VERSION ""

NS_ :

BS_:

BU_: EHVC VESS SBWS EGP OBC LDC MCU BMS VCU CGW ECALL HVAC ACU SKM EBU TESTER BCM
VAL_TABLE_ VCU_Shift_CTRL_STS_WRN_MSG 6 "Check Gear shift control system" 5 "Charging Door open" 4 "Unplug vehicle to start" 3 "Park Malfunction" 2 "Neutral engaged" 1 "Park engaged" 0 "Off" ;
VAL_TABLE_ VCU_Shift_COND_Unmatch_WRN_MSG 4 "Press brake pedal with P release switch" 3 "Shift to P after stopping" 2 "Press brake Pedal to change gear" 1 "Shifting Condition not met(Speed/RPM)" 0 "Off" ;
VAL_TABLE_ VCU_Charging_Sts_WRN_MSG 4 "Charging System Fault" 3 "Charging Cable Inlet Fault" 2 "DC Charging System Fault" 1 "AC Charging System Fault" 0 "Off" ;
VAL_TABLE_ VCU_LV_SYS_WRN_MSG 2 "Check the LV System" 1 "Aux. Battery Saver Activated" 0 "Off" ;
VAL_TABLE_ VCU_HV_PWR_LMT_WRN_MSG 3 "Power Limited" 2 "Charge Immediately" 1 "Traction Battery Low" 0 "Off" ;
VAL_TABLE_ Med_Min_Max 2 "Maximum" 1 "Minimum" 0 "Medium" ;
VAL_TABLE_ VCU_CMD_AC_CHARG_ST_REQ 2 "HaltCharging" 1 "StartCharging" 0 "StopCharging" ;
VAL_TABLE_ VessSoundSetSts 3 "Invalid" 2 "Sound2" 1 "Sound1" 0 "NotUsed" ;
VAL_TABLE_ VessSoundSetCmd 2 "Sound2" 1 "Sound1" 0 "NoActivation" ;
VAL_TABLE_ STPMStartCmd 145 "EngineStopCmd" 95 "EngineStartCmd" 0 "NoActivation" ;
VAL_TABLE_ STPMHvacCmd 3 "Full_Aircon" 2 "Full_Heater" 1 "Off" 0 "NoActivation" ;
VAL_TABLE_ SeatBeltSts_RR 2 "Unfasten, SBR on" 3 "Invalid" 1 "Fasten, SBR off" 0 "Unfasten, SBR off" ;
VAL_TABLE_ Error_Level_0_5_EGP 15 "Invalid" 5 "Lv5" 4 "Lv4" 3 "Lv3" 2 "Lv2" 1 "Lv1" 0 "Lv0" ;
VAL_TABLE_ HVAC_Max_Sts 3 "Invalid" 2 "Other_Mode" 1 "Full_Aircon_Mode" 0 "Full_Heater_Mode" ;
VAL_TABLE_ HP_Req 3 "None Heatpump" 1 "Heatpump On" 0 "Heatpump Off" ;
VAL_TABLE_ NotOK_OK 1 "OK" 0 "NotOK" ;
VAL_TABLE_ HvacDisplayMode 15 "Invalid" 13 "Auto Def" 12 "Auto Fdef" 11 "Auto Foot" 10 "Auto Bi" 9 "Auto Vent" 8 "Auto Off" 5 "Def" 4 "Fdef" 3 "Foot" 2 "Bi" 1 "Vent" 0 "Off" ;
VAL_TABLE_ HvacDisplayRecSts 3 "Invalid" 1 "Rec" 0 "Fresh" ;
VAL_TABLE_ HvacDisplayOffSts 3 "Invalid" 2 "All Display Off" 1 "Indicator On" 0 "Indicator Off" ;
VAL_TABLE_ Shifting_In_Progress 1 "Shifting" 0 "Not Shifting" ;
VAL_TABLE_ EGP_OperationMode 4 "Error" 3 "Ready" 1 "Standby" 0 "Sleep" ;
VAL_TABLE_ LDC_Out_Mode 2 "CP" 1 "CC" 0 "CV" ;
VAL_TABLE_ HVAC_MODE_DEF_STS 3 "Def Button" 2 "ADS" 1 "Start" 0 "Off" ;
VAL_TABLE_ Off_On_Invalid 3 "Invalid" 1 "On" 0 "Off" ;
VAL_TABLE_ EHVC_OP_Mode 15 "Mode15" 14 "Mode14" 13 "Mode13" 12 "Mode12" 11 "Mode11" 10 "Mode10" 9 "Mode9" 8 "Mode8" 7 "Mode7" 6 "Mode6" 5 "Mode5" 4 "Mode4" 3 "Mode3" 2 "Mode2" 1 "Mode1" 0 "NoActivation" ;
VAL_TABLE_ DrivingPosition 7 "Invalid" 4 "L" 3 "D" 2 "N" 1 "R" 0 "P" ;
VAL_TABLE_ ECO_Guide 31 "Invalid" 16 "Power Level 10" 15 "Power Level 9" 14 "Power Level 8" 13 "Power Level 7" 12 "Power Level 6" 11 "Power Level 5" 10 "Power Level 4" 9 "Power Level 3" 7 "Power Level 2" 6 "Power Level 1" 5 "Charging Level 5" 4 "Charging Level 4" 3 "Charging Level 3" 2 "Charging Level 2" 1 "Charging Level 1" 0 "0 Level" ;
VAL_TABLE_ REGEN_EXIT 5 "RBC Fail" 4 "ABS/ESC Act" 3 "quick turn" 2 "high decel or quick brake" 1 "wheel slip" 0 "No_Activation" ;
VAL_TABLE_ HVAC_Blower_STS 15 "Invalid" 8 "8Step(Max)" 7 "7Step" 6 "6Step" 5 "5Step" 4 "4Step" 3 "3Step" 2 "2Step" 1 "1Step(Low)" 0 "Off" ;
VAL_TABLE_ HVAC_Rec_STS 2 "Partial" 15 "Invalid" 1 "Rec" 0 "Fresh" ;
VAL_TABLE_ HVAC_Mode_STS 15 "Invalid" 5 "Def" 4 "FDef" 3 "Foot" 2 "Bi" 1 "Vent" 0 "Off" ;
VAL_TABLE_ DrivingModeE100_VCU 7 "Invalid" 3 "Eco+" 2 "Sports" 1 "Normal" 0 "Eco" ;
VAL_TABLE_ SBW_STS 1 "Service_Limphome" 0 "Normal" ;
VAL_TABLE_ REQ_COAST_REGEN_EXIT 1 "ExitCoastRegen1_Ramp1_ReturnLev1" 0 "NoActivation" ;
VAL_TABLE_ VCU_STS_Paddle_LV 15 "Invalid" 3 "3 Level" 2 "2 Level" 1 "1 Level" 0 "O Level" ;
VAL_TABLE_ SBW_WRN_MSG 15 "Invalid" 8 "ShiftLockSwitchCheck" 7 "ParkingReleaseSwitchCheck" 6 "ParingSwitchCheck" 5 "WhenNotUsingShiftLockSW" 4 "WhenNotUsingTheBrake" 3 "WhenConditionIsNotP" 2 "CanNotChangeGear" 1 "Service" 0 "Off" ;
VAL_TABLE_ PW_Virtual_Flag 3 "Invalid" 2 "Virtual" 1 "Actual" 0 "NoPedal" ;
VAL_TABLE_ AC_Charging_Ready 2 "Charging Finish" 1 "Ready" 0 "NotReady" ;
VAL_TABLE_ Pmotor_Position_Status 3 "Invalid" 2 "In Between" 1 "N" 0 "P" ;
VAL_TABLE_ TCU_transPmotorparkReq 3 "Invalid" 2 "Park Request" 1 "Unpark Request" 0 "NoRequest" ;
VAL_TABLE_ SBWS_Lever 15 "Invalid" 4 "L/M" 3 "D" 2 "N" 1 "R" 0 "P" ;
VAL_TABLE_ SBWS_SW 3 "Invalid" 2 "Stuck" 1 "On" 0 "Off" ;
VAL_TABLE_ LDC_STS_MODE 3 "Derating" 2 "Failure" 1 "Fault" 0 "Normal" ;
VAL_TABLE_ LDC_STS_Ready 2 "invalid" 1 "ready" 0 "not ready" ;
VAL_TABLE_ RBC_DEF 1 "Defective" 0 "Normal" ;
VAL_TABLE_ BBC_DEF 2 "Defective" 1 "Degraded" 0 "Normal" ;
VAL_TABLE_ REGEN_ENABLE_STS 1 "Enable" 0 "Inhitition" ;
VAL_TABLE_ BMS_CoolingPumpFeedbackStatus 7 "Normal working" 6 "RPM Mismatch" 5 "Over current" 4 "Over temp" 3 "STALL" 2 "Dry run signal" 1 "PWM Wire open" 0 "Not working" ;
VAL_TABLE_ BMS_BHC_STS_OW_TS 1 "abnormality" 0 "Normal state" ;
VAL_TABLE_ BMS_BHC_STS_ERR 2 "Heater Internal Error" 1 "HV Heater Relay Coil Error" 0 "no_error" ;
VAL_TABLE_ OBC_STS_CHECK_GROUP 8 "Temporary Stop Group" 7 "System Variable Group #2" 6 "System Variable Group #1" 5 "Warnnig Group #4" 4 "Warnnig Group #3" 3 "Warnnig Group #2" 2 "Warnnig Group #1" 1 "Fault Group" 0 "Default" ;
VAL_TABLE_ OBC_STS_PC_State 5 "CV Mode" 4 "CC(In) Mode" 3 "CC(Out) Mode" 2 "CP Mode" 1 "Hot Standby Mode" 0 "Idle Mode" ;
VAL_TABLE_ OBC_STS_SC_State 6 "Charge Finish Mode" 5 "Fault Mode" 4 "Charge Mode" 3 "Precharge Mode" 2 "Handshake Mode" 1 "Init Check Mode" 0 "Main Power Off Mode" ;
VAL_TABLE_ OBC_STS_Precharge_Step 5 "Precharging done(Init Done)" 4 "PFC stage enable step(Hot Stb)" 3 "Main Relay On step" 2 "Internal link check Step" 1 "HV Check Step" 0 "Idle Step" ;
VAL_TABLE_ VCU_STS_VEH_Mode 7 "Invalid" 4 "12V Battery Auto Charging Mode" 3 "Quick(DC) Charging Mode" 2 "Scheduled Charging Mode" 1 "Normal(AC) Charging Mode" 0 "Standby" ;
VAL_TABLE_ VCU_CMD_AC_CP 6 "Stage F(-12V)" 5 "Stage E(0V)" 4 "Stage D(3V)" 3 "Stage C(6V)" 2 "Stage B2(9V)" 1 "Stage B1(9V)" 0 "Stage A(0V)" ;
VAL_TABLE_ VCU_CMD_AC_PD 2 "Open (Switch Pushed)" 1 "Detected" 0 "Not Detected" ;
VAL_TABLE_ VCU_Ready 2 "Emergency(Blinking)" 1 "Ready" 0 "Not Ready" ;
VAL_TABLE_ ECO_Energy_Flow_IND 2 "Regenerative Braking" 1 "Motoring" 0 "Stop" ;
VAL_TABLE_ Charging_Sts_IND 7 "Invalid" 5 "ChargingFailure(RedFlash)" 4 "ChargingComplete(Green)" 2 "Connection_NoCharging_ScheduledChargSet(Blue)" 1 "Connection_NoCharging(Yellow)" 0 "NoConnection_NoCharging(Off)" 3 "DuringCharging(GreenFlash)" ;
VAL_TABLE_ Charging_Plug_STS 15 "Invalid" 2 "DC Plug Connected" 1 "AC Plug Connected" 0 "Disconnected" ;
VAL_TABLE_ Inhitition_Enable 1 "Enable" 0 "Inhitition" ;
VAL_TABLE_ RemoteStartSts 3 "Invalid" 1 "RemoteRunningSts" 0 "NormalState" ;
VAL_TABLE_ NICC_SystemSts 3 "Failure" 2 "Active" 1 "Ready" 0 "Off" ;
VAL_TABLE_ NICC_Opt 3 "Invalid" 2 "On" 1 "Off" 0 "NoOption" ;
VAL_TABLE_ noDetect_Detect 3 "Invalid" 1 "Detected" 0 "No" ;
VAL_TABLE_ VoiceHvacBlowerSetCmd 15 "NoAct_Invalid" 8 "8Step(Max)" 7 "7Step" 6 "6Step" 5 "5Step" 4 "4Step" 3 "3Step" 2 "2Step" 1 "1Step(Low)" 0 "Off" ;
VAL_TABLE_ VoiceHvacUpDnCmd 2 "DnStep" 1 "UpStep" 0 "NoActivation" ;
VAL_TABLE_ VoiceHvacAirCmd 2 "RecircleAir" 1 "FreshAir" 0 "NoActivation" ;
VAL_TABLE_ VoiceHvacCmd 6 "Defrost_On" 5 "Defrost_Off" 4 "HVAC_On_with_AC_ON" 3 "HVAC_On_with_AC_OFF" 2 "HVAC_On_with_AUTO" 1 "HVAC_OFF" 0 "NoActivation" ;
VAL_TABLE_ RemoteHvacCntrlFailReason 15 "NoFail" 14 "OtherReason" 3 "EngineStop" 2 "NormalRunningState" 1 "HvacAlreadyOff" 0 "HvacAlreayOn" ;
VAL_TABLE_ RemoteHvacCmd 2 "HvacOff" 1 "HvacOn" 0 "NoActivation" ;
VAL_TABLE_ RemoteHvacResp 3 "HVAC_OFF_Fail" 2 "HVAC_OFF_Success" 1 "HVAC_ON_Fail" 0 "HVAN_ON_Success" ;
VAL_TABLE_ NotUsed_Off_On 3 "Invalid" 2 "On" 1 "Off" 0 "NotUsed" ;
VAL_TABLE_ NoDisplayDisplay 1 "Display" 0 "NoDisplay" ;
VAL_TABLE_ LKASSetCmd 2 "LKAS(RKA)" 1 "LDWS" 0 "Default" ;
VAL_TABLE_ SetCmd 3 "Invalid" 2 "On" 1 "Off" 0 "Default" ;
VAL_TABLE_ ACC_Sw 3 "Invalid" 2 "Init" 1 "Pressed" 0 "NotPressed" ;
VAL_TABLE_ CF_Yrs_Type 1 "Yaw, Lateral, Longitudinal" 0 "Yaw, Lateral" ;
VAL_TABLE_ YRS_Temp_Stat 1 "Out -40 to 85" 0 "In -40 to 85" ;
VAL_TABLE_ CF_ISC_ResetStat 1 "ISC_ResetMode" 0 "NormalMode" ;
VAL_TABLE_ NoYes 1 "Yes" 0 "No" ;
VAL_TABLE_ VariantCode 3 "Default" 2 "Yes" 0 "No" ;
VAL_TABLE_ Rheo_Stat 0 "NoActivation" ;
VAL_TABLE_ ACC_Engine_Torque_Request 1 "Enable SCC torque request" 0 "No request" ;
VAL_TABLE_ ACC_DriveMode 3 "Dynamic" 2 "Normal" 1 "Comfort" 0 "Default" ;
VAL_TABLE_ ACC_Target_Validity 1 "Valid target vehicle" 0 "No target vehicle" ;
VAL_TABLE_ ACC_Disp_Information 7 "Display 'Takeover Request'" 6 "Display 'Disable to engage ACC'" 5 "Display 'ACC disengaged'" 4 "Display 'Available to resume acceleration control'" 3 "Display 'Object disappeared'" 2 "Reserved" 1 "Display 'ACC Mode'" 0 "Default" ;
VAL_TABLE_ ACC_StopReq 1 "Stop request" 0 "No request" ;
VAL_TABLE_ ACC_DrvSel_Distance 5 "Level#5" 4 "Level#4" 3 "Level#3" 2 "Level#2" 1 "Level#1" 0 "No time gap set" ;
VAL_TABLE_ ACC_WarningLamp 3 "ACC Service Required" 2 "System temporairy unavailable" 1 "Performance degredation" 0 "Normal state" ;
VAL_TABLE_ ACC_Mode 3 "Shutoff" 2 "Override" 1 "Engaged" 0 "Off" ;
VAL_TABLE_ ESCSetCmd 5 "Sand mode (reserved)" 4 "Mud mode (reserved)" 3 "Snow mode (reserved)" 2 "Off-road mode" 1 "Normal mode" 0 "Default" ;
VAL_TABLE_ FVSASetCmd 3 "Invalid" 2 "On" 1 "Off" 0 "Default" ;
VAL_TABLE_ ESC_Mode 5 "Sand mode (reserved)" 4 "Mud mode (reserved)" 3 "Snow mode (reserved)" 2 "Off-road mode" 1 "Normal mode" 0 "Default" ;
VAL_TABLE_ Default_8bit 255 "DefaultValue" ;
VAL_TABLE_ NoAct_Off_10s_20s_30s 4 "30sec" 3 "20sec" 2 "10sec" 1 "Off" 0 "NoActivation" ;
VAL_TABLE_ NoAct_Disable_Enable 2 "Enable" 1 "Disable" 0 "NoActivation" ;
VAL_TABLE_ PTGMode 3 "Invalid" 2 "ManualMode" 1 "PowerMode" 0 "Default" ;
VAL_TABLE_ DoorLockSpeedSetCmd 5 "50kph" 4 "40kph" 3 "30kph" 2 "20kph" 1 "10kph" 0 "NoActivation" ;
VAL_TABLE_ DoorUnlockSetCmd 3 "Parking" 2 "KeyOff" 1 "Off" 0 "NoActivation" ;
VAL_TABLE_ DoorLockSetCmd 3 "ExceptParking" 2 "Driving" 1 "Off" 0 "NoActivation" ;
VAL_TABLE_ NoAct_Off_On 2 "On" 1 "Off" 0 "NoActivation" ;
VAL_TABLE_ EPB_Fail_Info 5 "EPB Permanently Not Available" 4 "EPB Temporarily Not Available" 3 "EPB Diagnostic" 2 "EPB Initialization State" 1 "EPB No failure" ;
VAL_TABLE_ EPB_Status 7 "Applying in progress by switch" 6 "Releasing in progress by switch" 5 "Dynamic braking via EPB" 4 "Releasing in progress without switch" 3 "Applying in progress without switch" 2 "Applied" 1 "Released" 0 "Unknown" ;
VAL_TABLE_ EPB_Switch 3 "Failure" 2 "Release" 1 "Apply" 0 "Neutral" ;
VAL_TABLE_ EPB_Display 5 "Push_brake_pedal_to_release_EPB" 4 "Apply_brake_immediately" 3 "EPB applies by ESC request" 2 "Driver tries to DAR but safety condition is not satisfied" 1 "EPB is in maintenance mode" 0 "Off" ;
VAL_TABLE_ EPB_Alarm 2 "Uncomfortable tone" 1 "Comfortable tone (Sound once)" 0 "Off" ;
VAL_TABLE_ AVH_DIRVER_WARNING 3 "AVH cannot be activated. Close Door, Seatbelt, Hood, Trunk" 2 "Press Brake Pedal to Release AVH" 1 "AVH to be deactivated Press Brake Pedal" 0 "No_Warning" ;
VAL_TABLE_ AVH_LAMP_INFO 3 "AVH Ready (lamp is on as white)" 2 "AVH Active (lamp is on as green)" 1 "AVH Failure (lamp is on as yellow)" 0 "AVH Off" ;
VAL_TABLE_ AVH_CTL_STATUS 2 "AVH_being_released" 1 "AVH_Active" 0 "No_Apply" ;
VAL_TABLE_ Off_On_Flashing 2 "Flashing" 1 "On" 0 "Off" ;
VAL_TABLE_ KPH_MPH 1 "MPH" 0 "KPH" ;
VAL_TABLE_ Invalid_4bit 15 "Invalid" ;
VAL_TABLE_ Invalid_11bit 2047 "Invalid value" ;
VAL_TABLE_ NoError_Error 1 "Error" 0 "NoError" ;
VAL_TABLE_ NoAct_Act 1 "Activation" 0 "No_Activation" ;
VAL_TABLE_ Init_Invalid_8bit 255 "Invalid" 254 "Init" ;
VAL_TABLE_ Off_Low_High_Invalid 3 "Invalid" 2 "High" 1 "Low" 0 "Off" ;
VAL_TABLE_ Off_On_Init_Invalid 3 "Invalid" 2 "Init" 1 "On" 0 "Off" ;
VAL_TABLE_ I_range 2 "LIN_range_3" 1 "LIN_range_2" 0 "LIN_range_1" 3 "Invalid" ;
VAL_TABLE_ NoError_Error_Init_Invalid 3 "Invalid" 2 "Init" 1 "Error" 0 "NoError" ;
VAL_TABLE_ Invalid_14bit 16383 "Invalid" ;
VAL_TABLE_ Invalid_9bit 511 "Invalid" ;
VAL_TABLE_ Invalid_16bit 65535 "Invalid" ;
VAL_TABLE_ Disable_Enable 1 "enable" 0 "disable" ;
VAL_TABLE_ FCW_SwSet 4 "Early" 7 "Invalid" 3 "Normal" 2 "Late" 1 "Disable" 0 "Default" ;
VAL_TABLE_ Defaul_Off_On_Invalid 3 "Invalid" 2 "On" 1 "Off" 0 "Default" ;
VAL_TABLE_ NoFault_Fault 1 "Fault" 0 "NoFault" ;
VAL_TABLE_ Brake_Variant 5 "ESP+EPB+AEB+ACC" 4 "ESP+EPB+AEB" 3 "ESP+AEB" 2 "ESP+EPB" 1 "ESP" 0 "ABS" ;
VAL_TABLE_ Frt_Seat_Belt_Warning 2 "SBR_Activation" 1 "SBW_Activation" 0 "NoActivation" ;
VAL_TABLE_ ESP_CtrMode 3 "Particular_Mode" 2 "Output_Torque_Overlay_Mode" 1 "Sensor_Value_Overlay_Mode" 0 "Reserve" ;
VAL_TABLE_ Close_Open_B 3 "Invalid" 2 "Init" 1 "Open" 0 "Close" ;
VAL_TABLE_ Airbag_WL_Fb 7 "Lamp circuitry failure" 3 "ACU_msg_error" 2 "Flashing" 1 "ON" 0 "OFF" ;
VAL_TABLE_ Airbag_WL 3 "Invalid" 2 "Flashing" 1 "ON" 0 "OFF" ;
VAL_TABLE_ HVAC_Option 2 "DATC" 1 "MTC" ;
VAL_TABLE_ HVAC_Mode_Status 2 "DEF" 1 "MAX" 0 "otherwise" ;
VAL_TABLE_ HVAC_Temp_Status 2 "Hi_Temp" 1 "Lo_Temp" 0 "Otherwise" ;
VAL_TABLE_ NoDef_Def 1 "Defective" 0 "Not_Defective" ;
VAL_TABLE_ NoReqeust_Request 1 "Request" 0 "NoRequest" ;
VAL_TABLE_ Invalid_10bit 1023 "Invalid value" ;
VAL_TABLE_ NotReady_Ready 1 "ready" 0 "not_ready" ;
VAL_TABLE_ TMPI_S 11 "TPM_Warning_Flash" 10 "TPM_Warning_In_Learn_Mode" 9 "Normal_Operation_OFF" ;
VAL_TABLE_ TAS 2 "Tire_Pressure_Imbalanced" 1 "Tire_Pressure_Balanced" 0 "Unknown" ;
VAL_TABLE_ TPS 7 "Invalid" 5 "High_Pressure" 4 "Puncture" 3 "Low_Warning" 2 "Low_Service_Now(Alarm)" 1 "Nominal" 0 "Unknown" ;
VAL_TABLE_ Invalid_12bit 4095 "Invalid value" ;
VAL_TABLE_ Invalid_13bit 8191 "Invalid value" ;
VAL_TABLE_ Invalid_8bit 255 "Invalid value" ;
VAL_TABLE_ Lock_Unlock_Sts 1 "Unlock" 0 "Lock" ;
VAL_TABLE_ NM_Request_Function 1 "Request" 0 "Release" ;
VAL_TABLE_ ST_REQ 3 "ST_REQ2" 1 "ST_REQ1" 0 "No_activation" ;
VAL_TABLE_ DTCInfo 3 "Invalid_Value" 2 "DTCRecordingUnitDefect" 1 "DTC_Available" 0 "No_DTC_recorded" ;
VAL_TABLE_ NM_CommandCode 4 "Limphome" 2 "Ring" 1 "Alive" ;
VAL_TABLE_ NM_FormerState 5 "LocalMode10min" 4 "LocalMode1min" 3 "LocalMode10sec" 2 "LocalModeAfterNetwork" 1 "PowerSavingMode" 0 "NoInformation" ;
VAL_TABLE_ NM_WakeupReason 3 "BatteryAttachment" 2 "LocalWakeup" 1 "RemoteWakeup" 0 "UnknownReason" ;
VAL_TABLE_ NM_SleepFlag 3 "SleepACK" 1 "NwRelease" 0 "NwRequest" ;
VAL_TABLE_ Off_On 1 "ON" 0 "OFF" ;
VAL_TABLE_ SAS_CAL 1 "Calibrated" 0 "Not Calibrated" ;
VAL_TABLE_ SAS_OK 1 "OK" 0 "Not OK" ;
VAL_TABLE_ ESP_KL 3 "ESP Warning Lamp Flashing_Active" 1 "ESP Warning Lamp On_System fault" 0 "ESP Lamp off" ;
VAL_TABLE_ VC_DriverHandle 3 "Default(Virgin)" 1 "Right Hand Drive" 0 "Left Hand Drive" ;
VAL_TABLE_ CPL_TQ_LIMIT 64255 "64255Nm" 0 "0" ;
VAL_TABLE_ RQ_Clutch_OP 3 "error" 2 "torque limit " 1 "clutch off" 0 "passive " ;
VAL_TABLE_ EBS_STATUS 3 "TCSactiveflag(TCScontrol=active)" 2 "ESPactiveflag(ESPcontro=active)" 1 "ABSactiveflag(ABScontrol=active)" 0 "normal mode" ;
VAL_TABLE_ Eng_Lamp_status 1 "symbol fault" 0 "symbol not fault" ;
VAL_TABLE_ Immofault 2 "Flashing" 1 "On" 0 "Off" ;
VAL_TABLE_ NoFail_Fail 1 "fail" 0 "no fail" ;
VAL_TABLE_ SeatBeltSts_FRT 3 "Invalid" 1 "Fasten" 0 "Unfasten" ;
VAL_TABLE_ NoAct_Act_Invalid 3 "Invalid" 1 "Activation" 0 "No_Activation" ;
VAL_TABLE_ VCU_STS_CHARG_PLG_AT_Lock_SW 3 "Invalid" 2 "Init" 1 "Lock" 0 "Auto" ;
VAL_TABLE_ IG_S 1 "ignition on" 0 "ignition off" ;
VAL_TABLE_ DOM_EXP 2 "EU export vehicle" 1 "general export vehicle" 0 "domestic vehicle" ;
VAL_TABLE_ VC_PF 22 "E100" ;
VAL_TABLE_ SMC_E_S 7 "signal not valid" 3 "charging" 2 "running" 1 "soft start" 0 "stopped" ;
VAL_TABLE_ BRAKE_ON 3 "signal not valid" 2 "not defined" 1 "brake operated" 0 "brake not operated" ;
VAL_TABLE_ TMPIR 3 "Alert_Level_3" 0 "No_Indication" ;
VAL_TABLE_ Valid_Invalid 1 "Invalid" 0 "Valid" ;
VAL_TABLE_ HDC_FL_WL 3 "not defined" 2 "blinking" 1 "turn on" 0 "turn off" ;
VAL_TABLE_ SFB 3 "signal not available" 2 "not defined_03" 1 "not defined_02" 0 "not defined_01" ;
VAL_TABLE_ DRTGHL 3 "DHL signal = invalid" 2 "not defined_02" 1 "not defined_01" 0 "DHL signal = valid" ;
VAL_TABLE_ DRTGHR 3 "DHR signal = invalid" 2 "not defined_02" 1 "not defined_01" 0 "DHR signal = valid" ;
VAL_TABLE_ ANFN 3 "not defined_03" 2 "no request" 1 "not defined_02" 0 "not defined_01" ;
VAL_TABLE_ SZS 3 "emission test mode" 2 "not defined" 1 "normal operation" 0 "disable ESP function or diag. mode" ;
VAL_TABLE_ TM_AUS 1 "auto cruise off rerquest" 0 "normal" ;
VAL_TABLE_ DRTGTM 3 "TM_DL signal = invalid" 2 "not defined_02" 1 "not defined_01" 0 "TM_DL signal = valid" ;
VAL_TABLE_ DRTGVR 3 "DVR signal = invalid" 2 "not defined_02" 1 "not defined_01" 0 "DVR signal = valid" ;
VAL_TABLE_ DRTGVL 3 "DVL signal = invalid" 2 "not defined_02" 1 "not defined_01" 0 "DVL signal = valid" ;
VAL_TABLE_ EBD_KL 1 "EBD W/L ON" 0 "EBD W/L OFF" ;
VAL_TABLE_ ABS_KL 1 "ABS W/L ON" 0 "ABS W/L OFF" ;

BO_ 3221225472 VECTOR__INDEPENDENT_SIG_MSG: 0 Vector__XXX
 SG_ IgnitionSts : 0|2@0+ (1,0) [0|3] "" Vector__XXX
 SG_ SafetyUnlockSetSts : 0|1@0+ (1,0) [0|1] "" Vector__XXX
 SG_ ACC_RequiredAccel : 0|11@0+ (0.01,-10.23) [-10.23|10.24] "m/s^2" Vector__XXX
 SG_ ESCSetCmd : 0|3@0+ (1,0) [0|7] "" Vector__XXX
 SG_ TCU_ISGStat_allow_PA : 0|1@0+ (1,0) [0|1] "" Vector__XXX
 SG_ ACC_StopReq : 0|1@0+ (1,0) [0|1] "" Vector__XXX
 SG_ DGN_REQ_SAS : 0|64@0+ (1,0) [0|0] "" Vector__XXX
 SG_ ALT_FB : 0|8@0+ (0.4,0) [0|100] "%" Vector__XXX
 SG_ TCU_ISGStat_ready : 0|1@0+ (1,0) [0|1] "" Vector__XXX
 SG_ TCU_Cal_1 : 0|64@0+ (1,0) [0|0] "" Vector__XXX
 SG_ NTURBINE : 0|16@0+ (1,0) [0|65535] "1/min" Vector__XXX
 SG_ MABS_SW_ANFB : 0|16@0+ (1,0) [0|65535] "1nm" Vector__XXX
 SG_ VB : 0|16@0+ (0.1,0) [0|6553.5] "uL/100ms" Vector__XXX
 SG_ T_MOT : 0|8@0+ (1,-40) [-40|215] "deg C." Vector__XXX

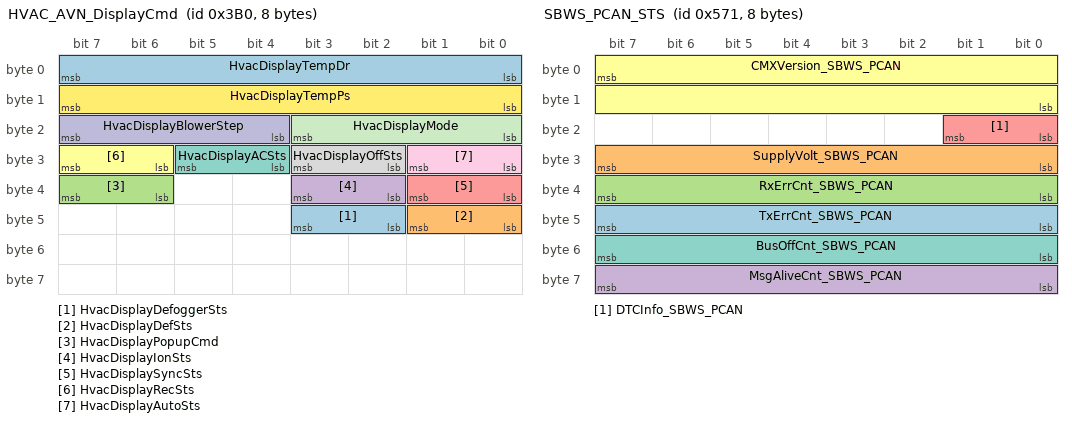
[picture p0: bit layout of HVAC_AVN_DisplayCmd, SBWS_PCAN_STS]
BO_ 944 HVAC_AVN_DisplayCmd: 8 HVAC
 SG_ HvacDisplayDefoggerSts : 43|2@0+ (1,0) [0|3] ""  CGW
 SG_ HvacDisplayDefSts : 41|2@0+ (1,0) [0|3] ""  CGW
 SG_ HvacDisplayPopupCmd : 39|2@0+ (1,0) [0|3] ""  CGW
 SG_ HvacDisplayIonSts : 35|2@0+ (1,0) [0|3] ""  CGW
 SG_ HvacDisplaySyncSts : 33|2@0+ (1,0) [0|3] ""  CGW
 SG_ HvacDisplayRecSts : 31|2@0+ (1,0) [0|3] ""  CGW
 SG_ HvacDisplayACSts : 29|2@0+ (1,0) [0|3] ""  CGW
 SG_ HvacDisplayOffSts : 27|2@0+ (1,0) [0|3] ""  CGW
 SG_ HvacDisplayAutoSts : 25|2@0+ (1,0) [0|3] ""  CGW
 SG_ HvacDisplayBlowerStep : 23|4@0+ (1,0) [0|15] ""  CGW
 SG_ HvacDisplayMode : 19|4@0+ (1,0) [0|15] ""  CGW
 SG_ HvacDisplayTempPs : 15|8@0+ (0.5,17.5) [17.5|32.5] "deg Cel."  CGW
 SG_ HvacDisplayTempDr : 7|8@0+ (0.5,17.5) [17.5|32.5] "deg Cel."  CGW

BO_ 1732 MCU_CAL_RESP: 8 MCU
 SG_ MCU_Calibration_Resp : 7|64@0+ (1,0) [0|0] ""  CGW

BO_ 1668 MCU_CAL_REQ: 8 CGW
 SG_ MCU_Calibration_Req : 7|64@0+ (1,0) [0|0] ""  MCU

BO_ 807 MCU_327h: 8 MCU
 SG_ MCU_PowerConsumption : 33|10@0+ (1,-300) [-300|300] "kW"  VCU,CGW
 SG_ HighPowerVoltage : 18|11@0+ (1,0) [0|2046] "V"  CGW
 SG_ HighPowerCurrent : 5|14@0+ (0.25,-2048) [-2046|2046] "A"  CGW
 SG_ MCU_Service_WRN_IND : 6|1@0+ (1,0) [0|1] ""  CGW,VCU

BO_ 1393 SBWS_PCAN_STS: 8 SBWS
 SG_ TxErrCnt_SBWS_PCAN : 47|8@0+ (1,0) [0|255] "" Vector__XXX
 SG_ SupplyVolt_SBWS_PCAN : 31|8@0+ (0.1,0) [0|25.5] "V" Vector__XXX
 SG_ RxErrCnt_SBWS_PCAN : 39|8@0+ (1,0) [0|255] "" Vector__XXX
 SG_ MsgAliveCnt_SBWS_PCAN : 63|8@0+ (1,0) [0|255] "" Vector__XXX
 SG_ DTCInfo_SBWS_PCAN : 17|2@0+ (1,0) [0|3] "" Vector__XXX
 SG_ CMXVersion_SBWS_PCAN : 7|16@0+ (1,0) [0|65535] "" Vector__XXX
 SG_ BusOffCnt_SBWS_PCAN : 55|8@0+ (1,0) [0|255] "" Vector__XXX

BO_ 1913 SBWS_DGN_RESP: 8 SBWS
 SG_ DGN_SBWS_RESP : 7|64@0+ (1,0) [0|0] ""  CGW

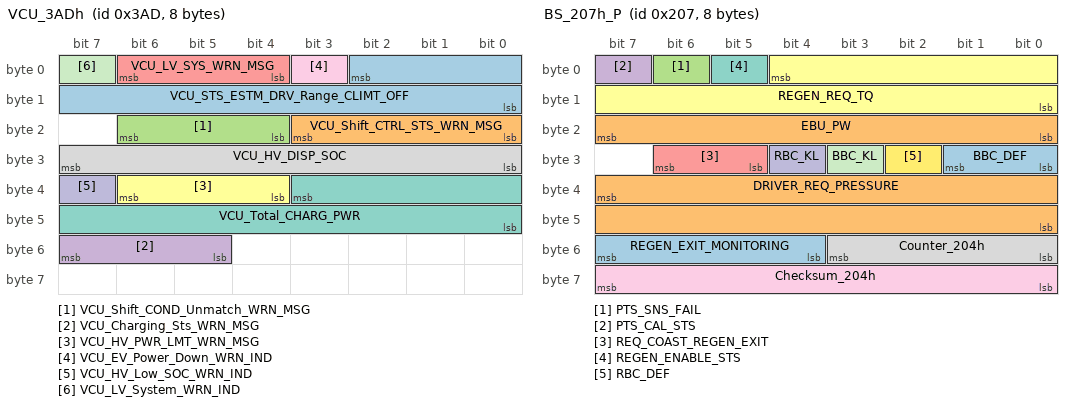
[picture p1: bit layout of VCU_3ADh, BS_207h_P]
BO_ 941 VCU_3ADh: 8 VCU
 SG_ VCU_STS_ESTM_DRV_Range_CLIMT_OFF : 2|11@0+ (1,0) [0|2000] "km"  CGW
 SG_ VCU_Shift_CTRL_STS_WRN_MSG : 19|4@0+ (1,0) [0|6] ""  CGW
 SG_ VCU_Shift_COND_Unmatch_WRN_MSG : 22|3@0+ (1,0) [0|4] ""  CGW
 SG_ VCU_Charging_Sts_WRN_MSG : 55|3@0+ (1,0) [0|4] ""  CGW
 SG_ VCU_LV_SYS_WRN_MSG : 6|3@0+ (1,0) [0|2] ""  CGW
 SG_ VCU_HV_PWR_LMT_WRN_MSG : 38|3@0+ (1,0) [0|3] ""  CGW
 SG_ VCU_Total_CHARG_PWR : 35|12@0+ (0.1,0) [0|255] "kW"  CGW
 SG_ VCU_HV_DISP_SOC : 31|8@0+ (1,0) [0|100] "%"  CGW
 SG_ VCU_EV_Power_Down_WRN_IND : 3|1@0+ (1,0) [0|1] ""  CGW
 SG_ VCU_HV_Low_SOC_WRN_IND : 39|1@0+ (1,0) [0|1] ""  CGW
 SG_ VCU_LV_System_WRN_IND : 7|1@0+ (1,0) [0|1] ""  CGW

BO_ 851 BMS_353h: 8 BMS
 SG_ BMS_BHC_Power : 23|16@0+ (1,0) [0|65535] "W"  BMS
 SG_ BMS_InstantPowerConsumption : 7|16@0+ (0.1,-400) [-400|400] "kW"  CGW

BO_ 882 CGW_372h: 8 CGW
 SG_ GoodbyeSoundCmd : 7|2@0+ (1,0) [0|3] ""  VESS
 SG_ WelcomeSoundCmd : 5|2@0+ (1,0) [0|3] ""  VESS
 SG_ HazardSw : 1|1@0+ (1,0) [0|1] ""  VCU
 SG_ HeadLampHighSts : 0|1@0+ (1,0) [0|1] ""  VCU
 SG_ RainDetected : 3|2@0+ (1,0) [0|3] ""  HVAC

BO_ 836 VESS_344h: 8 VESS
 SG_ VessSoundSetSts : 5|2@0+ (1,0) [0|3] ""  CGW
 SG_ VesstWarnCmd : 1|2@0+ (1,0) [0|1] ""  CGW
 SG_ VessWelcomeOnOffSetSts : 3|2@0+ (1,0) [0|3] ""  CGW

BO_ 1394 VESS_PCAN_STS: 8 VESS
 SG_ MsgAliveCnt_VESS_PCAN : 63|8@0+ (1,0) [0|255] "" Vector__XXX
 SG_ BusOffCnt_VESS_PCAN : 55|8@0+ (1,0) [0|255] "" Vector__XXX
 SG_ TxErrCnt_VESS_PCAN : 47|8@0+ (1,0) [0|255] "" Vector__XXX
 SG_ RxErrCnt_VESS_PCAN : 39|8@0+ (1,0) [0|255] "" Vector__XXX
 SG_ SupplyVolt_VESS_PCAN : 31|8@0+ (0.1,0) [0|25.5] "V" Vector__XXX
 SG_ DTCInfo_VESS_PCAN : 17|2@0+ (1,0) [0|3] ""  CGW
 SG_ CMXVersion_VESS_PCAN : 7|16@0+ (1,0) [0|65535] "" Vector__XXX

BO_ 1905 SBWS_DGN_REQ: 8 CGW
 SG_ DGN_SBWS_REQ : 7|64@0+ (1,0) [0|0] ""  SBWS

BO_ 854 HVAC_356h: 8 HVAC
 SG_ HVAC_Sensor_DUCT : 39|16@0+ (0.1,-40) [-40|100] "del Cel."  EHVC
 SG_ HVAC_Sensor_EVA : 23|16@0+ (0.1,-40) [-40|100] "del Cel."  EHVC
 SG_ HVAC_Sensor_SUN : 15|8@0+ (5,0) [0|1270] "W2/m"  EHVC
 SG_ HVAC_Sensor_AMB : 55|16@0+ (0.1,-40) [-40|100] "del Cel."  EHVC
 SG_ HVAC_Sensor_ADS : 7|8@0+ (1,0) [0|100] "%"  EHVC

BO_ 492 EHVC_1ECh: 8 EHVC
 SG_ AC_REF_OutHEX_Temp : 31|8@0+ (1,-40) [-40|214] "del Cel."  HVAC
 SG_ AC_REF_Low_Temp : 23|8@0+ (1,-40) [-40|214] "del Cel."  HVAC
 SG_ AC_REF_Low_Pressure : 33|10@0+ (0.1,0) [0|102.4] "bar"  HVAC
 SG_ AC_REF_High_Temp : 7|8@0+ (1,-40) [-40|214] "del Cel."  HVAC

BO_ 1894 EHVC_DGN_REQ: 8 CGW
 SG_ DGN_REQ_EHVC : 7|64@0+ (1,0) [0|0] ""  EHVC

BO_ 1893 EGP_DGN_REQ: 8 CGW
 SG_ DGN_REQ_EGP : 7|64@0+ (1,0) [0|0] ""  EGP

BO_ 1892 OBC_DGN_REQ: 8 CGW
 SG_ DGN_REQ_OBC : 7|64@0+ (1,0) [0|0] ""  OBC

BO_ 1891 LDC_DGN_REQ: 8 CGW
 SG_ DGN_REQ_LDC : 7|64@0+ (1,0) [0|0] ""  LDC

BO_ 1890 MCU_DGN_REQ: 8 CGW
 SG_ DGN_REQ_MCU : 7|64@0+ (1,0) [0|0] ""  MCU

BO_ 1889 BMS_DGN_REQ: 8 CGW
 SG_ DGN_REQ_BMS : 7|64@0+ (1,0) [0|0] ""  BMS

BO_ 1857 VESS_DGN_REQ: 8 CGW
 SG_ DGN_REQ_VESS : 7|64@0+ (1,0) [0|0] ""  VESS

BO_ 491 EHVC_1EBh: 8 EHVC
 SG_ Cabin_HTR_Power : 17|10@0+ (20,0) [0|20440] "W"  VCU
 SG_ AC_REF_High_Pressure : 7|10@0+ (0.1,0) [0|102.4] "bar"  HVAC,VCU

BO_ 519 BS_207h_P: 8 EBU
 SG_ REGEN_EXIT_MONITORING : 55|4@0+ (1,0) [0|16] ""  VCU
 SG_ DRIVER_REQ_PRESSURE : 39|16@0+ (0.1,0) [0|6553.5] "bar"  VCU
 SG_ PTS_SNS_FAIL : 6|1@0+ (1,0) [0|1] ""  MCU,VCU
 SG_ PTS_CAL_STS : 7|1@0+ (1,0) [0|1] "" Vector__XXX
 SG_ REQ_COAST_REGEN_EXIT : 30|2@0+ (1,0) [0|3] ""  VCU
 SG_ REGEN_REQ_TQ : 4|13@0+ (1,-500) [-500|7691] "Nm"  VCU
 SG_ REGEN_ENABLE_STS : 5|1@0+ (1,0) [0|1] ""  MCU,VCU
 SG_ Counter_204h : 51|4@0+ (1,0) [0|15] ""  VCU
 SG_ Checksum_204h : 63|8@0+ (1,0) [0|255] ""  VCU
 SG_ RBC_KL : 28|1@0+ (1,0) [0|1] "" Vector__XXX
 SG_ BBC_KL : 27|1@0+ (1,0) [0|1] "" Vector__XXX
 SG_ RBC_DEF : 26|1@0+ (1,0) [0|1] ""  VCU
 SG_ BBC_DEF : 25|2@0+ (1,0) [0|3] "" Vector__XXX
 SG_ EBU_PW : 23|8@0+ (1,0) [0|100] "%"  MCU,VCU

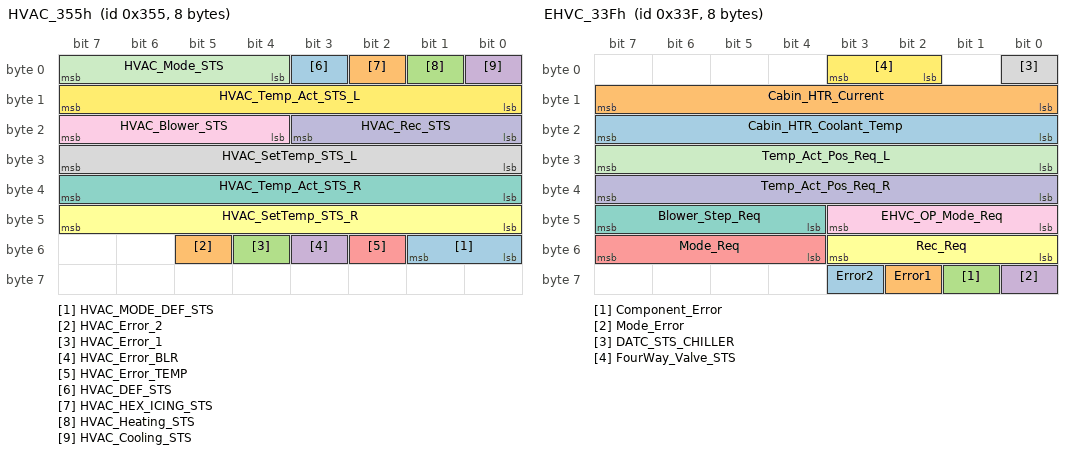
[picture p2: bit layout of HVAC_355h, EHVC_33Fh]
BO_ 853 HVAC_355h: 8 HVAC
 SG_ HVAC_MODE_DEF_STS : 49|2@0+ (1,0) [0|3] ""  EHVC
 SG_ HVAC_Error_2 : 53|1@0+ (1,0) [0|3] ""  EHVC
 SG_ HVAC_Error_1 : 52|1@0+ (1,0) [0|3] ""  EHVC
 SG_ HVAC_Error_BLR : 51|1@0+ (1,0) [0|3] ""  EHVC
 SG_ HVAC_Error_TEMP : 50|1@0+ (1,0) [0|3] ""  EHVC
 SG_ HVAC_SetTemp_STS_R : 47|8@0+ (0.5,17.5) [17.5|32.5] "del Cel."  EHVC
 SG_ HVAC_Temp_Act_STS_R : 39|8@0+ (1,0) [0|100] "%"  VCU,EHVC
 SG_ HVAC_SetTemp_STS_L : 31|8@0+ (0.5,17.5) [17.5|32.5] "del Cel."  EHVC
 SG_ HVAC_Blower_STS : 23|4@0+ (1,0) [0|3] ""  EHVC
 SG_ HVAC_Rec_STS : 19|4@0+ (1,0) [0|3] ""  EHVC
 SG_ HVAC_Mode_STS : 7|4@0+ (1,0) [0|15] ""  EHVC
 SG_ HVAC_Temp_Act_STS_L : 15|8@0+ (1,0) [0|100] "&"  VCU,EHVC
 SG_ HVAC_DEF_STS : 3|1@0+ (1,0) [0|1] ""  VCU
 SG_ HVAC_HEX_ICING_STS : 2|1@0+ (1,0) [0|1] ""  VCU
 SG_ HVAC_Heating_STS : 1|1@0+ (1,0) [0|1] ""  VCU
 SG_ HVAC_Cooling_STS : 0|1@0+ (1,0) [0|1] ""  VCU

BO_ 831 EHVC_33Fh: 8 EHVC
 SG_ Error2 : 59|1@0+ (1,0) [0|1] ""  HVAC
 SG_ Error1 : 58|1@0+ (1,0) [0|1] ""  HVAC
 SG_ Component_Error : 57|1@0+ (1,0) [0|1] ""  HVAC
 SG_ Mode_Error : 56|1@0+ (1,0) [0|1] ""  HVAC
 SG_ Mode_Req : 55|4@0+ (1,0) [0|15] ""  HVAC
 SG_ Rec_Req : 51|4@0+ (1,0) [0|15] ""  HVAC
 SG_ Blower_Step_Req : 47|4@0+ (1,0) [0|15] ""  HVAC
 SG_ DATC_STS_CHILLER : 0|1@0+ (1,0) [0|1] ""  VCU
 SG_ EHVC_OP_Mode_Req : 43|4@0+ (1,0) [0|15] ""  HVAC
 SG_ Temp_Act_Pos_Req_R : 39|8@0+ (1,0) [0|100] "%"  HVAC
 SG_ Temp_Act_Pos_Req_L : 31|8@0+ (1,0) [0|100] "%"  HVAC
 SG_ FourWay_Valve_STS : 3|2@0+ (1,0) [0|3] ""  HVAC
 SG_ Cabin_HTR_Coolant_Temp : 23|8@0+ (1,-40) [-40|214] "deg Cel"  HVAC
 SG_ Cabin_HTR_Current : 15|8@0+ (0.25,0) [0|63.5] "A"  CGW,VCU

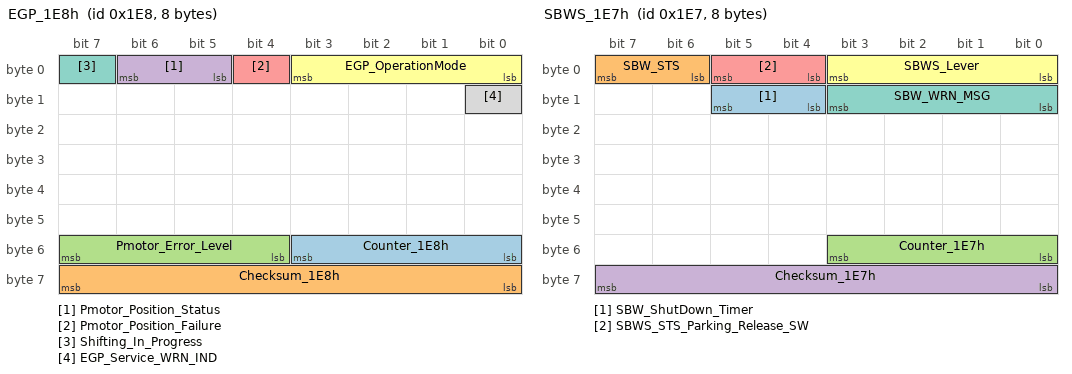
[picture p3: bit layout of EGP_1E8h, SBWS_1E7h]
BO_ 488 EGP_1E8h: 8 EGP
 SG_ Counter_1E8h : 51|4@0+ (1,0) [0|15] ""  VCU
 SG_ Checksum_1E8h : 63|8@0+ (1,0) [0|255] ""  VCU
 SG_ Pmotor_Error_Level : 55|4@0+ (1,0) [0|15] ""  VCU
 SG_ Pmotor_Position_Status : 6|2@0+ (1,0) [0|5] ""  VCU
 SG_ Pmotor_Position_Failure : 4|1@0+ (1,0) [0|1] ""  VCU
 SG_ EGP_OperationMode : 3|4@0+ (1,0) [0|15] ""  VCU
 SG_ Shifting_In_Progress : 7|1@0+ (1,0) [0|1] ""  VCU
 SG_ EGP_Service_WRN_IND : 8|1@0+ (1,0) [0|1] ""  CGW,VCU

BO_ 487 SBWS_1E7h: 8 SBWS
 SG_ SBW_ShutDown_Timer : 13|2@0+ (1,0) [0|1] ""  VCU
 SG_ SBW_STS : 7|2@0+ (1,0) [0|1] ""  VCU
 SG_ Counter_1E7h : 51|4@0+ (1,0) [0|15] ""  VCU
 SG_ Checksum_1E7h : 63|8@0+ (1,0) [0|255] ""  VCU
 SG_ SBWS_STS_Parking_Release_SW : 5|2@0+ (1,0) [0|3] ""  VCU
 SG_ SBWS_Lever : 3|4@0+ (1,0) [0|15] ""  VCU
 SG_ SBW_WRN_MSG : 11|4@0+ (1,0) [0|15] ""  VCU,CGW

BO_ 929 LDC_3A1h: 8 LDC
 SG_ LDC_STS_CURR_OUT : 39|16@0+ (0.1,0) [0|1000] "A"  VCU
 SG_ LDC_STS_CURR_IN : 31|8@0+ (0.1,0) [0|25] "A"  VCU
 SG_ LDC_STS_VOLT_OUT : 23|8@0+ (0.1,0) [0|25] "V"  VCU
 SG_ LDC_STS_VOLT_IN : 7|16@0+ (0.1,0) [0|1000] "V"  VCU

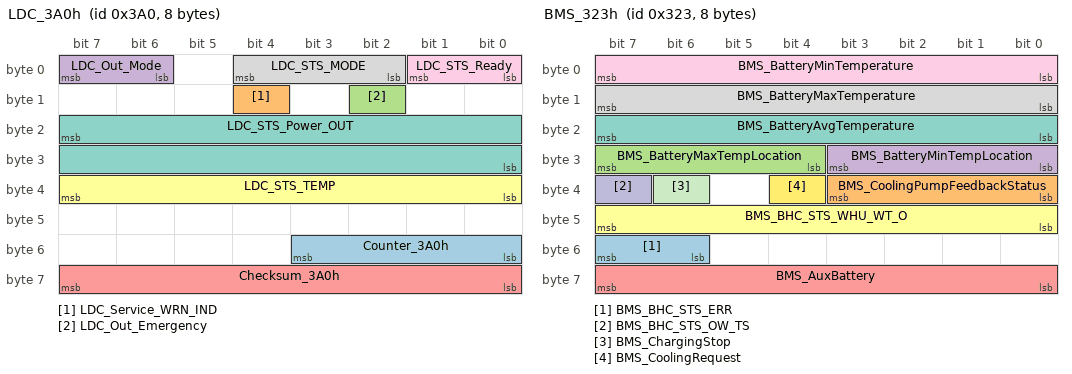
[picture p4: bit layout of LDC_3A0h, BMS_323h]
BO_ 928 LDC_3A0h: 8 LDC
 SG_ Counter_3A0h : 51|4@0+ (1,0) [0|15] ""  VCU
 SG_ LDC_Service_WRN_IND : 12|1@0+ (1,0) [0|1] ""  CGW,VCU
 SG_ LDC_Out_Emergency : 10|1@0+ (1,0) [0|1] ""  CGW,VCU
 SG_ LDC_Out_Mode : 7|2@0+ (1,0) [0|2] ""  VCU
 SG_ Checksum_3A0h : 63|8@0+ (1,0) [0|255] ""  VCU
 SG_ LDC_STS_TEMP : 39|8@0+ (1,-40) [-40|200] "del Cel"  VCU
 SG_ LDC_STS_Power_OUT : 23|16@0+ (1,0) [0|1800] "W"  CGW,VCU
 SG_ LDC_STS_MODE : 4|3@0+ (1,0) [0|3] ""  VCU
 SG_ LDC_STS_Ready : 1|2@0+ (1,0) [0|2] ""  VCU

BO_ 803 BMS_323h: 8 BMS
 SG_ BMS_BHC_STS_ERR : 55|2@0+ (1,0) [0|2] "" Vector__XXX
 SG_ BMS_CoolingPumpFeedbackStatus : 35|4@0+ (1,0) [0|7] "" Vector__XXX
 SG_ BMS_BatteryMaxTempLocation : 31|4@0+ (1,0) [0|10] "" Vector__XXX
 SG_ BMS_BatteryMinTempLocation : 27|4@0+ (1,0) [0|10] "" Vector__XXX
 SG_ BMS_AuxBattery : 63|8@0+ (0.1,0) [0|19] "V" Vector__XXX
 SG_ BMS_BHC_STS_WHU_WT_O : 47|8@0+ (0.6,-40) [-40|112.4] "deg Cel" Vector__XXX
 SG_ BMS_BatteryAvgTemperature : 23|8@0+ (1,-40) [-40|210] "deg Cel"  HVAC,EHVC
 SG_ BMS_BatteryMaxTemperature : 15|8@0+ (1,-40) [-40|210] "deg Cel"  HVAC,EHVC
 SG_ BMS_BatteryMinTemperature : 7|8@0+ (1,-40) [-40|210] "deg Cel"  HVAC,EHVC
 SG_ BMS_BHC_STS_OW_TS : 39|1@0+ (1,0) [0|1] "" Vector__XXX
 SG_ BMS_ChargingStop : 38|1@0+ (1,0) [0|1] "" Vector__XXX
 SG_ BMS_CoolingRequest : 36|1@0+ (1,0) [0|1] ""  EHVC

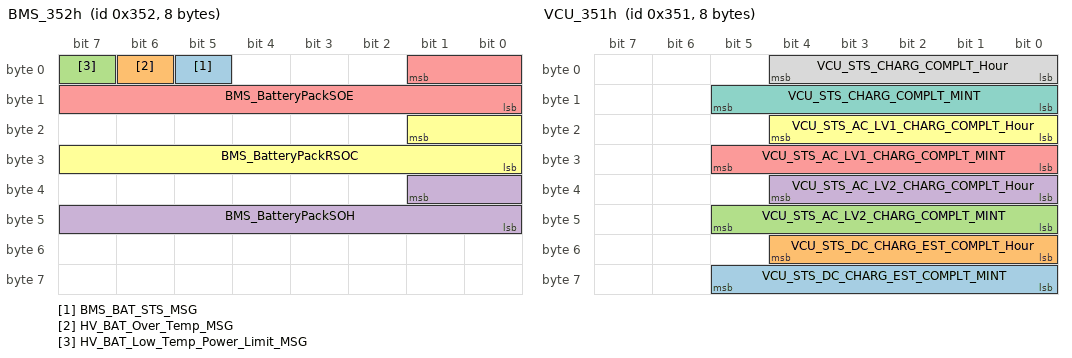
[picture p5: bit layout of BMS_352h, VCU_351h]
BO_ 850 BMS_352h: 8 BMS
 SG_ BMS_BAT_STS_MSG : 5|1@0+ (1,0) [0|1] ""  CGW
 SG_ HV_BAT_Over_Temp_MSG : 6|1@0+ (1,0) [0|1] ""  CGW
 SG_ HV_BAT_Low_Temp_Power_Limit_MSG : 7|1@0+ (1,0) [0|1] ""  CGW
 SG_ BMS_BatteryPackSOH : 33|10@0+ (0.1,0) [0|100] "%"  VCU,CGW
 SG_ BMS_BatteryPackSOE : 1|10@0+ (0.1,0) [0|65] "kWh"  VCU,CGW
 SG_ BMS_BatteryPackRSOC : 17|10@0+ (0.1,0) [0|100] "%"  VCU,CGW

BO_ 849 VCU_351h: 8 VCU
 SG_ VCU_STS_DC_CHARG_EST_COMPLT_MINT : 61|6@0+ (1,0) [0|59] "minute"  CGW
 SG_ VCU_STS_DC_CHARG_EST_COMPLT_Hour : 52|5@0+ (1,0) [0|31] "clock"  CGW
 SG_ VCU_STS_AC_LV2_CHARG_COMPLT_MINT : 45|6@0+ (1,0) [0|59] "minute"  CGW
 SG_ VCU_STS_AC_LV2_CHARG_COMPLT_Hour : 36|5@0+ (1,0) [0|31] "clock"  CGW
 SG_ VCU_STS_AC_LV1_CHARG_COMPLT_MINT : 29|6@0+ (1,0) [0|59] "minute"  CGW
 SG_ VCU_STS_AC_LV1_CHARG_COMPLT_Hour : 20|5@0+ (1,0) [0|31] "clock"  CGW
 SG_ VCU_STS_CHARG_COMPLT_MINT : 13|6@0+ (1,0) [0|59] "minute"  CGW
 SG_ VCU_STS_CHARG_COMPLT_Hour : 4|5@0+ (1,0) [0|31] "clock"  CGW

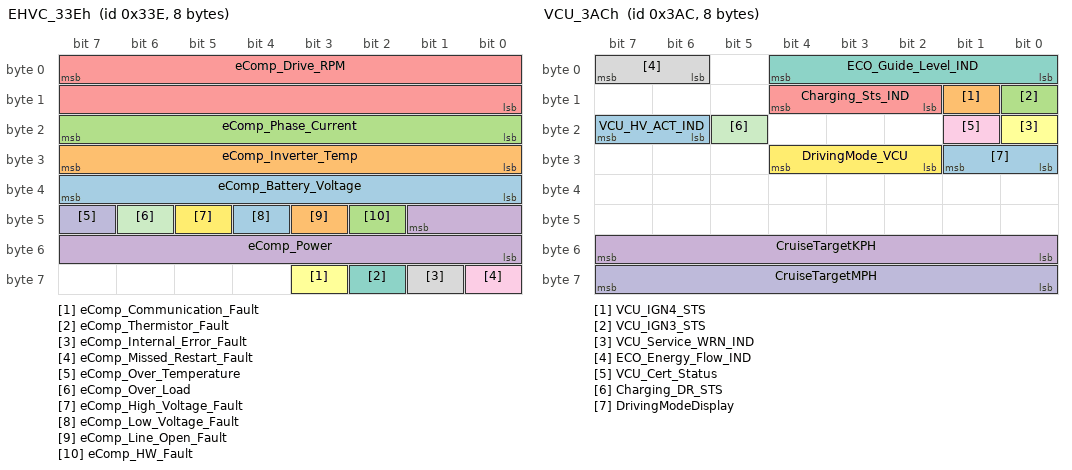
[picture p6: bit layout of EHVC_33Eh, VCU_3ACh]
BO_ 830 EHVC_33Eh: 8 EHVC
 SG_ eComp_Battery_Voltage : 39|8@0+ (2,0) [0|508] ""  VCU
 SG_ eComp_Inverter_Temp : 31|8@0+ (1,-40) [-40|150] "del Cel"  VCU
 SG_ eComp_Phase_Current : 23|8@0+ (0.1,0) [0|25.4] "A"  VCU
 SG_ eComp_Power : 41|10@0+ (10,0) [0|10230] "W"  VCU
 SG_ eComp_Drive_RPM : 7|16@0+ (1,0) [0|9000] "r/min"  VCU
 SG_ eComp_Communication_Fault : 59|1@0+ (1,0) [0|1] ""  HVAC
 SG_ eComp_Thermistor_Fault : 58|1@0+ (1,0) [0|1] ""  HVAC
 SG_ eComp_Internal_Error_Fault : 57|1@0+ (1,0) [0|1] ""  HVAC
 SG_ eComp_Missed_Restart_Fault : 56|1@0+ (1,0) [0|1] ""  HVAC
 SG_ eComp_Over_Temperature : 47|1@0+ (1,0) [0|1] ""  HVAC
 SG_ eComp_Over_Load : 46|1@0+ (1,0) [0|1] ""  HVAC
 SG_ eComp_High_Voltage_Fault : 45|1@0+ (1,0) [0|1] ""  HVAC
 SG_ eComp_Low_Voltage_Fault : 44|1@0+ (1,0) [0|1] ""  HVAC
 SG_ eComp_Line_Open_Fault : 43|1@0+ (1,0) [0|1] ""  HVAC
 SG_ eComp_HW_Fault : 42|1@0+ (1,0) [0|1] ""  HVAC

BO_ 940 VCU_3ACh: 8 VCU
 SG_ VCU_HV_ACT_IND : 23|2@0+ (1,0) [0|1] ""  CGW
 SG_ VCU_IGN4_STS : 9|1@0+ (1,0) [0|1] ""  EHVC,HVAC,LDC
 SG_ VCU_IGN3_STS : 8|1@0+ (1,0) [0|1] ""  LDC
 SG_ CruiseTargetKPH : 55|8@0+ (1,0) [0|255] "km/h"  CGW
 SG_ Charging_Sts_IND : 12|3@0+ (1,0) [0|5] ""  VESS,CGW
 SG_ VCU_Service_WRN_IND : 16|1@0+ (1,0) [0|1] ""  CGW
 SG_ ECO_Guide_Level_IND : 4|5@0+ (1,0) [0|31] "Step"  CGW
 SG_ ECO_Energy_Flow_IND : 7|2@0+ (1,0) [0|2] ""  CGW
 SG_ VCU_Cert_Status : 17|1@0+ (1,0) [0|1] ""  EBU,CGW
 SG_ CruiseTargetMPH : 63|8@0+ (1,0) [0|255] "mile/h"  CGW
 SG_ Charging_DR_STS : 21|1@0+ (1,0) [0|2] ""  CGW
 SG_ DrivingMode_VCU : 28|3@0+ (1,0) [0|3] ""  CGW
 SG_ DrivingModeDisplay : 25|2@0+ (1,0) [0|1] ""  CGW

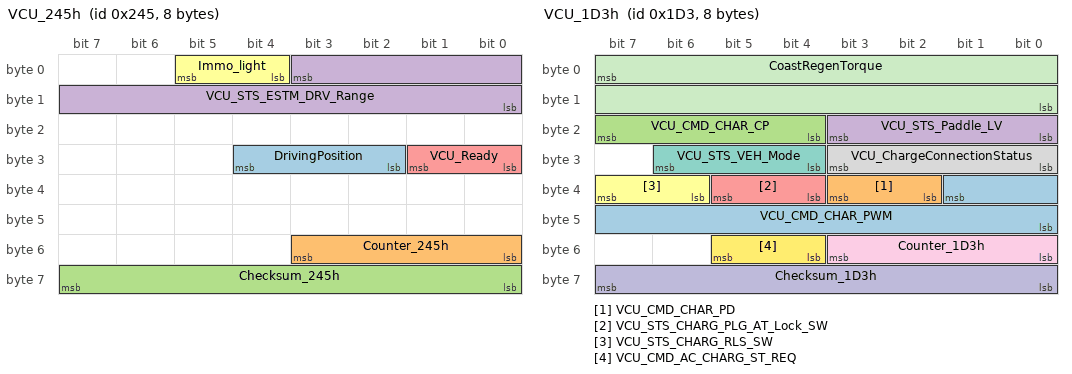
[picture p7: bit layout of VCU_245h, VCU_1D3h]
BO_ 581 VCU_245h: 8 VCU
 SG_ DrivingPosition : 28|3@0+ (1,0) [0|4] ""  VESS,BCM,CGW,SBWS,SKM
 SG_ Counter_245h : 51|4@0+ (1,0) [0|15] ""  SBWS,CGW
 SG_ Checksum_245h : 63|8@0+ (1,0) [0|255] ""  CGW,SBWS
 SG_ VCU_STS_ESTM_DRV_Range : 3|12@0+ (1,0) [0|4095] "km"  CGW
 SG_ VCU_Ready : 25|2@0+ (1,0) [0|2] ""  CGW,EHVC,EBU,ECALL,HVAC,LDC,MCU,OBC,SBWS
 SG_ Immo_light : 5|2@0+ (1,0) [0|2] ""  CGW

BO_ 467 VCU_1D3h: 8 VCU
 SG_ VCU_CMD_CHAR_PWM : 33|10@0+ (0.1,0) [0|100] "%"  OBC
 SG_ VCU_CMD_CHAR_PD : 35|2@0+ (1,0) [0|2] ""  OBC
 SG_ VCU_CMD_CHAR_CP : 23|4@0+ (1,0) [0|6] ""  OBC
 SG_ VCU_STS_Paddle_LV : 19|4@0+ (1,0) [0|3] ""  CGW
 SG_ VCU_STS_CHARG_PLG_AT_Lock_SW : 37|2@0+ (1,0) [0|2] ""  CGW
 SG_ VCU_STS_CHARG_RLS_SW : 39|2@0+ (1,0) [0|2] ""  CGW
 SG_ VCU_STS_VEH_Mode : 30|3@0+ (1,0) [0|4] ""  CGW
 SG_ VCU_ChargeConnectionStatus : 27|4@0+ (1,0) [0|2] ""  BMS,CGW
 SG_ Counter_1D3h : 51|4@0+ (1,0) [0|15] ""  BMS
 SG_ Checksum_1D3h : 63|8@0+ (1,0) [0|255] ""  BMS
 SG_ CoastRegenTorque : 7|16@0+ (1,-32760) [-32760|32760] ""  EBU
 SG_ VCU_CMD_AC_CHARG_ST_REQ : 53|2@0+ (1,0) [0|2] ""  OBC

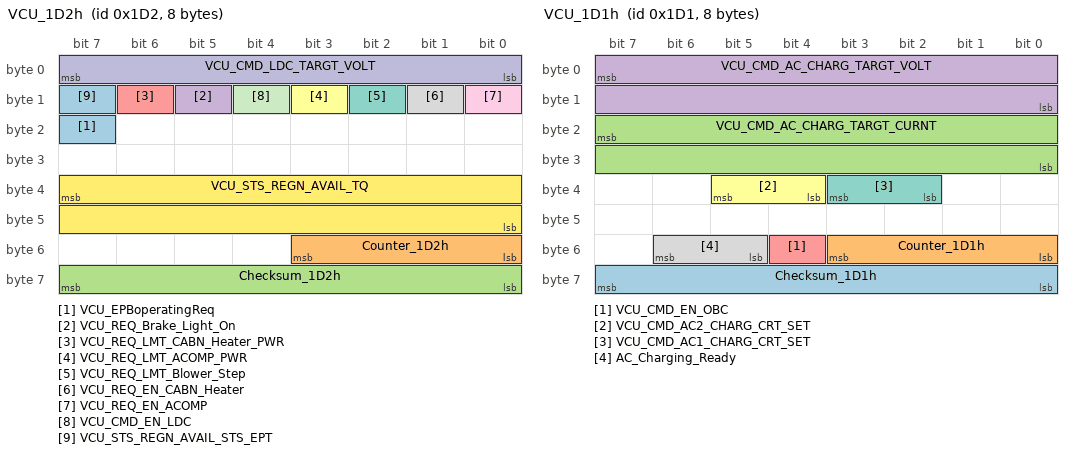
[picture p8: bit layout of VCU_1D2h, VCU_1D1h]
BO_ 466 VCU_1D2h: 8 VCU
 SG_ VCU_EPBoperatingReq : 23|1@0+ (1,0) [0|1] ""  EBU
 SG_ Counter_1D2h : 51|4@0+ (1,0) [0|15] ""  OBC
 SG_ Checksum_1D2h : 63|8@0+ (1,0) [0|255] ""  OBC
 SG_ VCU_REQ_Brake_Light_On : 13|1@0+ (1,0) [0|1] ""  BCM
 SG_ VCU_REQ_LMT_CABN_Heater_PWR : 14|1@0+ (1,0) [0|1] ""  EHVC
 SG_ VCU_REQ_LMT_ACOMP_PWR : 11|1@0+ (1,0) [0|1] ""  EHVC
 SG_ VCU_REQ_LMT_Blower_Step : 10|1@0+ (1,0) [0|1] ""  HVAC
 SG_ VCU_REQ_EN_CABN_Heater : 9|1@0+ (1,0) [0|1] ""  EHVC
 SG_ VCU_REQ_EN_ACOMP : 8|1@0+ (1,0) [0|1] ""  EHVC
 SG_ VCU_CMD_LDC_TARGT_VOLT : 7|8@0+ (0.1,0) [0|25.5] "Volts"  LDC
 SG_ VCU_CMD_EN_LDC : 12|1@0+ (1,0) [0|1] ""  LDC
 SG_ VCU_STS_REGN_AVAIL_TQ : 39|16@0+ (1,0) [0|65535] "Nm"  EBU
 SG_ VCU_STS_REGN_AVAIL_STS_EPT : 15|1@0+ (1,0) [0|1] ""  EBU

BO_ 465 VCU_1D1h: 8 VCU
 SG_ Checksum_1D1h : 63|8@0+ (1,0) [0|255] ""  OBC
 SG_ Counter_1D1h : 51|4@0+ (1,0) [0|15] ""  OBC
 SG_ VCU_CMD_AC_CHARG_TARGT_CURNT : 23|16@0+ (0.01,0) [0|30] "Amps"  OBC
 SG_ VCU_CMD_AC_CHARG_TARGT_VOLT : 7|16@0+ (0.1,0) [0|500] "Vdc"  OBC
 SG_ VCU_CMD_EN_OBC : 52|1@0+ (1,0) [0|1] ""  OBC
 SG_ VCU_CMD_AC2_CHARG_CRT_SET : 37|2@0+ (1,0) [0|2] ""  OBC
 SG_ VCU_CMD_AC1_CHARG_CRT_SET : 35|2@0+ (1,0) [0|2] ""  OBC
 SG_ AC_Charging_Ready : 54|2@0+ (1,0) [0|2] ""  OBC

BO_ 584 SKM_248h: 8 SKM
 SG_ RemoteStartSts : 1|2@0+ (1,0) [0|3] ""  VCU,BCM,HVAC,CGW,EHVC

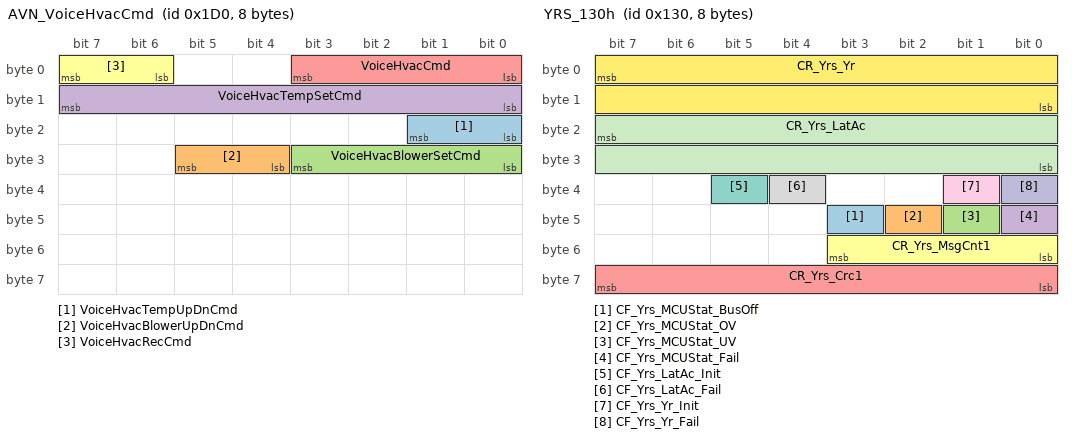
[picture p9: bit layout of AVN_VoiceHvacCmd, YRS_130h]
BO_ 464 AVN_VoiceHvacCmd: 8 CGW
 SG_ VoiceHvacTempUpDnCmd : 17|2@0+ (1,0) [0|15] ""  HVAC
 SG_ VoiceHvacBlowerUpDnCmd : 29|2@0+ (1,0) [0|15] ""  HVAC
 SG_ VoiceHvacBlowerSetCmd : 27|4@0+ (1,0) [0|15] ""  HVAC
 SG_ VoiceHvacTempSetCmd : 15|8@0+ (0.5,17.5) [17.5|32.5] "deg Cel."  HVAC
 SG_ VoiceHvacCmd : 3|4@0+ (1,0) [0|15] ""  HVAC
 SG_ VoiceHvacRecCmd : 7|2@0+ (1,0) [0|3] ""  HVAC

BO_ 458 CCU_RemoteCmdResp_HVAC: 8 HVAC
 SG_ RemoteHvacCntrlFailReason : 19|4@0+ (1,0) [0|15] ""  CGW
 SG_ RemoteHvacCntrlResp : 1|2@0+ (1,0) [0|3] ""  CGW
 SG_ HvacDrTempSetSts : 15|8@0+ (0.5,17.5) [17.5|32.5] "deg. C"  CGW
 SG_ HvacDefSts : 5|2@0+ (1,0) [0|3] ""  CGW

BO_ 450 CCU_RemoteCmd_HVAC: 8 CGW
 SG_ RemoteHvacDefoggerCmd : 7|2@0+ (1,0) [0|3] ""  HVAC
 SG_ RemoteHvacDefCmd : 5|2@0+ (1,0) [0|3] ""  HVAC
 SG_ RemoteHvacCntrlCmd : 1|2@0+ (1,0) [0|3] ""  HVAC
 SG_ RemoteHvacDrTempSet : 15|8@0+ (0.5,17.5) [17.5|32.5] "deg. C"  HVAC

BO_ 1981 SKM2_DGN_RESP: 8 SKM
 SG_ DGN_RESP_SKM2 : 7|64@0+ (1,0) [0|255] ""  CGW

BO_ 1973 SKM2_DGN_REQ: 8 CGW
 SG_ DGN_REQ_SKM2 : 7|64@0+ (1,0) [0|255] ""  SKM

BO_ 1597 TPMS_Debug: 8 BCM
 SG_ TPMS_Debug : 7|64@0+ (1,0) [0|0] ""  TESTER

BO_ 304 YRS_130h: 8 ACU
 SG_ CF_Yrs_MCUStat_BusOff : 43|1@0+ (1,0) [0|1] "" Vector__XXX
 SG_ CF_Yrs_MCUStat_OV : 42|1@0+ (1,0) [0|1] "" Vector__XXX
 SG_ CF_Yrs_MCUStat_UV : 41|1@0+ (1,0) [0|1] "" Vector__XXX
 SG_ CF_Yrs_MCUStat_Fail : 40|1@0+ (1,0) [0|1] "" Vector__XXX
 SG_ CR_Yrs_Crc1 : 63|8@0+ (1,0) [0|255] ""  VCU
 SG_ CR_Yrs_MsgCnt1 : 51|4@0+ (1,0) [0|15] "" Vector__XXX
 SG_ CF_Yrs_LatAc_Init : 37|1@0+ (1,0) [0|1] ""  VCU
 SG_ CF_Yrs_LatAc_Fail : 36|1@0+ (1,0) [0|1] ""  VCU
 SG_ CF_Yrs_Yr_Init : 33|1@0+ (1,0) [0|1] ""  VCU
 SG_ CF_Yrs_Yr_Fail : 32|1@0+ (1,0) [0|1] ""  VCU
 SG_ CR_Yrs_LatAc : 23|16@0+ (0.000127465,-4.17677312) [-4.17677312|4.17651819] "g"  VCU
 SG_ CR_Yrs_Yr : 7|16@0+ (0.005,-163.84) [-163.84|163.83] "deg/s"  VCU

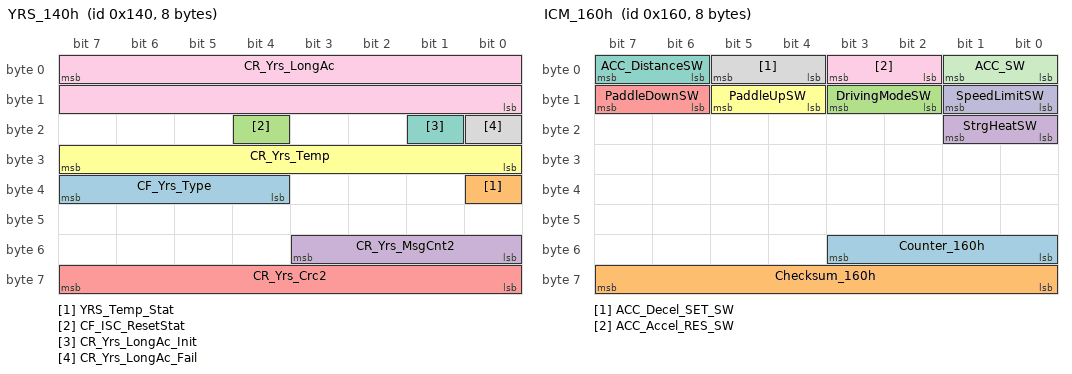
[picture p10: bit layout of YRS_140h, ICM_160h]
BO_ 320 YRS_140h: 8 ACU
 SG_ CF_Yrs_Type : 39|4@0+ (1,0) [0|15] "" Vector__XXX
 SG_ YRS_Temp_Stat : 32|1@0+ (1,0) [0|1] "" Vector__XXX
 SG_ CF_ISC_ResetStat : 20|1@0+ (1,0) [0|1] "" Vector__XXX
 SG_ CR_Yrs_MsgCnt2 : 51|4@0+ (1,0) [0|15] ""  VCU
 SG_ CR_Yrs_Crc2 : 63|8@0+ (1,0) [0|255] ""  VCU
 SG_ CR_Yrs_Temp : 31|8@0+ (1,-68) [-68|187] "deg C" Vector__XXX
 SG_ CR_Yrs_LongAc_Init : 17|1@0+ (1,0) [0|1] ""  VCU
 SG_ CR_Yrs_LongAc_Fail : 16|1@0+ (1,0) [0|1] ""  VCU
 SG_ CR_Yrs_LongAc : 7|16@0+ (0.000127465,-4.17677312) [-4.17677312|4.17651819] "g"  VCU

BO_ 1416 CGW_588h_VC: 8 CGW
 SG_ VC_4WD : 17|2@0+ (1,0) [0|3] ""  EBU
 SG_ VC_TPMS : 41|2@0+ (1,0) [0|3] "" Vector__XXX
 SG_ VC_STPM : 23|2@0+ (1,0) [0|3] "" Vector__XXX
 SG_ VC_SKM : 33|2@0+ (1,0) [0|3] "" Vector__XXX
 SG_ VC_RHD : 39|2@0+ (1,0) [0|3] "" Vector__XXX
 SG_ VC_Audio : 27|2@0+ (1,0) [0|3] "" Vector__XXX
 SG_ VC_AT : 13|2@0+ (1,0) [0|3] ""  BCM,EBU,SKM
 SG_ VC_EPS : 19|2@0+ (1,0) [0|3] "" Vector__XXX
 SG_ VC_BS : 15|2@0+ (1,0) [0|3] ""  SKM
 SG_ Brake_Variant : 50|3@0+ (1,0) [0|7] ""  BCM
 SG_ VC_Validity : 1|2@0+ (1,0) [0|3] ""  EBU
 SG_ VC_Project : 7|6@0+ (1,0) [0|63] "" Vector__XXX
 SG_ VC_DOM : 11|4@0+ (1,0) [0|15] ""  SKM
 SG_ VC_CCU : 37|2@0+ (1,0) [0|3] ""  SKM
 SG_ VC_PTG : 35|2@0+ (1,0) [0|3] ""  SKM
 SG_ VC_BSD : 25|2@0+ (1,0) [0|3] "" Vector__XXX
 SG_ VC_WPC : 43|2@0+ (1,0) [0|3] ""  SKM

BO_ 1352 CGW_PCAN_STS: 8 CGW
 SG_ BusOffCnt_CGW_PCAN : 55|8@0+ (1,0) [0|255] "" Vector__XXX
 SG_ CMXVersion_CGW_PCAN : 7|16@0+ (1,0) [0|65535] "" Vector__XXX
 SG_ DTCInfo_CGW_PCAN : 17|2@0+ (1,0) [0|3] "" Vector__XXX
 SG_ MsgAliveCnt_CGW_PCAN : 63|8@0+ (1,0) [0|255] "" Vector__XXX
 SG_ RxErrCnt_CGW_PCAN : 39|8@0+ (1,0) [0|255] "" Vector__XXX
 SG_ SupplyVolt_CGW_PCAN : 31|8@0+ (0.1,0) [0|25.5] "V" Vector__XXX
 SG_ TxErrCnt_CGW_PCAN : 47|8@0+ (1,0) [0|255] "" Vector__XXX

BO_ 1902 EHVC_DGN_RESP: 8 EHVC
 SG_ DGN_RESP_EHVC : 7|64@0+ (1,0) [0|0] ""  CGW

BO_ 1901 EGP_DGN_RESP: 8 EGP
 SG_ DGN_RESP_EGP : 7|64@0+ (1,0) [0|0] ""  CGW

BO_ 1900 OBC_DGN_RESP: 8 OBC
 SG_ DGN_RESP_OBC : 7|64@0+ (1,0) [0|0] ""  CGW

BO_ 1899 LDC_DGN_RESP: 8 LDC
 SG_ DGN_RESP_LDC : 7|64@0+ (1,0) [0|0] ""  CGW

BO_ 1898 MCU_DGN_RESP: 8 MCU
 SG_ DGN_RESP_MCU : 7|64@0+ (1,0) [0|0] ""  CGW

BO_ 352 ICM_160h: 8 CGW
 SG_ Counter_160h : 51|4@0+ (1,0) [0|15] ""  VCU
 SG_ Checksum_160h : 63|8@0+ (1,0) [0|255] ""  VCU
 SG_ DrivingModeSW : 11|2@0+ (1,0) [0|3] "" Vector__XXX
 SG_ StrgHeatSW : 17|2@0+ (1,0) [0|3] ""  BCM
 SG_ PaddleDownSW : 15|2@0+ (1,0) [0|3] ""  VCU
 SG_ PaddleUpSW : 13|2@0+ (1,0) [0|3] ""  VCU
 SG_ ACC_DistanceSW : 7|2@0+ (1,0) [0|3] ""  VCU
 SG_ ACC_Decel_SET_SW : 5|2@0+ (1,0) [0|3] ""  VCU
 SG_ ACC_Accel_RES_SW : 3|2@0+ (1,0) [0|3] ""  VCU
 SG_ SpeedLimitSW : 9|2@0+ (1,0) [0|3] ""  VCU
 SG_ ACC_SW : 1|2@0+ (1,0) [0|3] ""  VCU

BO_ 1381 EGP_PCAN_STS: 8 EGP
 SG_ TxErrCnt_EGP_PCAN : 47|8@0+ (1,0) [0|255] "" Vector__XXX
 SG_ SupplyVolt_EGP_PCAN : 31|8@0+ (0.1,0) [0|25.5] "V" Vector__XXX
 SG_ RxErrCnt_EGP_PCAN : 39|8@0+ (1,0) [0|255] "" Vector__XXX
 SG_ MsgAliveCnt_EGP_PCAN : 63|8@0+ (1,0) [0|255] "" Vector__XXX
 SG_ DTCInfo_EGP_PCAN : 17|2@0+ (1,0) [0|3] "" Vector__XXX
 SG_ CMXVersion_EGP_PCAN : 7|16@0+ (1,0) [0|65535] "" Vector__XXX
 SG_ BusOffCnt_EGP_PCAN : 55|8@0+ (1,0) [0|255] "" Vector__XXX

BO_ 1382 EHVC_PCAN_STS: 8 EHVC
 SG_ TxErrCnt_EHVC_PCAN : 47|8@0+ (1,0) [0|255] "" Vector__XXX
 SG_ SupplyVolt_EHVC_PCAN : 31|8@0+ (0.1,0) [0|25.5] "V" Vector__XXX
 SG_ RxErrCnt_EHVC_PCAN : 39|8@0+ (1,0) [0|255] "" Vector__XXX
 SG_ MsgAliveCnt_EHVC_PCAN : 63|8@0+ (1,0) [0|255] "" Vector__XXX
 SG_ DTCInfo_EHVC_PCAN : 17|2@0+ (1,0) [0|3] "" Vector__XXX
 SG_ CMXVersion_EHVC_PCAN : 7|16@0+ (1,0) [0|65535] "" Vector__XXX
 SG_ BusOffCnt_EHVC_PCAN : 55|8@0+ (1,0) [0|255] "" Vector__XXX

BO_ 1587 VCU_CAL_633h: 8 VCU
 SG_ VCU_Calibration_633h_Signal : 7|64@0+ (1,0) [0|0] ""  CGW

BO_ 1588 VCU_CAL_634h: 8 VCU
 SG_ VCU_Calibration_634h_Signal : 7|64@0+ (1,0) [0|0] ""  CGW

BO_ 1586 VCU_CAL_632h: 8 VCU
 SG_ VCU_Calibration_632h_Signal : 7|64@0+ (1,0) [0|0] ""  CGW

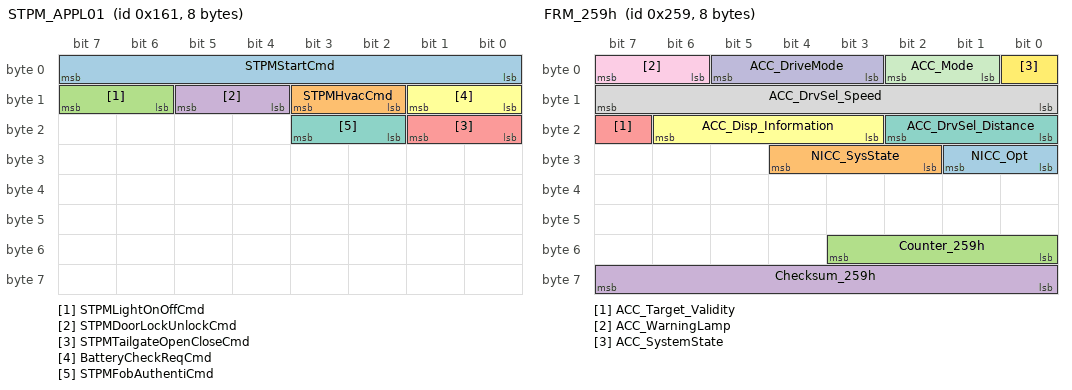
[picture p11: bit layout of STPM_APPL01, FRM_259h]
BO_ 353 STPM_APPL01: 8 CGW
 SG_ STPMStartCmd : 7|8@0+ (1,0) [0|255] "" Vector__XXX
 SG_ STPMHvacCmd : 11|2@0+ (1,0) [0|3] ""  HVAC
 SG_ STPMLightOnOffCmd : 15|2@0+ (1,0) [0|1] "" Vector__XXX
 SG_ STPMDoorLockUnlockCmd : 13|2@0+ (1,0) [0|1] "" Vector__XXX
 SG_ STPMTailgateOpenCloseCmd : 17|2@0+ (1,0) [0|1] "" Vector__XXX
 SG_ BatteryCheckReqCmd : 9|2@0+ (1,0) [0|1] ""  VCU
 SG_ STPMFobAuthentiCmd : 19|2@0+ (1,0) [0|0] "" Vector__XXX

BO_ 1897 BMS_DGN_RESP: 8 BMS
 SG_ DGN_RESP_BMS : 7|64@0+ (1,0) [0|0] ""  CGW

BO_ 1865 VESS_DGN_RESP: 8 VESS
 SG_ DGN_RESP_VESS : 7|64@0+ (1,0) [0|0] ""  CGW

BO_ 601 FRM_259h: 8 CGW
 SG_ NICC_Opt : 25|2@0+ (1,0) [0|3] "" Vector__XXX
 SG_ NICC_SysState : 28|3@0+ (1,0) [0|7] "" Vector__XXX
 SG_ Counter_259h : 51|4@0+ (1,0) [0|15] ""  VCU
 SG_ Checksum_259h : 63|8@0+ (1,0) [0|255] ""  VCU
 SG_ ACC_Target_Validity : 23|1@0+ (1,0) [0|1] "" Vector__XXX
 SG_ ACC_Disp_Information : 22|4@0+ (1,0) [0|7] "" Vector__XXX
 SG_ ACC_DrvSel_Distance : 18|3@0+ (1,0) [0|7] "" Vector__XXX
 SG_ ACC_DrvSel_Speed : 15|8@0+ (1,0) [0|255] "kph/mph" Vector__XXX
 SG_ ACC_WarningLamp : 7|2@0+ (1,0) [0|3] "" Vector__XXX
 SG_ ACC_DriveMode : 5|3@0+ (1,0) [0|7] "" Vector__XXX
 SG_ ACC_Mode : 2|2@0+ (1,0) [0|3] ""  VCU
 SG_ ACC_SystemState : 0|1@0+ (1,0) [0|1] ""  VCU

BO_ 277 SKM_115h: 7 SKM
 SG_ SKM_Immo : 7|56@0+ (1,0) [0|0] ""  VCU

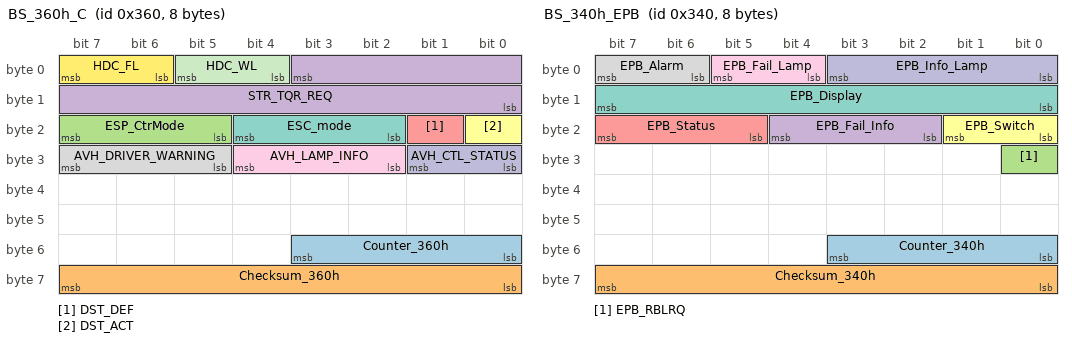
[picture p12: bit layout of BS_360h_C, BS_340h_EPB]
BO_ 864 BS_360h_C: 8 CGW
 SG_ Counter_360h : 51|4@0+ (1,0) [0|15] "" Vector__XXX
 SG_ Checksum_360h : 63|8@0+ (1,0) [0|255] "" Vector__XXX
 SG_ ESP_CtrMode : 23|3@0+ (1,0) [0|7] "" Vector__XXX
 SG_ STR_TQR_REQ : 3|12@0+ (0.01,-20.48) [-20.48|20.47] "Nm" Vector__XXX
 SG_ DST_DEF : 17|1@0+ (1,0) [0|1] "" Vector__XXX
 SG_ DST_ACT : 16|1@0+ (1,0) [0|1] "" Vector__XXX
 SG_ ESC_mode : 20|3@0+ (1,0) [0|7] "" Vector__XXX
 SG_ AVH_DRIVER_WARNING : 31|3@0+ (1,0) [0|7] "" Vector__XXX
 SG_ AVH_LAMP_INFO : 28|3@0+ (1,0) [0|7] "" Vector__XXX
 SG_ AVH_CTL_STATUS : 25|2@0+ (1,0) [0|3] "" Vector__XXX
 SG_ HDC_WL : 5|2@0+ (1,0) [0|3] "" Vector__XXX
 SG_ HDC_FL : 7|2@0+ (1,0) [0|3] "" Vector__XXX

BO_ 832 BS_340h_EPB: 8 CGW
 SG_ Counter_340h : 51|4@0+ (1,0) [0|15] ""  VCU
 SG_ Checksum_340h : 63|8@0+ (1,0) [0|255] ""  VCU
 SG_ EPB_RBLRQ : 24|1@0+ (1,0) [0|1] ""  VCU
 SG_ EPB_Fail_Info : 20|3@0+ (1,0) [0|7] "" Vector__XXX
 SG_ EPB_Status : 23|3@0+ (1,0) [0|7] ""  VCU
 SG_ EPB_Switch : 17|2@0+ (1,0) [0|3] "" Vector__XXX
 SG_ EPB_Display : 15|8@0+ (1,0) [0|255] "" Vector__XXX
 SG_ EPB_Alarm : 7|2@0+ (1,0) [0|3] "" Vector__XXX
 SG_ EPB_Fail_Lamp : 5|2@0+ (1,0) [0|3] "" Vector__XXX
 SG_ EPB_Info_Lamp : 3|4@0+ (1,0) [0|15] "" Vector__XXX

BO_ 563 BS_233h_P: 8 EBU
 SG_ WHL_PULSE_RL : 23|8@0+ (0.5,0) [0|127.5] "pulse"  ECALL,BCM
 SG_ WHL_PULSE_RR : 31|8@0+ (0.5,0) [0|127.5] "pulse"  ECALL,BCM
 SG_ WHL_PULSE_FR : 15|8@0+ (0.5,0) [0|127.5] "pulse"  ECALL,BCM
 SG_ WHL_PULSE_FL : 7|8@0+ (0.5,0) [0|127.5] "pulse"  ECALL,BCM

BO_ 1378 MCU_PCAN_STS: 8 MCU
 SG_ TxErrCnt_MCU_PCAN : 47|8@0+ (1,0) [0|255] "" Vector__XXX
 SG_ SupplyVolt_MCU_PCAN : 31|8@0+ (0.1,0) [0|25.5] "V" Vector__XXX
 SG_ RxErrCnt_MCU_PCAN : 39|8@0+ (1,0) [0|255] "" Vector__XXX
 SG_ MsgAliveCnt_MCU_PCAN : 63|8@0+ (1,0) [0|255] "" Vector__XXX
 SG_ DTCInfo_MCU_PCAN : 17|2@0+ (1,0) [0|3] "" Vector__XXX
 SG_ CMXVersion_MCU_PCAN : 7|16@0+ (1,0) [0|65535] "" Vector__XXX
 SG_ BusOffCnt_MCU_PCAN : 55|8@0+ (1,0) [0|255] "" Vector__XXX

BO_ 1377 BMS_PCAN_STS: 8 BMS
 SG_ TxErrCnt_BMS_PCAN : 47|8@0+ (1,0) [0|255] "" Vector__XXX
 SG_ SupplyVolt_BMS_PCAN : 31|8@0+ (0.1,0) [0|25.5] "V" Vector__XXX
 SG_ RxErrCnt_BMS_PCAN : 39|8@0+ (1,0) [0|255] "" Vector__XXX
 SG_ MsgAliveCnt_BMS_PCAN : 63|8@0+ (1,0) [0|255] "" Vector__XXX
 SG_ DTCInfo_BMS_PCAN : 17|2@0+ (1,0) [0|3] "" Vector__XXX
 SG_ CMXVersion_BMS_PCAN : 7|16@0+ (1,0) [0|65535] "" Vector__XXX
 SG_ BusOffCnt_BMS_PCAN : 55|8@0+ (1,0) [0|255] "" Vector__XXX

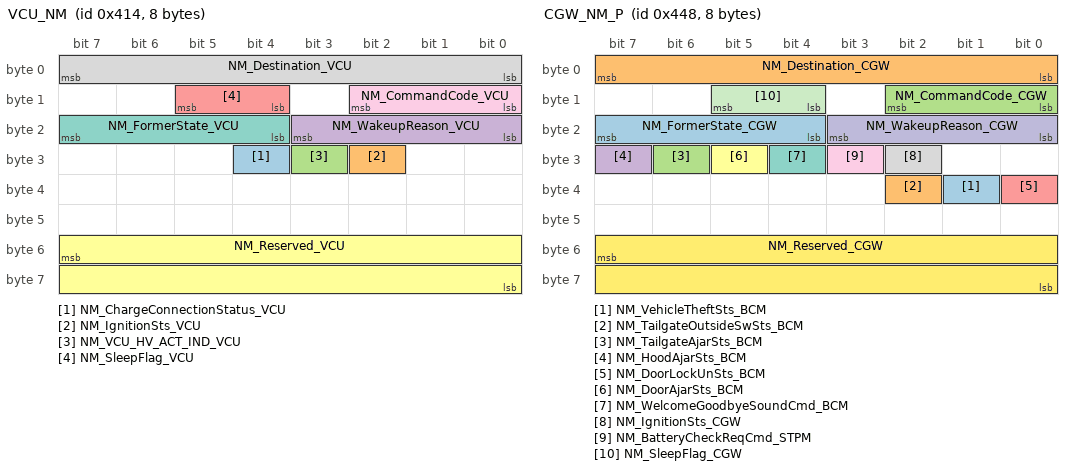
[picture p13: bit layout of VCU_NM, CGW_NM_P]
BO_ 1044 VCU_NM: 8 VCU
 SG_ NM_ChargeConnectionStatus_VCU : 28|1@0+ (1,0) [0|1] "" Vector__XXX
 SG_ NM_IgnitionSts_VCU : 26|1@0+ (1,0) [0|1] "" Vector__XXX
 SG_ NM_VCU_HV_ACT_IND_VCU : 27|1@0+ (1,0) [0|1] "" Vector__XXX
 SG_ NM_WakeupReason_VCU : 19|4@0+ (1,0) [0|0] "" Vector__XXX
 SG_ NM_SleepFlag_VCU : 13|2@0+ (1,0) [0|0] ""  CGW
 SG_ NM_Reserved_VCU : 55|16@0+ (1,0) [0|0] "" Vector__XXX
 SG_ NM_FormerState_VCU : 23|4@0+ (1,0) [0|0] "" Vector__XXX
 SG_ NM_Destination_VCU : 7|8@0+ (1,0) [0|0] ""  CGW
 SG_ NM_CommandCode_VCU : 10|3@0+ (1,0) [0|0] ""  CGW

BO_ 1096 CGW_NM_P: 8 CGW
 SG_ NM_VehicleTheftSts_BCM : 33|1@0+ (1,0) [0|1] "" Vector__XXX
 SG_ NM_TailgateOutsideSwSts_BCM : 34|1@0+ (1,0) [0|1] "" Vector__XXX
 SG_ NM_TailgateAjarSts_BCM : 30|1@0+ (1,0) [0|1] "" Vector__XXX
 SG_ NM_HoodAjarSts_BCM : 31|1@0+ (1,0) [0|1] "" Vector__XXX
 SG_ NM_DoorLockUnSts_BCM : 32|1@0+ (1,0) [0|1] "" Vector__XXX
 SG_ NM_DoorAjarSts_BCM : 29|1@0+ (1,0) [0|1] "" Vector__XXX
 SG_ NM_WelcomeGoodbyeSoundCmd_BCM : 28|1@0+ (1,0) [0|1] "" Vector__XXX
 SG_ NM_IgnitionSts_CGW : 26|1@0+ (1,0) [0|1] "" Vector__XXX
 SG_ NM_BatteryCheckReqCmd_STPM : 27|1@0+ (1,0) [0|1] "" Vector__XXX
 SG_ NM_WakeupReason_CGW : 19|4@0+ (1,0) [0|0] "" Vector__XXX
 SG_ NM_SleepFlag_CGW : 13|2@0+ (1,0) [0|0] ""  VCU
 SG_ NM_Reserved_CGW : 55|16@0+ (1,0) [0|0] "" Vector__XXX
 SG_ NM_FormerState_CGW : 23|4@0+ (1,0) [0|0] "" Vector__XXX
 SG_ NM_Destination_CGW : 7|8@0+ (1,0) [0|0] ""  VCU
 SG_ NM_CommandCode_CGW : 10|3@0+ (1,0) [0|0] ""  VCU

BO_ 1976 ECALL_DGN_RESP: 8 ECALL
 SG_ DGN_RESP_ECALL : 7|64@0+ (1,0) [0|0] ""  CGW

BO_ 1968 ECALL_DGN_REQ: 8 CGW
 SG_ DGN_REQ_ECALL : 7|64@0+ (1,0) [0|0] ""  ECALL

BO_ 1803 HVAC_DGN_RESP: 8 HVAC
 SG_ DGN_RESP_HVAC : 7|64@0+ (1,0) [0|0] ""  CGW

BO_ 481 MCU_1E1h: 8 MCU
 SG_ MotorTorqueEstimated_RS1 : 7|16@0+ (1,-32760) [-32760|32760] "Nm"  EBU
 SG_ MotorTorqueEstimated : 23|16@0+ (0.0625,-2048) [-2045|2045] "Nm" Vector__XXX
 SG_ MotorSpeed : 39|16@0+ (1,-32767) [-32760|32760] "RPM" Vector__XXX
 SG_ Counter_1E1h : 51|4@0+ (1,0) [0|15] "" Vector__XXX
 SG_ Checksum_1E1h : 63|8@0+ (1,0) [0|255] "" Vector__XXX

BO_ 937 OBC_3A9h: 8 OBC
 SG_ OBC_DC_Output_I : 55|16@0+ (0.01,0) [0|30] ""  VCU
 SG_ OBC_DC_Output_V : 39|16@0+ (0.1,0) [0|500] ""  VCU
 SG_ OBC_AC_I_rms : 23|16@0+ (0.01,0) [0|40] ""  VCU
 SG_ OBC_AC_V_rms : 7|16@0+ (0.1,0) [0|300] ""  VCU

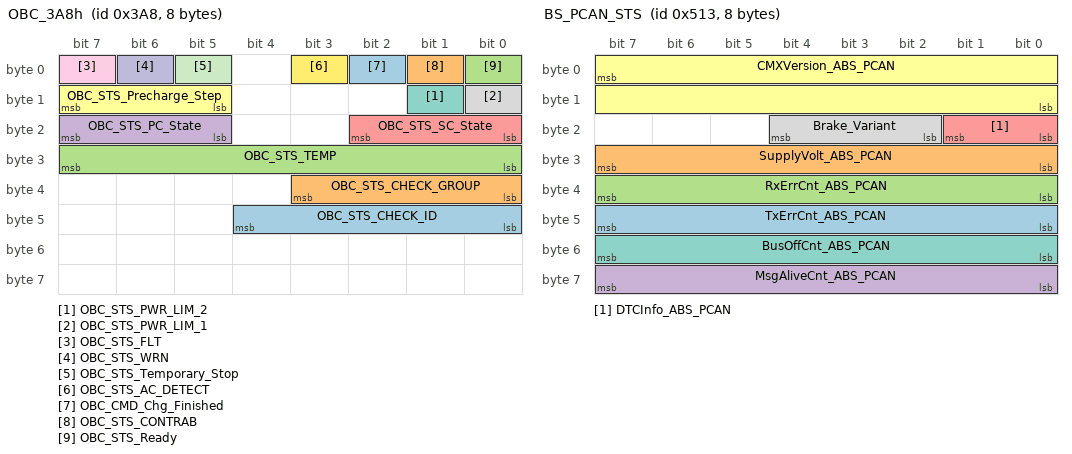
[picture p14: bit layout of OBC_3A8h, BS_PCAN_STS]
BO_ 936 OBC_3A8h: 8 OBC
 SG_ OBC_STS_CHECK_ID : 44|5@0+ (1,0) [0|31] "" Vector__XXX
 SG_ OBC_STS_CHECK_GROUP : 35|4@0+ (1,0) [0|15] ""  VCU
 SG_ OBC_STS_TEMP : 31|8@0+ (1,-40) [-40|200] "deg Cel"  VCU
 SG_ OBC_STS_PC_State : 23|3@0+ (1,0) [0|7] ""  VCU
 SG_ OBC_STS_SC_State : 18|3@0+ (1,0) [0|7] ""  VCU
 SG_ OBC_STS_Precharge_Step : 15|3@0+ (1,0) [0|7] "" Vector__XXX
 SG_ OBC_STS_PWR_LIM_2 : 9|1@0+ (1,0) [0|1] "" Vector__XXX
 SG_ OBC_STS_PWR_LIM_1 : 8|1@0+ (1,0) [0|1] "" Vector__XXX
 SG_ OBC_STS_FLT : 7|1@0+ (1,0) [0|1] "" Vector__XXX
 SG_ OBC_STS_WRN : 6|1@0+ (1,0) [0|1] "" Vector__XXX
 SG_ OBC_STS_Temporary_Stop : 5|1@0+ (1,0) [0|1] ""  VCU
 SG_ OBC_STS_AC_DETECT : 3|1@0+ (1,0) [0|1] ""  VCU
 SG_ OBC_CMD_Chg_Finished : 2|1@0+ (1,0) [0|1] ""  VCU
 SG_ OBC_STS_CONTRAB : 1|1@0+ (1,0) [0|1] ""  VCU
 SG_ OBC_STS_Ready : 0|1@0+ (1,0) [0|1] ""  VCU

BO_ 336 ICM_150h: 8 CGW
 SG_ VessWelcomeOnOffSetCmd : 51|2@0+ (1,0) [0|2] ""  VESS
 SG_ LongTermParkSetCmd : 25|2@0+ (1,0) [0|2] "" Vector__XXX
 SG_ SafetyUnlockSetCmd : 47|2@0+ (1,0) [0|2] "" Vector__XXX
 SG_ TSRSetCmd : 15|2@0+ (1,0) [0|3] "" Vector__XXX
 SG_ SDWSetCmd : 63|2@0+ (1,0) [0|3] "" Vector__XXX
 SG_ DDWSetCmd : 61|2@0+ (1,0) [0|3] "" Vector__XXX
 SG_ ACC_DriveMode_SetCmd : 59|2@0+ (1,0) [0|3] "" Vector__XXX
 SG_ ACCwSteerSetCmd : 57|2@0+ (1,0) [0|3] "" Vector__XXX
 SG_ LKASSetCmd : 2|2@0+ (1,0) [0|3] "" Vector__XXX
 SG_ ComeHomeLampSetCmd : 13|3@0+ (1,0) [0|4] "" Vector__XXX
 SG_ PTGSmartSetCmd : 45|2@0+ (1,0) [0|2] "" Vector__XXX
 SG_ DoorUnlockSetCmd : 20|3@0+ (1,0) [0|4] "" Vector__XXX
 SG_ DoorLockSetCmd : 23|3@0+ (1,0) [0|4] "" Vector__XXX
 SG_ FactoryModeSetCmd : 0|1@0+ (1,0) [0|1] ""  VESS
 SG_ LeaveHomeLampSetCmd : 10|3@0+ (1,0) [0|4] "" Vector__XXX
 SG_ DoorLockSpeedSetCmd : 28|3@0+ (1,0) [0|5] "" Vector__XXX
 SG_ AutoLockSetCmd : 33|2@0+ (1,0) [0|2] "" Vector__XXX
 SG_ AutoApproachSetCmd : 35|2@0+ (1,0) [0|2] "" Vector__XXX
 SG_ ApproachLampSetCmd : 39|2@0+ (1,0) [0|2] "" Vector__XXX
 SG_ AlarmBuzzSetCmd : 17|2@0+ (1,0) [0|2] "" Vector__XXX
 SG_ WPCSetCmd : 41|2@0+ (1,0) [0|3] "" Vector__XXX
 SG_ PTGModeSetCmd : 43|2@0+ (1,0) [0|3] "" Vector__XXX
 SG_ FCWSetCmd : 5|3@0+ (1,0) [0|7] "" Vector__XXX
 SG_ AEBSetCmd : 7|2@0+ (1,0) [0|3] "" Vector__XXX
 SG_ VessSoundSetCmd : 53|2@0+ (1,0) [0|2] ""  VESS
 SG_ FVSASetCmd : 49|2@0+ (1,0) [0|3] "" Vector__XXX

BO_ 1795 HVAC_DGN_REQ: 8 CGW
 SG_ DGN_REQ_HVAC : 7|64@0+ (1,0) [0|0] ""  HVAC

BO_ 1356 SKM_PCAN_STS: 8 SKM
 SG_ TxErrCnt_SKM_PCAN : 47|8@0+ (1,0) [0|255] "" Vector__XXX
 SG_ SupplyVolt_SKM_PCAN : 31|8@0+ (0.1,0) [0|25.5] "V" Vector__XXX
 SG_ RxErrCnt_SKM_PCAN : 39|8@0+ (1,0) [0|255] "" Vector__XXX
 SG_ MsgAliveCnt_SKM_PCAN : 63|8@0+ (1,0) [0|255] "" Vector__XXX
 SG_ DTCInfo_SKM_PCAN : 17|2@0+ (1,0) [0|3] "" Vector__XXX
 SG_ CMXVersion_SKM_PCAN : 7|16@0+ (1,0) [0|65535] "" Vector__XXX
 SG_ BusOffCnt_SKM_PCAN : 55|8@0+ (1,0) [0|255] "" Vector__XXX

BO_ 1303 HVAC_PCAN_STS: 8 HVAC
 SG_ TxErrCnt_HVAC_PCAN : 47|8@0+ (1,0) [0|255] "" Vector__XXX
 SG_ SupplyVolt_HVAC_PCAN : 31|8@0+ (0.1,0) [0|25.5] "V" Vector__XXX
 SG_ RxErrCnt_HVAC_PCAN : 39|8@0+ (1,0) [0|255] "" Vector__XXX
 SG_ MsgAliveCnt_HVAC_PCAN : 63|8@0+ (1,0) [0|255] "" Vector__XXX
 SG_ DTCInfo_HVAC_PCAN : 17|2@0+ (1,0) [0|3] ""  CGW
 SG_ CMXVersion_HVAC_PCAN : 7|16@0+ (1,0) [0|65535] "" Vector__XXX
 SG_ BusOffCnt_HVAC_PCAN : 55|8@0+ (1,0) [0|255] "" Vector__XXX

BO_ 1300 VCU_PCAN_STS: 8 VCU
 SG_ TxErrCnt_VCU_PCAN : 47|8@0+ (1,0) [0|255] ""  TESTER
 SG_ SupplyVolt_VCU_PCAN : 31|8@0+ (0.1,0) [0|25.5] "V"  TESTER
 SG_ RxErrCnt_VCU_PCAN : 39|8@0+ (1,0) [0|255] ""  TESTER
 SG_ MsgAliveCnt_VCU_PCAN : 63|8@0+ (1,0) [0|255] ""  TESTER
 SG_ DTCInfo_VCU_PCAN : 17|2@0+ (1,0) [0|3] ""  CGW,TESTER
 SG_ CMXVersion_VCU_PCAN : 7|16@0+ (1,0) [0|65535] ""  TESTER
 SG_ BusOffCnt_VCU_PCAN : 55|8@0+ (1,0) [0|255] ""  TESTER

BO_ 1299 BS_PCAN_STS: 8 EBU
 SG_ TxErrCnt_ABS_PCAN : 47|8@0+ (1,0) [0|255] "" Vector__XXX
 SG_ SupplyVolt_ABS_PCAN : 31|8@0+ (0.1,0) [0|25.5] "V" Vector__XXX
 SG_ RxErrCnt_ABS_PCAN : 39|8@0+ (1,0) [0|255] "" Vector__XXX
 SG_ MsgAliveCnt_ABS_PCAN : 63|8@0+ (1,0) [0|255] "" Vector__XXX
 SG_ DTCInfo_ABS_PCAN : 17|2@0+ (1,0) [0|3] ""  CGW
 SG_ CMXVersion_ABS_PCAN : 7|16@0+ (1,0) [0|65535] "" Vector__XXX
 SG_ BusOffCnt_ABS_PCAN : 55|8@0+ (1,0) [0|255] "" Vector__XXX
 SG_ Brake_Variant : 20|3@0+ (1,0) [0|7] ""  CGW

BO_ 1345 BCM_PCAN_STS: 8 BCM
 SG_ SupplyVolt_BCM_PCAN : 31|8@0+ (0.1,0) [0|25.5] "V" Vector__XXX
 SG_ RxErrCnt_BCM_PCAN : 39|8@0+ (1,0) [0|255] "" Vector__XXX
 SG_ MsgAliveCnt_BCM_PCAN : 63|8@0+ (1,0) [0|255] "" Vector__XXX
 SG_ DTCInfo_BCM_PCAN : 17|2@0+ (1,0) [0|3] "" Vector__XXX
 SG_ CMXVersion_BCM_PCAN : 7|16@0+ (1,0) [0|65535] "" Vector__XXX
 SG_ BusOffCnt_BCM_PCAN : 55|8@0+ (1,0) [0|255] "" Vector__XXX
 SG_ TxErrCnt_BCM_PCAN : 47|8@0+ (1,0) [0|255] "" Vector__XXX

BO_ 821 ACU_335h: 8 ACU
 SG_ PAB_On : 5|2@0+ (1,0) [0|3] ""  HVAC
 SG_ PAB_Off : 3|2@0+ (1,0) [0|3] ""  HVAC
 SG_ Airbag_WL : 1|2@0+ (1,0) [0|3] ""  ECALL,CGW

BO_ 309 ACU_135h: 8 ACU
 SG_ Counter_135h : 51|4@0+ (1,0) [0|15] ""  BMS,MCU
 SG_ Checksum_135h : 63|8@0+ (1,0) [0|255] ""  BMS,MCU
 SG_ ACU_Crashout : 0|1@0+ (1,0) [0|1] ""  CGW,BMS,MCU,OBC,VCU,ECALL,BCM,SKM

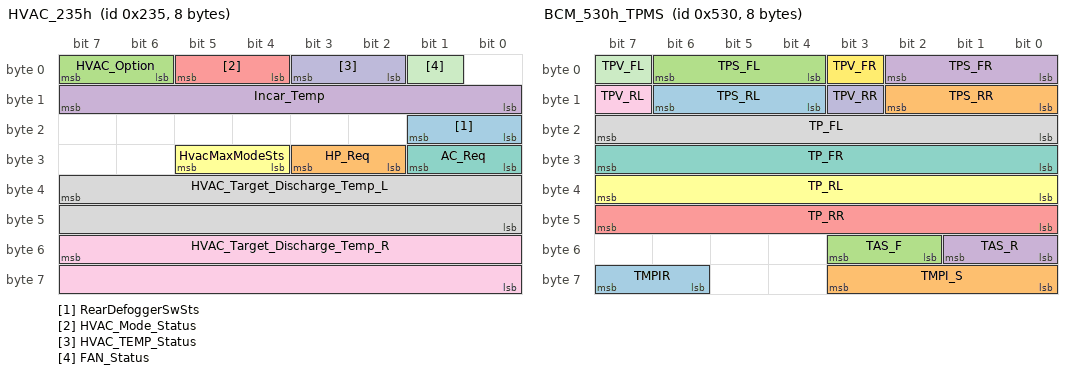
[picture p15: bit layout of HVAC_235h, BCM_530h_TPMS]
BO_ 565 HVAC_235h: 8 HVAC
 SG_ RearDefoggerSwSts : 17|2@0+ (1,0) [0|3] ""  VCU,BCM
 SG_ HP_Req : 27|2@0+ (1,0) [0|3] ""  EHVC
 SG_ HVAC_Option : 7|2@0+ (1,0) [0|3] "" Vector__XXX
 SG_ Incar_Temp : 15|8@0+ (0.5,-30) [-30|55] "deg Cel."  VCU,EHVC
 SG_ HVAC_Mode_Status : 5|2@0+ (1,0) [0|3] ""  VCU
 SG_ HvacMaxModeSts : 29|2@0+ (1,0) [0|3] ""  CGW
 SG_ AC_Req : 25|2@0+ (1,0) [0|3] ""  EHVC
 SG_ HVAC_Target_Discharge_Temp_L : 39|16@0+ (0.1,-40) [0|100] "deg Cel."  EHVC
 SG_ HVAC_Target_Discharge_Temp_R : 55|16@0+ (0.1,-40) [0|100] "deg Cel."  EHVC
 SG_ HVAC_TEMP_Status : 3|2@0+ (1,0) [0|3] ""  VCU
 SG_ FAN_Status : 1|1@0+ (1,0) [0|1] ""  VCU

BO_ 2012 ACU_PMODE_RESP: 8 ACU
 SG_ DGN_ACU_Pmode_Response : 7|64@0+ (1,0) [0|0] ""  CGW

BO_ 2004 ACU_PMODE_REQ: 8 CGW
 SG_ DGN_ACU_Pmode_Reqeuest : 7|64@0+ (1,0) [0|0] ""  ACU

BO_ 2041 ACU_SCRAP_RESP: 8 ACU
 SG_ DGN_ACU_Scrap_Response : 7|64@0+ (1,0) [0|0] ""  CGW

BO_ 2033 ACU_SCRAP_REQ: 8 CGW
 SG_ DGN_ACU_Scrap_Request : 7|64@0+ (1,0) [0|0] ""  ACU

BO_ 2011 ACU_DGN_RESP: 8 ACU
 SG_ DGN_RESP_ACU : 7|64@0+ (1,0) [0|0] ""  CGW

BO_ 2003 ACU_DGN_REQ: 8 CGW
 SG_ DGN_REQ_ACU : 7|64@0+ (1,0) [0|0] ""  ACU

BO_ 1289 ACU_PCAN_STS: 8 ACU
 SG_ TxErrCnt_ACU_PCAN : 47|8@0+ (1,0) [0|255] "" Vector__XXX
 SG_ SupplyVolt_ACU_PCAN : 31|8@0+ (0.1,0) [0|25.5] "V" Vector__XXX
 SG_ RxErrCnt_ACU_PCAN : 39|8@0+ (1,0) [0|255] "" Vector__XXX
 SG_ MsgAliveCnt_ACU_PCAN : 63|8@0+ (1,0) [0|255] "" Vector__XXX
 SG_ DTCInfo_ACU_PCAN : 17|2@0+ (1,0) [0|3] ""  CGW
 SG_ CMXVersion_ACU_PCAN : 7|16@0+ (1,0) [0|65535] "" Vector__XXX
 SG_ BusOffCnt_ACU_PCAN : 55|8@0+ (1,0) [0|255] "" Vector__XXX

BO_ 1328 BCM_530h_TPMS: 8 BCM
 SG_ TMPIR : 63|2@0+ (1,0) [0|3] ""  CGW
 SG_ TMPI_S : 59|4@0+ (1,0) [0|11] ""  CGW
 SG_ TAS_F : 51|2@0+ (1,0) [0|3] ""  CGW
 SG_ TAS_R : 49|2@0+ (1,0) [0|3] ""  CGW
 SG_ TP_RR : 47|8@0+ (2.5,0) [0|637.5] "kPaG"  CGW
 SG_ TP_RL : 39|8@0+ (2.5,0) [0|637.5] "kPaG"  CGW
 SG_ TP_FR : 31|8@0+ (2.5,0) [0|637.5] "kPaG"  CGW
 SG_ TP_FL : 23|8@0+ (2.5,0) [0|637.5] "kPaG"  CGW
 SG_ TPV_RL : 15|1@0+ (1,0) [0|1] ""  CGW
 SG_ TPV_RR : 11|1@0+ (1,0) [0|1] ""  CGW
 SG_ TPV_FL : 7|1@0+ (1,0) [0|1] ""  CGW
 SG_ TPV_FR : 3|1@0+ (1,0) [0|1] ""  CGW
 SG_ TPS_RL : 14|3@0+ (1,0) [0|5] ""  CGW
 SG_ TPS_RR : 10|3@0+ (1,0) [0|5] ""  CGW
 SG_ TPS_FL : 6|3@0+ (1,0) [0|5] ""  CGW
 SG_ TPS_FR : 2|3@0+ (1,0) [0|5] ""  CGW

BO_ 1379 LDC_PCAN_STS: 8 LDC
 SG_ BusOffCnt_LDC_PCAN : 55|8@0+ (1,0) [0|255] "" Vector__XXX
 SG_ TxErrCnt_LDC_PCAN : 47|8@0+ (1,0) [0|255] "" Vector__XXX
 SG_ SupplyVoltage_LDC_PCAN : 31|8@0+ (0.1,0) [0|25.5] "V" Vector__XXX
 SG_ RxErrCnt_LDC_PCAN : 39|8@0+ (1,0) [0|255] "" Vector__XXX
 SG_ MsgAliveCnt_LDC_PCAN : 63|8@0+ (1,0) [0|255] "" Vector__XXX
 SG_ DTCInfo_LDC_PCAN : 17|2@0+ (1,0) [0|3] ""  CGW
 SG_ CMXVersion_LDC_PCAN : 7|16@0+ (1,0) [0|65535] "" Vector__XXX

BO_ 1380 OBC_PCAN_STS: 8 OBC
 SG_ BusOffCnt_OBC_PCAN : 55|8@0+ (1,0) [0|255] "" Vector__XXX
 SG_ CMXVersion_OBC_PCAN : 7|16@0+ (1,0) [0|65535] "" Vector__XXX
 SG_ DTCInfo_OBC_PCAN : 17|2@0+ (1,0) [0|3] ""  CGW
 SG_ MsgAliveCnt_OBC_PCAN : 63|8@0+ (1,0) [0|255] "" Vector__XXX
 SG_ RxErrCnt_OBC_PCAN : 39|8@0+ (1,0) [0|255] "" Vector__XXX
 SG_ SupplyVolt_OBC_PCAN : 31|8@0+ (0.1,0) [0|25.5] "V" Vector__XXX
 SG_ TxErrCnt_OBC_PCAN : 47|8@0+ (1,0) [0|255] "" Vector__XXX

BO_ 1298 VCU_512h: 8 VCU
 SG_ OCV : 35|12@0+ (0.001,10) [10|14] "V"  TESTER
 SG_ Norminal_Capacity : 31|8@0+ (1,0) [0|250] "Ah"  TESTER
 SG_ FSOH : 5|2@0+ (1,0) [0|3] ""  TESTER
 SG_ FSOC : 3|2@0+ (1,0) [0|3] ""  TESTER

BO_ 1297 BCM_511h: 8 BCM
 SG_ InteriorTailLampCmd : 33|1@0+ (1,0) [0|1] ""  CGW,HVAC
 SG_ RearDefoggerINDCmd : 31|2@0+ (1,0) [0|3] ""  CGW,HVAC
 SG_ BrakeLampFailSts : 29|2@0+ (1,0) [0|3] ""  CGW
 SG_ FrtSeatBeltINDCmd : 27|1@0+ (1,0) [0|1] ""  CGW
 SG_ RearSeatBeltWarnCmd : 26|1@0+ (1,0) [0|1] ""  CGW
 SG_ FrtSeatBeltWarnCmd : 25|2@0+ (1,0) [0|5] ""  CGW
 SG_ TailgateUnlatchSts : 39|1@0+ (1,0) [0|1] ""  CGW
 SG_ RearDoorLockUnSts : 38|1@0+ (1,0) [0|1] ""  CGW
 SG_ AutoPanelDimCmd_P : 32|1@0+ (1,0) [0|1] ""  SBWS,CGW,HVAC
 SG_ PsngrDoorLockUnSts : 37|1@0+ (1,0) [0|1] ""  CGW
 SG_ RearLHSeatBeltSts : 23|2@0+ (1,0) [0|3] ""  VCU,CGW,HVAC
 SG_ RearCntSeatBeltSts : 21|2@0+ (1,0) [0|3] ""  VCU,CGW,HVAC
 SG_ RearRHSeatBeltSts : 19|2@0+ (1,0) [0|3] ""  VCU,CGW,HVAC
 SG_ PsgnrSeatBeltSts : 17|2@0+ (1,0) [0|3] ""  VCU,CGW,HVAC
 SG_ DrivDoorAjarSts4P : 1|2@0+ (1,0) [0|3] ""  VCU,CGW
 SG_ DRLSts : 13|2@0+ (1,0) [0|3] ""  CGW,VCU,HVAC
 SG_ RearDefoggerActSts : 7|2@0+ (1,0) [0|3] ""  VCU,HVAC,CGW
 SG_ HeadLightOnOff4P : 11|2@0+ (1,0) [0|3] ""  CGW,VCU,HVAC
 SG_ FrontWiperMotorSts4P : 9|2@0+ (1,0) [0|3] ""  CGW,VCU
 SG_ DrivDoorLockUnSts : 36|1@0+ (1,0) [0|1] ""  VCU,CGW
 SG_ HoodAjarSts4p : 3|2@0+ (1,0) [0|3] ""  VCU,CGW
 SG_ DrivSeatBeltSts : 15|2@0+ (1,0) [0|3] ""  EBU,VCU,CGW,HVAC

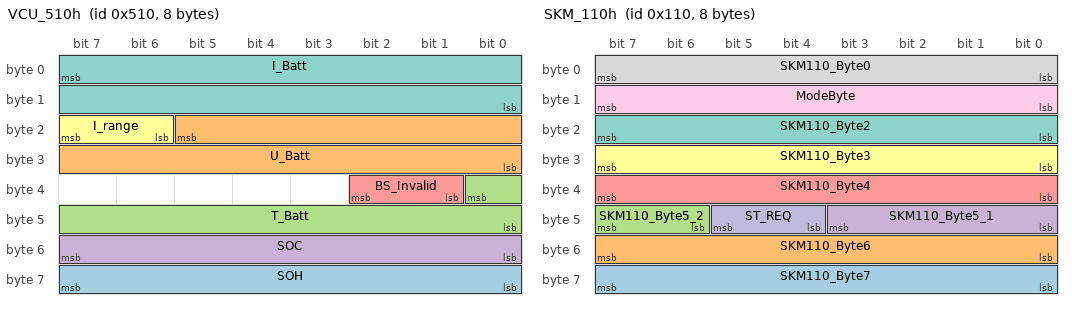
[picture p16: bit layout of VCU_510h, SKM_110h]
BO_ 1296 VCU_510h: 8 VCU
 SG_ SOH : 63|8@0+ (1,0) [0|100] "%"  TESTER,CGW
 SG_ U_Batt : 21|14@0+ (1,6000) [6000|18000] "mV"  TESTER,CGW
 SG_ T_Batt : 32|9@0+ (0.5,-40) [-40|125] "deg C."  TESTER,CGW
 SG_ SOC : 55|8@0+ (1,0) [0|100] "%"  TESTER,CGW
 SG_ BS_Invalid : 34|2@0+ (1,0) [0|3] ""  TESTER,CGW
 SG_ I_range : 23|2@0+ (1,0) [0|3] ""  TESTER,CGW
 SG_ I_Batt : 7|16@0+ (1,0) [0|65535] ""  TESTER,CGW

BO_ 1992 BS_DGN_RESP: 8 EBU
 SG_ DGN_RESP_ABS : 7|64@0+ (1,0) [0|0] ""  CGW

BO_ 1984 BS_DGN_REQ: 8 CGW
 SG_ DGN_REQ_ABS : 7|64@0+ (1,0) [0|0] ""  EBU

BO_ 1989 SKM_DGN_REQ: 8 CGW
 SG_ DGN_REQ_SKM : 7|64@0+ (1,0) [0|255] ""  SKM

BO_ 1997 SKM_DGN_RESP: 8 SKM
 SG_ DGN_RESP_SKM : 7|64@0+ (1,0) [0|255] ""  CGW

BO_ 272 SKM_110h: 8 SKM
 SG_ SKM110_Byte7 : 63|8@0+ (1,0) [0|255] "" Vector__XXX
 SG_ SKM110_Byte6 : 55|8@0+ (1,0) [0|255] "" Vector__XXX
 SG_ SKM110_Byte5_2 : 47|2@0+ (1,0) [0|3] "" Vector__XXX
 SG_ SKM110_Byte5_1 : 43|4@0+ (1,0) [0|15] "" Vector__XXX
 SG_ SKM110_Byte4 : 39|8@0+ (1,0) [0|255] "" Vector__XXX
 SG_ SKM110_Byte3 : 31|8@0+ (1,0) [0|255] "" Vector__XXX
 SG_ SKM110_Byte2 : 23|8@0+ (1,0) [0|255] "" Vector__XXX
 SG_ SKM110_Byte0 : 7|8@0+ (1,0) [0|255] "" Vector__XXX
 SG_ ModeByte : 15|8@0+ (1,0) [0|255] "" Vector__XXX
 SG_ ST_REQ : 45|2@0+ (1,0) [0|3] ""  VCU

BO_ 1585 VCU_CAL_631h: 8 VCU
 SG_ VCU_Calibration_631h_Signal : 7|64@0+ (1,0) [0|0] ""  CGW

BO_ 1584 VCU_CAL_630h: 8 CGW
 SG_ VCU_Calibration_630h_Signal : 7|64@0+ (1,0) [0|0] ""  VCU

BO_ 1666 BCM_CAL_RESP: 8 BCM
 SG_ BCM_CAL_RESP : 7|64@0+ (1,0) [0|0] ""  TESTER

BO_ 1665 BCM_CAL_REQ: 8 TESTER
 SG_ BCM_CAL_REQ : 7|64@0+ (1,0) [0|0] ""  BCM

BO_ 1801 BCM_DGN_RESP: 8 BCM
 SG_ DGN_RESP_BCM : 7|64@0+ (1,0) [0|0] ""  CGW

BO_ 1793 BCM_DGN_REQ: 8 CGW
 SG_ DGN_REQ_BCM : 7|64@0+ (1,0) [0|0] ""  BCM

BO_ 1746 TPMS_CAL_RESP: 8 BCM
 SG_ TPMS_CAL_RESP : 7|64@0+ (1,0) [0|0] ""  CGW

BO_ 1682 TPMS_CAL_REQ: 8 CGW
 SG_ TPMS_CAL_REQ : 7|64@0+ (1,0) [0|0] ""  BCM

BO_ 817 BS_331h_P: 8 EBU
 SG_ GIER_ROH : 55|16@0+ (0.01,-327.68) [-327.68|327.67] "deg/s" Vector__XXX
 SG_ LONG_ACCEL : 23|8@0+ (0.098,-12.446) [-12.446|12.544] "m/s^2" Vector__XXX
 SG_ PS_MEANVAL : 39|16@0+ (0.01,-40.96) [-40.96|614.39] "bar"  VCU,CGW
 SG_ LAT_ACCEL : 2|11@0+ (0.01,-10.23) [-10.23|10.24] "m/s^2" Vector__XXX

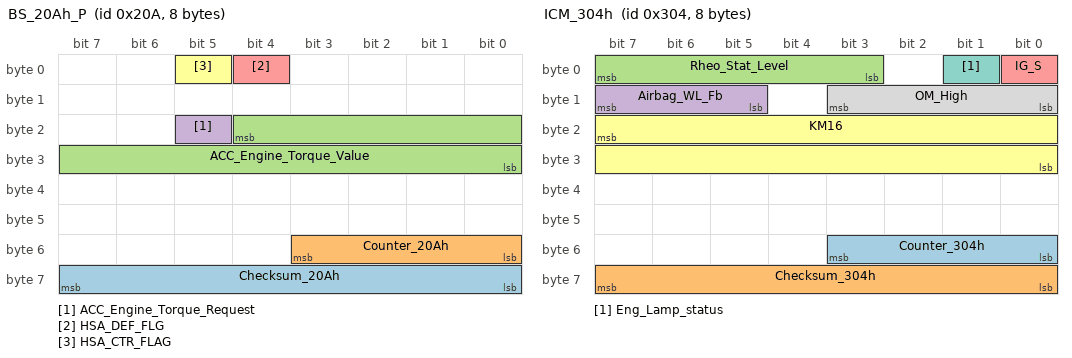
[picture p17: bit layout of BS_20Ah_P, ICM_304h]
BO_ 522 BS_20Ah_P: 8 EBU
 SG_ Checksum_20Ah : 63|8@0+ (1,0) [0|255] ""  VCU
 SG_ Counter_20Ah : 51|4@0+ (1,0) [0|15] ""  VCU
 SG_ ACC_Engine_Torque_Value : 20|13@0+ (0.3,-500) [-500|1548] "Nm"  VCU
 SG_ ACC_Engine_Torque_Request : 21|1@0+ (1,0) [0|1] "" Vector__XXX
 SG_ HSA_DEF_FLG : 4|1@0+ (1,0) [0|1] ""  VCU
 SG_ HSA_CTR_FLAG : 5|1@0+ (1,0) [0|1] ""  VCU

BO_ 561 EPS_231h: 8 CGW
 SG_ CheckSum : 63|8@0+ (1,0) [0|255] "" Vector__XXX
 SG_ MsgCount : 51|4@0+ (1,0) [0|15] "" Vector__XXX
 SG_ SAS_CAL : 25|1@0+ (1,0) [0|1] ""  BCM
 SG_ SAS_OK : 24|1@0+ (1,0) [0|1] ""  BCM
 SG_ SAS_Speed : 23|8@0+ (4,0) [0|1016] "deg/s" Vector__XXX
 SG_ SAS_Angle : 7|16@0+ (0.1,-3276.7) [-3276.7|3276.7] "deg"  BCM

BO_ 2024 VCU_DGN_RESP: 8 VCU
 SG_ DGN_RESP_VCU : 7|64@0+ (1,0) [0|0] ""  ECALL,CGW

BO_ 2016 VCU_DGN_REQ: 8 CGW
 SG_ DGN_REQ_VCU : 7|64@0+ (1,0) [0|0] ""  VCU

BO_ 261 VCU_105h: 7 VCU
 SG_ ECU_Immo : 7|56@0+ (1,0) [0|0] ""  SKM

BO_ 2015 DIAG_FUNC_REQ_OBD: 8 CGW
 SG_ DGN_REQ_OBD : 7|64@0+ (1,0) [0|0] "" Vector__XXX

BO_ 1792 DIAG_FUNC_REQ: 8 CGW
 SG_ DIAG_REQ_FUNC : 7|64@0+ (1,0) [0|0] ""  SBWS,BMS,EGP,OBC,VESS,LDC,EHVC,MCU,VCU,ECALL,HVAC,ACU,EBU,SKM,BCM

BO_ 772 ICM_304h: 8 CGW
 SG_ Counter_304h : 51|4@0+ (1,0) [0|15] "" Vector__XXX
 SG_ Checksum_304h : 63|8@0+ (1,0) [0|255] "" Vector__XXX
 SG_ Rheo_Stat_Level : 7|5@0+ (1,0) [0|31] ""  SBWS,HVAC
 SG_ Airbag_WL_Fb : 15|3@0+ (1,0) [0|7] "" Vector__XXX
 SG_ IG_S : 0|1@0+ (1,0) [0|1] "" Vector__XXX
 SG_ KM16 : 23|16@0+ (2,0) [0|99998] "km"  BMS,HVAC,VCU
 SG_ Eng_Lamp_status : 1|1@0+ (1,0) [0|1] ""  VCU
 SG_ OM_High : 11|4@0+ (100000,0) [0|1500000] "km"  VCU,HVAC,BMS

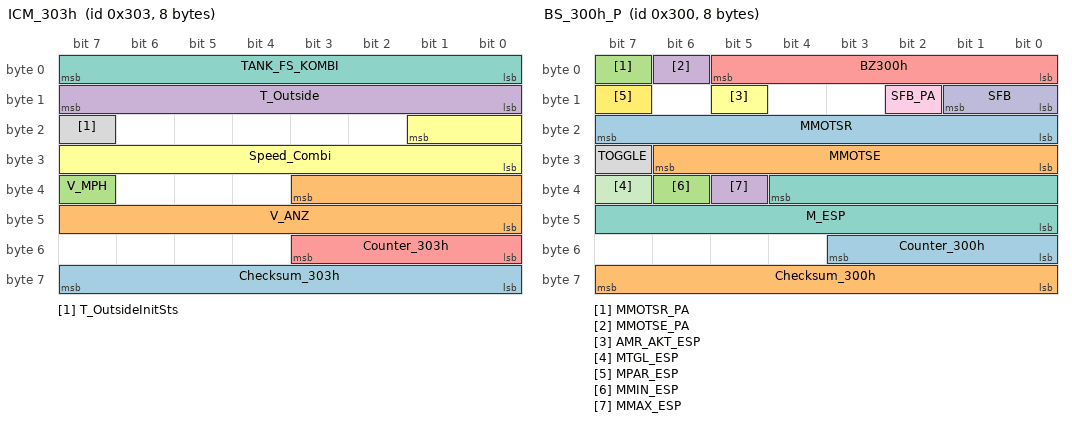
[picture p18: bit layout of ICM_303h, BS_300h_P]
BO_ 771 ICM_303h: 8 CGW
 SG_ Checksum_303h : 63|8@0+ (1,0) [0|255] ""  SBWS,VCU
 SG_ V_ANZ : 35|12@0+ (0.1,0) [0|409.4] "KPH/MPH"  VCU
 SG_ V_MPH : 39|1@0+ (1,0) [0|1] ""  VCU
 SG_ T_Outside : 15|8@0+ (0.5,-40) [-40|87.5] "deg C."  VCU,BCM,HVAC
 SG_ Counter_303h : 51|4@0+ (1,0) [0|15] ""  SBWS,VCU
 SG_ Speed_Combi : 17|10@0+ (1,0) [0|1023] "km/h"  BCM,BMS,HVAC,ECALL,SBWS,VCU,VESS
 SG_ TANK_FS_KOMBI : 7|8@0+ (1,0) [0|100] "L" Vector__XXX
 SG_ T_OutsideInitSts : 23|1@0+ (1,0) [0|1] "" Vector__XXX

BO_ 529 VCU_211h: 8 VCU
 SG_ Checksum_211h : 63|8@0+ (1,0) [0|255] ""  EGP,EBU
 SG_ Counter_211h : 51|4@0+ (1,0) [0|15] ""  EGP,EBU
 SG_ SMC_E_S : 13|3@0+ (1,0) [0|3] ""  HVAC,CGW,SKM
 SG_ VCU_transPmotorparkReq : 31|2@0+ (1,0) [0|2] ""  EGP
 SG_ ACC_ACT : 21|1@0+ (1,0) [0|1] ""  CGW,EBU
 SG_ M_FEV : 28|13@0+ (0.25,-500) [-500|1547.75] "Nm"  EBU
 SG_ M_ESP_E : 29|1@0+ (1,0) [0|1] ""  EBU
 SG_ PW_Virtual_Flag : 9|2@0+ (1,0) [0|2] ""  EBU
 SG_ SPDLIM_Ready : 16|1@0+ (1,0) [0|1] ""  CGW
 SG_ CAN_Engine_ACC_failure : 15|1@0+ (1,0) [0|1] ""  EBU
 SG_ CAN_Driver_Accel_Override : 14|1@0+ (1,0) [0|1] ""  EBU
 SG_ SPDLIM_Overspeed : 18|1@0+ (1,0) [0|1] ""  CGW
 SG_ SPDLIM_Override : 19|1@0+ (1,0) [0|1] ""  CGW
 SG_ SPDLIM_ACT : 17|1@0+ (1,0) [0|1] ""  CGW
 SG_ ACC_Ready : 20|1@0+ (1,0) [0|1] ""  CGW
 SG_ PW_ERR : 10|1@0+ (1,0) [0|1] ""  CGW
 SG_ PW : 7|8@0+ (0.4,0) [0|102] "%"  VESS,ACU,CGW,EBU

BO_ 816 BS_330h_P: 8 EBU
 SG_ EST_REF_VELOCITY : 47|16@0+ (0.01,0) [0|655.35] "km/h"  VCU,CGW
 SG_ Counter_330h : 7|4@0+ (1,0) [0|15] ""  VCU
 SG_ Checksum_330h : 63|8@0+ (1,0) [0|255] ""  VCU
 SG_ CPL_TQ_LIMIT : 15|16@0+ (1,0) [0|64255] "Nm" Vector__XXX
 SG_ RQ_Clutch_OP : 3|2@0+ (1,0) [0|3] "" Vector__XXX
 SG_ EBS_STATUS : 1|2@0+ (1,0) [0|3] ""  CGW,VCU,ACU

BO_ 768 BS_300h_P: 8 EBU
 SG_ Counter_300h : 51|4@0+ (1,0) [0|15] ""  VCU
 SG_ Checksum_300h : 63|8@0+ (1,0) [0|255] ""  VCU
 SG_ MMOTSR_PA : 7|1@0+ (1,0) [0|1] ""  VCU
 SG_ MMOTSE_PA : 6|1@0+ (1,0) [0|1] ""  VCU
 SG_ BZ300h : 5|6@0+ (1,0) [0|63] ""  VCU
 SG_ AMR_AKT_ESP : 13|1@0+ (1,0) [0|1] "" Vector__XXX
 SG_ M_ESP : 36|13@0+ (0.25,-500) [-500|1547.75] "Nm"  VCU
 SG_ TOGGLE : 31|1@0+ (1,0) [0|1] ""  VCU
 SG_ SFB_PA : 10|1@0+ (1,0) [0|1] "" Vector__XXX
 SG_ SFB : 9|2@0+ (1,0) [0|3] "" Vector__XXX
 SG_ MTGL_ESP : 39|1@0+ (1,0) [0|1] ""  VCU
 SG_ MPAR_ESP : 15|1@0+ (1,0) [0|1] ""  VCU
 SG_ MMOTSR : 23|8@0+ (3,0) [0|765] "Nm"  VCU
 SG_ MMOTSE : 30|7@0+ (3,0) [0|381] "Nm"  VCU
 SG_ MMIN_ESP : 38|1@0+ (1,0) [0|1] ""  VCU
 SG_ MMAX_ESP : 37|1@0+ (1,0) [0|1] ""  VCU

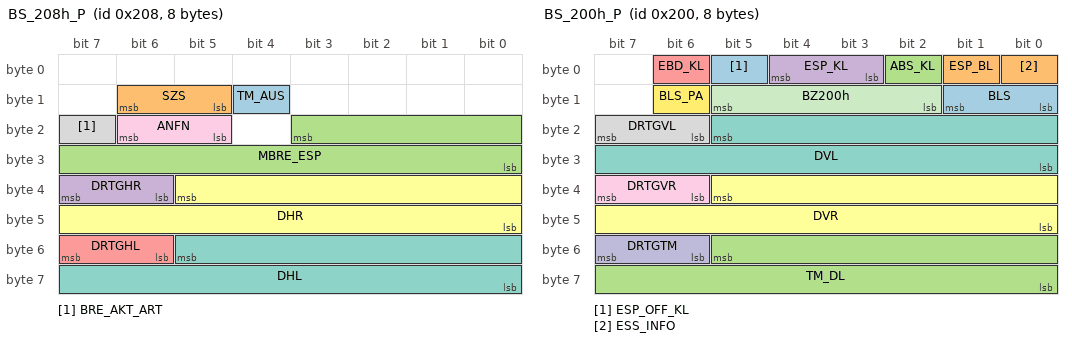
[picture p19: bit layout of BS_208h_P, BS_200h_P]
BO_ 520 BS_208h_P: 8 EBU
 SG_ TM_AUS : 12|1@0+ (1,0) [0|1] ""  CGW,VCU
 SG_ SZS : 14|2@0+ (1,0) [0|3] ""  CGW
 SG_ MBRE_ESP : 19|12@0+ (3,0) [0|12285] "Nm"  CGW
 SG_ DRTGHR : 39|2@0+ (1,0) [0|3] ""  CGW
 SG_ DRTGHL : 55|2@0+ (1,0) [0|3] ""  CGW
 SG_ DHR : 37|14@0+ (0.5,0) [0|8191.5] "1/min"  CGW,VCU,SKM
 SG_ DHL : 53|14@0+ (0.5,0) [0|8191.5] "1/min"  CGW,VCU,SKM
 SG_ BRE_AKT_ART : 23|1@0+ (1,0) [0|1] ""  CGW
 SG_ ANFN : 22|2@0+ (1,0) [0|3] ""  CGW

BO_ 512 BS_200h_P: 8 EBU
 SG_ ESP_OFF_KL : 5|1@0+ (1,0) [0|1] ""  CGW,ACU
 SG_ ESP_BL : 1|1@0+ (1,0) [0|1] ""  CGW,BCM
 SG_ TM_DL : 53|14@0+ (0.5,0) [0|8191.5] "1/min"  CGW,VCU
 SG_ ESP_KL : 4|2@0+ (1,0) [0|3] ""  CGW,ACU
 SG_ EBD_KL : 6|1@0+ (1,0) [0|1] ""  CGW
 SG_ DVR : 37|14@0+ (0.5,0) [0|8191.5] "1/min"  CGW,VCU,SKM
 SG_ DVL : 21|14@0+ (0.5,0) [0|8191.5] "1/min"  CGW,VCU,SKM
 SG_ DRTGVL : 23|2@0+ (1,0) [0|3] ""  CGW
 SG_ DRTGVR : 39|2@0+ (1,0) [0|3] ""  CGW
 SG_ DRTGTM : 55|2@0+ (1,0) [0|3] ""  CGW
 SG_ BZ200h : 13|4@0+ (1,0) [0|15] ""  SBWS,CGW,VCU
 SG_ BLS_PA : 14|1@0+ (1,0) [0|1] ""  SBWS,CGW,VCU
 SG_ BLS : 9|2@0+ (1,0) [0|3] ""  SBWS,CGW,VCU,ACU
 SG_ ESS_INFO : 0|1@0+ (1,0) [0|1] ""  CGW,BCM
 SG_ ABS_KL : 2|1@0+ (1,0) [0|1] ""  CGW

CM_ "Version 1.1
Version Date 2019-05-10

- Official Release";
CM_ BU_ EHVC "Electric HVAC Control Unit";
CM_ BU_ VESS "Virtual Engine Sound System";
CM_ BU_ SBWS "Shift By Wire Switch";
CM_ BU_ EGP "Electric Gear Parking";
CM_ BU_ OBC "On-board Charger";
CM_ BU_ LDC "Low DC Converter";
CM_ BU_ MCU "Motor Control Unit";
CM_ BU_ BMS "Battery Management System";
CM_ BU_ VCU "Vehicle Control Unit";
CM_ BU_ CGW "Central Gateway";
CM_ BU_ ECALL "Emergency Call";
CM_ BU_ ACU "Airbag Control Unit";
CM_ BU_ SKM "Smart Key Module";
CM_ BU_ EBU "Electronic Brake Unit";
CM_ BU_ BCM "Body Control Module";
CM_ BO_ 3221225472 "This is a message for not used signals, created by Vector CANdb++ DBC OLE DB Provider.";
CM_ SG_ 3221225472 SafetyUnlockSetSts "Safety Unlock Set Status";
CM_ SG_ 3221225472 ACC_RequiredAccel "ACC require acceleration (+ : accel. Request,  - : decel. request)";
CM_ SG_ 3221225472 ESCSetCmd "ESC Off-Road mode switch request by driver";
CM_ SG_ 3221225472 TCU_ISGStat_allow_PA "ISG allow by EMS Parity bit(even)";
CM_ SG_ 3221225472 ACC_StopReq "This signal is a control request flag for vehicle stop.  ACC expects vehicle to be controlled to a complete stop and hold its state.";
CM_ SG_ 3221225472 ALT_FB "Alternator feedback";
CM_ SG_ 3221225472 TCU_ISGStat_ready "ISG ready by TCU";
CM_ SG_ 3221225472 TCU_Cal_1 "CAN calibration";
CM_ SG_ 3221225472 NTURBINE "turbine speed";
CM_ SG_ 3221225472 MABS_SW_ANFB "absolute value of the transmission overall drive shaft torque";
CM_ SG_ 3221225472 VB "consumption";
CM_ SG_ 3221225472 T_MOT "engine coolant temperture";
CM_ SG_ 1732 MCU_Calibration_Resp "MCU Calibration Signal";
CM_ SG_ 1668 MCU_Calibration_Req "MCU Calibration Signal";
CM_ SG_ 941 VCU_STS_ESTM_DRV_Range_CLIMT_OFF "Vehicle speed as it is displayed in the speedometer for expected electric vehicle range with climate off(Estimated electric driving range)";
CM_ SG_ 941 VCU_Shift_CTRL_STS_WRN_MSG "Warning message of gear shift system";
CM_ SG_ 941 VCU_Shift_COND_Unmatch_WRN_MSG "Warning message of gear shifting condition";
CM_ SG_ 941 VCU_Charging_Sts_WRN_MSG "Warning message of charging system";
CM_ SG_ 941 VCU_LV_SYS_WRN_MSG "Warning message of LV system";
CM_ SG_ 941 VCU_HV_PWR_LMT_WRN_MSG "Warning message of HV Battery full dischage";
CM_ SG_ 941 VCU_Total_CHARG_PWR "Charging power(AC or DC)";
CM_ SG_ 941 VCU_HV_DISP_SOC "Display SOC(TBD)";
CM_ SG_ 941 VCU_EV_Power_Down_WRN_IND "EV Power Down Warning";
CM_ SG_ 941 VCU_HV_Low_SOC_WRN_IND "HV Battery Low Warning";
CM_ SG_ 941 VCU_LV_System_WRN_IND "LV System Fault Warning";
CM_ SG_ 851 BMS_BHC_Power "Battery Heater power consuption";
CM_ SG_ 851 BMS_InstantPowerConsumption "Instant Power Consumption";
CM_ SG_ 882 GoodbyeSoundCmd "Goodbye Sound Request to VESS";
CM_ SG_ 882 WelcomeSoundCmd "Welcome Sound Request to VESS";
CM_ SG_ 882 HazardSw "Hazard Switch";
CM_ SG_ 882 HeadLampHighSts "Head Lamp High Status";
CM_ SG_ 882 RainDetected "Rain detected status";
CM_ SG_ 836 VessSoundSetSts "Vess Sound Mode Set Status";
CM_ SG_ 836 VesstWarnCmd "Vess Warning Command";
CM_ SG_ 836 VessWelcomeOnOffSetSts "Vess Welcome Sound On/Off Set Status";
CM_ SG_ 854 HVAC_Sensor_DUCT "HVAC Duct Temp Sensor Value";
CM_ SG_ 854 HVAC_Sensor_EVA "HVAC EVA Temp Sensor Value";
CM_ SG_ 854 HVAC_Sensor_SUN "HVAC Sun Sensor Value";
CM_ SG_ 854 HVAC_Sensor_AMB "HVAC Ambient Sensor Value";
CM_ SG_ 854 HVAC_Sensor_ADS "HVAC ADS Sensor Value";
CM_ SG_ 492 AC_REF_OutHEX_Temp "AC Refrigerant OutHEX Temp";
CM_ SG_ 492 AC_REF_Low_Temp "AC Refrigerant Low Temp";
CM_ SG_ 492 AC_REF_Low_Pressure "AC Refrigerant Low Pressure";
CM_ SG_ 492 AC_REF_High_Temp "AC Refrigerant High Temp";
CM_ SG_ 491 Cabin_HTR_Power "CCU Cabin Heater Power";
CM_ SG_ 491 AC_REF_High_Pressure "AC Refrigerant High Pressure";
CM_ SG_ 519 REGEN_EXIT_MONITORING "Regenerative Brake Cooperation Exit Condition (WIll be deleted after completion of development)";
CM_ SG_ 519 DRIVER_REQ_PRESSURE "Driver brake pressure request (include ACC)";
CM_ SG_ 519 PTS_SNS_FAIL "Brake Pedal Travel Sensor Fail";
CM_ SG_ 519 PTS_CAL_STS "Pedal Travel Sensor Calibration Status
(Whether PTS calibration is done or not after installation on the vehicle)";
CM_ SG_ 519 REQ_COAST_REGEN_EXIT "Coast Regen, End Request signal";
CM_ SG_ 519 REGEN_REQ_TQ "Regenerative Request torque";
CM_ SG_ 519 REGEN_ENABLE_STS "Regenerative motor enable status of EBU";
CM_ SG_ 519 Counter_204h "Message Counter";
CM_ SG_ 519 Checksum_204h "Checksum";
CM_ SG_ 519 RBC_KL "RBC_Warning Lamp Signal (ON/OFF)";
CM_ SG_ 519 BBC_KL "BBC_Warning Lamp Signal (ON/OFF)";
CM_ SG_ 519 RBC_DEF "RBC_Defective Signal";
CM_ SG_ 519 BBC_DEF "BBC_Defective Signal";
CM_ SG_ 519 EBU_PW "Brake Pedal value (%)";
CM_ SG_ 853 HVAC_MODE_DEF_STS "HVAC Defrost Mode Sts";
CM_ SG_ 853 HVAC_Error_2 "HVAC Error Status 4";
CM_ SG_ 853 HVAC_Error_1 "HVAC Error Status 3";
CM_ SG_ 853 HVAC_Error_BLR "HVAC Error Status 2";
CM_ SG_ 853 HVAC_Error_TEMP "HVAC Error Status 1";
CM_ SG_ 853 HVAC_SetTemp_STS_R "HVAC Right Set Temp Status";
CM_ SG_ 853 HVAC_Temp_Act_STS_R "HVAC Right Temp Actuator Status";
CM_ SG_ 853 HVAC_SetTemp_STS_L "HVAC Set Temp Status";
CM_ SG_ 853 HVAC_Blower_STS "HVAC Blower Status";
CM_ SG_ 853 HVAC_Rec_STS "HVAC Recirculation Status";
CM_ SG_ 853 HVAC_Mode_STS "HVAC Mode Status";
CM_ SG_ 853 HVAC_Temp_Act_STS_L "HVAC Left Temp Actuator Status";
CM_ SG_ 853 HVAC_DEF_STS "HVAC DEFOG Status";
CM_ SG_ 853 HVAC_HEX_ICING_STS "HVAC OutHex Icing Status";
CM_ SG_ 853 HVAC_Heating_STS "HVAC Heating Status";
CM_ SG_ 853 HVAC_Cooling_STS "HVAC Cooling Status";
CM_ SG_ 831 Error2 "EHVC Error Status 4";
CM_ SG_ 831 Error1 "EHVC Error Status 3";
CM_ SG_ 831 Component_Error "EHVC Error Status 2";
CM_ SG_ 831 Mode_Error "EHVC Error Status 1";
CM_ SG_ 831 Mode_Req "HVAC Mode Req";
CM_ SG_ 831 Rec_Req "HVAC Recirculation Req";
CM_ SG_ 831 Blower_Step_Req "Blower_Step_Req";
CM_ SG_ 831 DATC_STS_CHILLER "Battery Chiller On/OFF Status";
CM_ SG_ 831 EHVC_OP_Mode_Req "EHVCU Operation Mode Req";
CM_ SG_ 831 Temp_Act_Pos_Req_R "Temp door actuator request Right";
CM_ SG_ 831 Temp_Act_Pos_Req_L "Temp door actuator request Left";
CM_ SG_ 831 FourWay_Valve_STS "CCU 4Way Valve Status";
CM_ SG_ 831 Cabin_HTR_Coolant_Temp "CCU Cabin Heater Coolant Temp";
CM_ SG_ 831 Cabin_HTR_Current "CCU Cabin Heater Control Status";
CM_ SG_ 488 Counter_1E8h "Rolling Counter";
CM_ SG_ 488 Checksum_1E8h "Checksum";
CM_ SG_ 488 Pmotor_Error_Level "Send internal state error ";
CM_ SG_ 488 Pmotor_Position_Status "Parking Motor Position Status";
CM_ SG_ 488 Pmotor_Position_Failure "Parking Motor Position Failure Status";
CM_ SG_ 488 EGP_OperationMode "Operation mode of ECU";
CM_ SG_ 488 Shifting_In_Progress "Shifting in Progress";
CM_ SG_ 488 EGP_Service_WRN_IND "Service warning";
CM_ SG_ 487 SBW_ShutDown_Timer "SBW Shutdown Timer";
CM_ SG_ 487 SBW_STS "SBW Diagnosis Status";
CM_ SG_ 487 Counter_1E7h "Message Counter";
CM_ SG_ 487 Checksum_1E7h "Checksum";
CM_ SG_ 487 SBWS_STS_Parking_Release_SW "Parking release button
(For changing P to N after Key off)";
CM_ SG_ 487 SBWS_Lever "Shift Lever Position";
CM_ SG_ 487 SBW_WRN_MSG "Check shift controls  there is problem with the shift lever or button.";
CM_ SG_ 929 LDC_STS_CURR_OUT "LDC output current";
CM_ SG_ 929 LDC_STS_CURR_IN "LDC input current";
CM_ SG_ 929 LDC_STS_VOLT_OUT "LDC output voltage";
CM_ SG_ 929 LDC_STS_VOLT_IN "LDC input voltage";
CM_ SG_ 928 Counter_3A0h "Message Counter";
CM_ SG_ 928 LDC_Service_WRN_IND "LDC low voltage system failure warning message a failure occurs in the power supply system(LDC).";
CM_ SG_ 928 LDC_Out_Emergency "LDC low voltage system fault warning message a fault occurs in the power supply system(LDC).";
CM_ SG_ 928 LDC_Out_Mode "LDC Operatong mode state information";
CM_ SG_ 928 Checksum_3A0h "Checksum";
CM_ SG_ 928 LDC_STS_TEMP "LDC temperature";
CM_ SG_ 928 LDC_STS_Power_OUT "LDC output power";
CM_ SG_ 928 LDC_STS_MODE "LDC Protection Status";
CM_ SG_ 928 LDC_STS_Ready "LDC ready signal";
CM_ SG_ 803 BMS_BHC_STS_ERR "Battery Heater Relay Coil ERR";
CM_ SG_ 803 BMS_CoolingPumpFeedbackStatus "Status of feedback for BMS water pump";
CM_ SG_ 803 BMS_BatteryMaxTempLocation "Battery Max Temperature sensor location
* DEV message : It will be removed after SOP";
CM_ SG_ 803 BMS_BatteryMinTempLocation "Battery Min Temperature sensor location
* DEV Message : it will be removed after SOP";
CM_ SG_ 803 BMS_AuxBattery "12V Battery voltage (LV Connector)";
CM_ SG_ 803 BMS_BHC_STS_WHU_WT_O "Inlet Water Temperature";
CM_ SG_ 803 BMS_BatteryAvgTemperature "Battery Average temperature";
CM_ SG_ 803 BMS_BatteryMaxTemperature "Battery Max temperature";
CM_ SG_ 803 BMS_BatteryMinTemperature "Battery Min temperature";
CM_ SG_ 803 BMS_BHC_STS_OW_TS "Inlet water temperature sensor abnormality";
CM_ SG_ 803 BMS_ChargingStop "BMS request Charging stop";
CM_ SG_ 803 BMS_CoolingRequest "BMS request Cooling(Acomp On/Chiller On)";
CM_ SG_ 850 BMS_BAT_STS_MSG "BMS_BatteryPackStatus(0x0, 0x1) = 0
BMS_BatteryPackStatus(0x2, 0x3,0x4,0x5) = 1";
CM_ SG_ 850 HV_BAT_Over_Temp_MSG "HV Battery over temp warning message

to protect battery and electric vehicle system when the high voltage battery temperature is too high.
";
CM_ SG_ 850 HV_BAT_Low_Temp_Power_Limit_MSG "HV Battery low temp power limited message

to protect battery and electric vehicle system when the high voltage battery temperature is too low.
";
CM_ SG_ 850 BMS_BatteryPackSOH "Battery Pack SOH";
CM_ SG_ 850 BMS_BatteryPackSOE "Battery Remaning Capacity";
CM_ SG_ 850 BMS_BatteryPackRSOC "Battery Pack RSOC (Relative)
-> Display on cluster (0~100%)";
CM_ SG_ 849 VCU_STS_DC_CHARG_EST_COMPLT_MINT "Estimated Charging completion Time(Minute)  based on current SOC";
CM_ SG_ 849 VCU_STS_DC_CHARG_EST_COMPLT_Hour "Estimated Charging completion Time(Hour)  based on current SOC";
CM_ SG_ 849 VCU_STS_AC_LV2_CHARG_COMPLT_MINT "Estimated Charging completion Time(Minute)  based on current SOC";
CM_ SG_ 849 VCU_STS_AC_LV2_CHARG_COMPLT_Hour "Estimated Charging completion Time(Hour) based on current SOC";
CM_ SG_ 849 VCU_STS_AC_LV1_CHARG_COMPLT_MINT "Estimated Charging completion Time(Minute)  based on current SOC";
CM_ SG_ 849 VCU_STS_AC_LV1_CHARG_COMPLT_Hour "Estimated Charging completion Time(Hour) based on current SOC";
CM_ SG_ 849 VCU_STS_CHARG_COMPLT_MINT "Estimated Charging completion Time(Minute) during charging";
CM_ SG_ 849 VCU_STS_CHARG_COMPLT_Hour "Estimated Charging completion Time(Hour) during charging";
CM_ SG_ 830 eComp_Battery_Voltage "eComp Battery Voltage";
CM_ SG_ 830 eComp_Inverter_Temp "eComp Inverter Temp";
CM_ SG_ 830 eComp_Phase_Current "eComp Phase Current";
CM_ SG_ 830 eComp_Power "eComp Drive RPM";
CM_ SG_ 830 eComp_Drive_RPM "eComp Drive RPM";
CM_ SG_ 830 eComp_Communication_Fault "eComp Communication_Abnormal_Fault";
CM_ SG_ 830 eComp_Thermistor_Fault "eComp Thermistor_Abnormal_Fault";
CM_ SG_ 830 eComp_Internal_Error_Fault "eComp Internal_Error_Fault";
CM_ SG_ 830 eComp_Missed_Restart_Fault "eComp Missed_Restart_Fault";
CM_ SG_ 830 eComp_Over_Temperature "eComp Over Temperature";
CM_ SG_ 830 eComp_Over_Load "eComp Over Load";
CM_ SG_ 830 eComp_High_Voltage_Fault "eComp High Voltage_Fault";
CM_ SG_ 830 eComp_Low_Voltage_Fault "eComp Low_Voltage_Fault";
CM_ SG_ 830 eComp_Line_Open_Fault "eComp Line_Open_Fault";
CM_ SG_ 830 eComp_HW_Fault "eComp HW_fault";
CM_ SG_ 940 VCU_HV_ACT_IND "HV System Activation Indication";
CM_ SG_ 940 VCU_IGN4_STS "AC Charging VCU Request";
CM_ SG_ 940 VCU_IGN3_STS "AC Charging VCU Request";
CM_ SG_ 940 CruiseTargetKPH "Cruise target speed to display (km/h)";
CM_ SG_ 940 Charging_Sts_IND "Battery charging On
- Red: Being charged
- Green: Charging completed ";
CM_ SG_ 940 VCU_Service_WRN_IND "Service Warning Lamp
EV control system failure by sensor, actuator etc";
CM_ SG_ 940 ECO_Guide_Level_IND "Eco guide level indicatoin on Cluster/AVN";
CM_ SG_ 940 ECO_Energy_Flow_IND "Energy Flow indicatoin on Cluster/AVN";
CM_ SG_ 940 VCU_Cert_Status "Certification mode Activitation Status for EBU/Cluster";
CM_ SG_ 940 CruiseTargetMPH "Cruise target speed to display (Mile/h)";
CM_ SG_ 940 Charging_DR_STS "Charging Door Open/Closed Status";
CM_ SG_ 940 DrivingMode_VCU "Actual Driving Mode from VCU ";
CM_ SG_ 940 DrivingModeDisplay "Driving Mode Display";
CM_ SG_ 581 DrivingPosition "Driving Position";
CM_ SG_ 581 Counter_245h "Rolling Counter";
CM_ SG_ 581 Checksum_245h "Checksum";
CM_ SG_ 581 VCU_STS_ESTM_DRV_Range "Vehicle speed as it is displayed in the speedometer for expected electric vehicle range(Estimated electric driving range.)";
CM_ SG_ 581 VCU_Ready "Electric Powertrain System Ready for driving.";
CM_ SG_ 581 Immo_light "immobilizer indicator";
CM_ SG_ 467 VCU_CMD_CHAR_PWM "Charging PWM(Duty)";
CM_ SG_ 467 VCU_CMD_CHAR_PD "Charing Inlet PD Status";
CM_ SG_ 467 VCU_CMD_CHAR_CP "AC CP Voltage Status";
CM_ SG_ 467 VCU_STS_Paddle_LV "Paddle(Regenerative) level status";
CM_ SG_ 467 VCU_STS_CHARG_PLG_AT_Lock_SW "Charging Plug Auto Lock Switch Status";
CM_ SG_ 467 VCU_STS_CHARG_RLS_SW "Reservation Charging Release Switch Status";
CM_ SG_ 467 VCU_STS_VEH_Mode "Vehicle Chaging Status";
CM_ SG_ 467 VCU_ChargeConnectionStatus "Charger connection status";
CM_ SG_ 467 Counter_1D3h "Rolling Counter";
CM_ SG_ 467 Checksum_1D3h "Checksum";
CM_ SG_ 467 CoastRegenTorque "Coast Regenerative Target Torque";
CM_ SG_ 467 VCU_CMD_AC_CHARG_ST_REQ "AC Charging VCU Request";
CM_ SG_ 466 VCU_EPBoperatingReq "EPB operating request";
CM_ SG_ 466 Counter_1D2h "Rolling Counter";
CM_ SG_ 466 Checksum_1D2h "Checksum";
CM_ SG_ 466 VCU_REQ_Brake_Light_On "Brake light on requet for regenerative braking";
CM_ SG_ 466 VCU_REQ_LMT_CABN_Heater_PWR "Cabin Heater Power Limitation";
CM_ SG_ 466 VCU_REQ_LMT_ACOMP_PWR "Air compressor Power Limitation";
CM_ SG_ 466 VCU_REQ_LMT_Blower_Step "Blower Step Limitation";
CM_ SG_ 466 VCU_REQ_EN_CABN_Heater "Cabin Heater On Enable
(Disable -> Do not use HV Power)";
CM_ SG_ 466 VCU_REQ_EN_ACOMP "Air Compressor On Enable
(Disable -> Do not use HV Power)";
CM_ SG_ 466 VCU_CMD_LDC_TARGT_VOLT "Low Votage(12V) Output LDC Target voltage";
CM_ SG_ 466 VCU_CMD_EN_LDC "LDC Enable";
CM_ SG_ 466 VCU_STS_REGN_AVAIL_TQ "Regenerative Available torque";
CM_ SG_ 466 VCU_STS_REGN_AVAIL_STS_EPT "Regenerative motor enable status of EPT system(VCU/MCU)";
CM_ SG_ 465 Checksum_1D1h "Checksum";
CM_ SG_ 465 Counter_1D1h "Rolling Counter";
CM_ SG_ 465 VCU_CMD_AC_CHARG_TARGT_CURNT "Charging Target Current (from VCU Request to OBC / Charging Stand)";
CM_ SG_ 465 VCU_CMD_AC_CHARG_TARGT_VOLT "Charging Target Voltage (from VCU Request to OBC / Charging Stand)";
CM_ SG_ 465 VCU_CMD_EN_OBC "OBC Enable";
CM_ SG_ 465 VCU_CMD_AC2_CHARG_CRT_SET "AC Level2 Charging Current Limitation(Minimum/Medium/Maximum)";
CM_ SG_ 465 VCU_CMD_AC1_CHARG_CRT_SET "AC Level1 Charging Current Limitation(Minimum/Medium/Maximum)";
CM_ SG_ 584 RemoteStartSts "Remote Engine Start Status according to Connected or STPM request";
CM_ SG_ 464 VoiceHvacTempUpDnCmd "Voice Command for HVAC temperature up/down command";
CM_ SG_ 464 VoiceHvacBlowerUpDnCmd "Voice Command for HVAC blower step up/down command";
CM_ SG_ 464 VoiceHvacBlowerSetCmd "Voice Command for HVAC blower set command";
CM_ SG_ 464 VoiceHvacTempSetCmd "Voice Command for HVAC Temperature Set Command";
CM_ SG_ 464 VoiceHvacCmd "Voice Command for HVAC";
CM_ SG_ 464 VoiceHvacRecCmd "Voice Command for HVAC Rec Set On command";
CM_ SG_ 458 HvacDrTempSetSts "Remote Control HVAC, Set Temperature";
CM_ SG_ 450 RemoteHvacDrTempSet "Remote Control HVAC, Set Temperature";
CM_ SG_ 1597 TPMS_Debug "TPMS Debug signal, cyclic 10ms";
CM_ SG_ 304 CF_Yrs_MCUStat_BusOff "Status information for MCU : Bus Off";
CM_ SG_ 304 CF_Yrs_MCUStat_OV "Status information for MCU : Overvoltage";
CM_ SG_ 304 CF_Yrs_MCUStat_UV "Status information for MCU : Undervoltage";
CM_ SG_ 304 CF_Yrs_MCUStat_Fail "Status information for MCU : Failure";
CM_ SG_ 304 CR_Yrs_Crc1 "Cyclic redundancy check";
CM_ SG_ 304 CR_Yrs_MsgCnt1 "Message Counter";
CM_ SG_ 304 CF_Yrs_LatAc_Init "Status information for Lateral acceleration signal : Initialization";
CM_ SG_ 304 CF_Yrs_LatAc_Fail "Status information for Lateral acceleration signal : Failure";
CM_ SG_ 304 CF_Yrs_Yr_Init "Status information for Yaw rate signal : Initialization";
CM_ SG_ 304 CF_Yrs_Yr_Fail "Status information for Yaw rate signal : Failure";
CM_ SG_ 304 CR_Yrs_LatAc "Lateral acceleration";
CM_ SG_ 304 CR_Yrs_Yr "Yaw rate ";
CM_ SG_ 320 CF_Yrs_Type "Supported signal information";
CM_ SG_ 320 YRS_Temp_Stat "Temperature status";
CM_ SG_ 320 CF_ISC_ResetStat "This signal indicates information regarding ISC Reset Status";
CM_ SG_ 320 CR_Yrs_MsgCnt2 "Cyclic redundancy check";
CM_ SG_ 320 CR_Yrs_Crc2 "Message Counter";
CM_ SG_ 320 CR_Yrs_Temp "Sensor temperature";
CM_ SG_ 320 CR_Yrs_LongAc_Init "Status information for AX signal : Initialization";
CM_ SG_ 320 CR_Yrs_LongAc_Fail "Status information for AX signal : Failure";
CM_ SG_ 320 CR_Yrs_LongAc "Longitudinal acceleration";
CM_ SG_ 1416 VC_4WD "vehicle code, 4WD";
CM_ SG_ 1416 VC_TPMS "vehicle code, TPMS";
CM_ SG_ 1416 VC_STPM "vehicle code, STPM System";
CM_ SG_ 1416 VC_SKM "vehicle code, Smart Key System";
CM_ SG_ 1416 VC_RHD "Variant Coding for Driver Handle";
CM_ SG_ 1416 VC_Audio "vehicle code, Audio System";
CM_ SG_ 1416 VC_AT "vehicle code, Automatic Transmission";
CM_ SG_ 1416 VC_EPS "vehicle code, electric steering";
CM_ SG_ 1416 VC_BS "vehicle code, Brake System";
CM_ SG_ 1416 Brake_Variant "Brake Variant";
CM_ SG_ 1416 VC_Validity "vehicle code, Validity Flag";
CM_ SG_ 1416 VC_Project "vehicle code, Project Code";
CM_ SG_ 1416 VC_DOM "vehicle code, Domestic/Export";
CM_ SG_ 1416 VC_CCU "vehicle code, Connectivity System";
CM_ SG_ 1416 VC_PTG "vehicle code, Power Tailgate System";
CM_ SG_ 1416 VC_BSD "vehicle code, BSD System";
CM_ SG_ 1416 VC_WPC "vehicle code, Wireless Charger";
CM_ SG_ 352 Counter_160h "Rolling Counter";
CM_ SG_ 352 Checksum_160h "Checksum";
CM_ SG_ 352 DrivingModeSW "Driving Mode Switch";
CM_ SG_ 352 StrgHeatSW "Sterring Wheel Heating Switch";
CM_ SG_ 352 PaddleDownSW "Paddle Shift Down Switch input";
CM_ SG_ 352 PaddleUpSW "Paddle Shift Up Switch input";
CM_ SG_ 352 ACC_DistanceSW "ACC Distance Switch input";
CM_ SG_ 352 ACC_Decel_SET_SW "ACC Decel Switch input";
CM_ SG_ 352 ACC_Accel_RES_SW "ACC Accel Switch input";
CM_ SG_ 352 SpeedLimitSW "Speed Limit On/Ready/Off Switch input";
CM_ SG_ 352 ACC_SW "ACC On/Ready/Off Switch input";
CM_ SG_ 1587 VCU_Calibration_633h_Signal "EMS Calibration Signal";
CM_ SG_ 1588 VCU_Calibration_634h_Signal "EMS Calibration Signal";
CM_ SG_ 1586 VCU_Calibration_632h_Signal "EMS Calibration Signal";
CM_ SG_ 353 STPMStartCmd "Remote Engine Start/Stop Command";
CM_ SG_ 353 STPMFobAuthentiCmd "FOB Authentication Request by STPM";
CM_ SG_ 601 NICC_Opt "NICC System Option Info.";
CM_ SG_ 601 NICC_SysState "NICC System State";
CM_ SG_ 601 Counter_259h "Message Counter";
CM_ SG_ 601 Checksum_259h "Checksum";
CM_ SG_ 601 ACC_Target_Validity "Display flag to inform detection of preceding vehicle.";
CM_ SG_ 601 ACC_Disp_Information "Information provided to the driver.";
CM_ SG_ 601 ACC_DrvSel_Distance "Driver selected distance which is informed as time-gap.";
CM_ SG_ 601 ACC_DrvSel_Speed "Driver selected speed";
CM_ SG_ 601 ACC_WarningLamp "ACC system codition";
CM_ SG_ 601 ACC_DriveMode "Drive mode which is selected by a driver";
CM_ SG_ 601 ACC_Mode "Operating mode of ACC";
CM_ SG_ 601 ACC_SystemState "Status of ACC system On/Off";
CM_ SG_ 277 SKM_Immo "FBS_Authentic";
CM_ SG_ 864 Counter_360h "Message Counter";
CM_ SG_ 864 Checksum_360h "Checksum";
CM_ SG_ 864 ESP_CtrMode "DST Control Mode";
CM_ SG_ 864 STR_TQR_REQ "Steering torque request (Output torque overlay)";
CM_ SG_ 864 DST_DEF "DST defective";
CM_ SG_ 864 DST_ACT "DST active";
CM_ SG_ 864 ESC_mode "ESC mode status";
CM_ SG_ 864 AVH_DRIVER_WARNING "AVH Text output request for cluster display";
CM_ SG_ 864 AVH_LAMP_INFO "AVH Infor lamp request to cluster (Green/White/Yellow)";
CM_ SG_ 864 AVH_CTL_STATUS "State of hydraulic Hold by AVH";
CM_ SG_ 864 HDC_WL "HDC Warning Lamp";
CM_ SG_ 864 HDC_FL "HDC Function Lamp";
CM_ SG_ 832 Counter_340h "Message Counter";
CM_ SG_ 832 Checksum_340h "Checksum";
CM_ SG_ 832 EPB_RBLRQ "Rear brake light activation request";
CM_ SG_ 832 EPB_Fail_Info "EPB failure information ";
CM_ SG_ 832 EPB_Status "Actuator status of EPB";
CM_ SG_ 832 EPB_Switch "Status of EPB control switch";
CM_ SG_ 832 EPB_Display "EPB Text output request for cluster  display";
CM_ SG_ 832 EPB_Alarm "EPB Warning Alarm output request";
CM_ SG_ 832 EPB_Fail_Lamp "EPB Failure lamp request for cluster ";
CM_ SG_ 832 EPB_Info_Lamp "Parking Brake Info lamp request for cluster";
CM_ SG_ 563 WHL_PULSE_RL "RL Wheel Pulse Count";
CM_ SG_ 563 WHL_PULSE_RR "RR Wheel Pulse Count";
CM_ SG_ 563 WHL_PULSE_FR "FR Wheel Pulse Count";
CM_ SG_ 563 WHL_PULSE_FL "FL Wheel Pulse Count";
CM_ SG_ 1096 NM_WakeupReason_CGW "Not used of BatteryAttachment value";
CM_ SG_ 1096 NM_FormerState_CGW "CGW sends always value 0x0";
CM_ SG_ 481 MotorTorqueEstimated_RS1 "Motorization estimated electric torque at the motor output shaft";
CM_ SG_ 481 MotorTorqueEstimated "Motorization estimated electric torque at the motor output shaft";
CM_ SG_ 481 Counter_1E1h "Message Counter";
CM_ SG_ 481 Checksum_1E1h "Checksum";
CM_ SG_ 937 OBC_DC_Output_I "Output Current";
CM_ SG_ 937 OBC_DC_Output_V "Output Voltage";
CM_ SG_ 937 OBC_AC_I_rms "AC Input Source Current(rms)";
CM_ SG_ 937 OBC_AC_V_rms "AC Input Source Voltage(rms)";
CM_ SG_ 936 OBC_STS_CHECK_ID "OBC System code ID information";
CM_ SG_ 936 OBC_STS_CHECK_GROUP "OBC System code group information";
CM_ SG_ 936 OBC_STS_TEMP "OBC Representative temperature";
CM_ SG_ 936 OBC_STS_PC_State "OBC Power controller status";
CM_ SG_ 936 OBC_STS_SC_State "OBC System controller status";
CM_ SG_ 936 OBC_STS_Precharge_Step "OBC Precharging sequence status";
CM_ SG_ 936 OBC_STS_PWR_LIM_2 "OBC Power limit by Main Source unstable";
CM_ SG_ 936 OBC_STS_PWR_LIM_1 "OBC Power limit by internal High Temperature";
CM_ SG_ 936 OBC_STS_FLT "OBC Fault Status";
CM_ SG_ 936 OBC_STS_WRN "OBC Warnning Status";
CM_ SG_ 936 OBC_STS_Temporary_Stop "OBC Temporary Stop status";
CM_ SG_ 936 OBC_STS_AC_DETECT "OBC Main(AC) Source Detection";
CM_ SG_ 936 OBC_CMD_Chg_Finished "OBC Charge finish request";
CM_ SG_ 936 OBC_STS_CONTRAB "OBC Controlable status";
CM_ SG_ 936 OBC_STS_Ready "OBC ready signal";
CM_ SG_ 336 VessWelcomeOnOffSetCmd "Vess Welcome Sound On/Off Set Command";
CM_ SG_ 336 LongTermParkSetCmd "Outside FOB Searching Off Set Command";
CM_ SG_ 336 SafetyUnlockSetCmd "Safety Unlock Set Command";
CM_ SG_ 336 TSRSetCmd "TSR System Switch";
CM_ SG_ 336 SDWSetCmd "SDW mode switch request by driver";
CM_ SG_ 336 DDWSetCmd "DDW mode switch request by driver";
CM_ SG_ 336 ACC_DriveMode_SetCmd "ACC Driving Mode Switch";
CM_ SG_ 336 ACCwSteerSetCmd "ACCwSteer mode switch request by driver";
CM_ SG_ 336 LKASSetCmd "LDW/LKAS Mode Switch";
CM_ SG_ 336 ComeHomeLampSetCmd "Headlamp Escort Set Up Command";
CM_ SG_ 336 PTGSmartSetCmd "Smart Tailgate Set Up Command";
CM_ SG_ 336 DoorUnlockSetCmd "Auto Door Unlock Set Up Command";
CM_ SG_ 336 DoorLockSetCmd "Auto Door Lock Set Up Command";
CM_ SG_ 336 FactoryModeSetCmd "Factory Mode Command";
CM_ SG_ 336 LeaveHomeLampSetCmd "Headlamp Escort Set Up Command";
CM_ SG_ 336 DoorLockSpeedSetCmd "Auto Door Lock Speed Set Up Command";
CM_ SG_ 336 AutoLockSetCmd "Auto Lock Set Up Command";
CM_ SG_ 336 AutoApproachSetCmd "Auto Approach Welcome Set Up Command";
CM_ SG_ 336 ApproachLampSetCmd "Approach Lamp Set Up Command";
CM_ SG_ 336 AlarmBuzzSetCmd "Alarm Sound Set Up Command";
CM_ SG_ 336 WPCSetCmd "WPC Off/On Command";
CM_ SG_ 336 PTGModeSetCmd "PTG Mode Set Up Command";
CM_ SG_ 336 FCWSetCmd "FCW mode switch request by driver";
CM_ SG_ 336 AEBSetCmd "AEB Cluster switch request by driver";
CM_ SG_ 336 VessSoundSetCmd "Vess Sound Mode Set Command";
CM_ SG_ 336 FVSASetCmd "FVSA mode switch request by driver";
CM_ SG_ 1299 Brake_Variant "Brake Variant";
CM_ SG_ 821 PAB_On "PAB On Lamp On Command";
CM_ SG_ 821 PAB_Off "PAB Off Lamp Command";
CM_ SG_ 821 Airbag_WL "Airbag Warning Lamp";
CM_ SG_ 309 Counter_135h "Message Counter";
CM_ SG_ 309 Checksum_135h "Checksum";
CM_ SG_ 309 ACU_Crashout "ACU Crash Out";
CM_ SG_ 565 RearDefoggerSwSts "Rear Defogger Switch Status";
CM_ SG_ 565 HP_Req "Heat Pump On Req";
CM_ SG_ 565 HVAC_Option "A/C Option ";
CM_ SG_ 565 Incar_Temp "A/C FATC Incar Sensor Value";
CM_ SG_ 565 HVAC_Mode_Status "A/C Control MODE Status";
CM_ SG_ 565 HvacMaxModeSts "HVAC Maximum mode status";
CM_ SG_ 565 AC_Req "Air Compressor On Req";
CM_ SG_ 565 HVAC_Target_Discharge_Temp_L "HVAC Target Discharge Temp Left";
CM_ SG_ 565 HVAC_Target_Discharge_Temp_R "HVAC Target Discharge Temp Right";
CM_ SG_ 565 HVAC_TEMP_Status "A/C FATC TEMP Status";
CM_ SG_ 565 FAN_Status "Blower FAN ON Status";
CM_ SG_ 2041 DGN_ACU_Scrap_Response "Scrap Respose";
CM_ SG_ 2033 DGN_ACU_Scrap_Request "Scrap Request";
CM_ SG_ 1328 TMPIR "Tire Pressure Monitoring Indication Request (Optional)";
CM_ SG_ 1328 TMPI_S "Tire Pressure And Inflation Monitoring Status";
CM_ SG_ 1328 TAS_F "Tire Front Axle Status";
CM_ SG_ 1328 TAS_R "Tire Rear Axle Status";
CM_ SG_ 1328 TP_RR "Tire Right Rear Pressure";
CM_ SG_ 1328 TP_RL "Tire Left Rear Pressure";
CM_ SG_ 1328 TP_FR "Tire Right Front Pressure";
CM_ SG_ 1328 TP_FL "Tire Left Front Pressure";
CM_ SG_ 1328 TPV_RL "Tire Left Rear Pressure Validity";
CM_ SG_ 1328 TPV_RR "Tire Right Rear Pressure Validity";
CM_ SG_ 1328 TPV_FL "Tire Left Front Pressure Validity";
CM_ SG_ 1328 TPV_FR "Tire Right Front Pressure Validity";
CM_ SG_ 1328 TPS_RL "Tire Left Rear Pressure Status";
CM_ SG_ 1328 TPS_RR "Tire Right Rear Pressure Status";
CM_ SG_ 1328 TPS_FL "Tire Left Front Pressure Status";
CM_ SG_ 1328 TPS_FR "Tire Right Front Pressure Status";
CM_ SG_ 1298 OCV "Open Circuit Voltage";
CM_ SG_ 1298 Norminal_Capacity "Nominal Capacity of Battery";
CM_ SG_ 1298 FSOH "SOH valid";
CM_ SG_ 1298 FSOC "SOC valid";
CM_ SG_ 1297 InteriorTailLampCmd "Interior Tail Lamp Command";
CM_ SG_ 1297 RearDefoggerINDCmd "Rear Defogger Indicator Command (On during ISG Mode)";
CM_ SG_ 1297 BrakeLampFailSts "Brake Lamp Fail Status";
CM_ SG_ 1297 TailgateUnlatchSts "Tailgate Latch Unlock Status";
CM_ SG_ 1297 RearDoorLockUnSts "Rear Door Lock Unlock Status";
CM_ SG_ 1297 AutoPanelDimCmd_P "Auto Panel Dimming Command";
CM_ SG_ 1297 PsngrDoorLockUnSts "Passenger Door Lock Unlock Status";
CM_ SG_ 1297 RearLHSeatBeltSts "Rear Left Seat Belt Indicator Request";
CM_ SG_ 1297 RearCntSeatBeltSts "Rear Center Seat Belt Indicator Request";
CM_ SG_ 1297 RearRHSeatBeltSts "Rear Right Seat Belt Indicator Request";
CM_ SG_ 1297 PsgnrSeatBeltSts "Passenger Seat Belt Indicator Request";
CM_ SG_ 1297 DrivDoorAjarSts4P "Driver Door Ajar Status";
CM_ SG_ 1297 DRLSts "Daytime Running Light Status";
CM_ SG_ 1297 RearDefoggerActSts "Rear Defogger Activation Status";
CM_ SG_ 1297 HeadLightOnOff4P "Head Light On Off Status";
CM_ SG_ 1297 FrontWiperMotorSts4P "Front Wiper Motor Status";
CM_ SG_ 1297 DrivDoorLockUnSts "Driver Door Lock Unlock Status";
CM_ SG_ 1297 HoodAjarSts4p "Hood Open Status";
CM_ SG_ 1297 DrivSeatBeltSts "Driver Seat Belt Indicator Request";
CM_ SG_ 1296 SOH "State of Health";
CM_ SG_ 1296 U_Batt "Battery Voltage";
CM_ SG_ 1296 T_Batt "Battery Temperature";
CM_ SG_ 1296 SOC "State of Charge";
CM_ SG_ 1296 BS_Invalid "BSC invalid flag";
CM_ SG_ 1296 I_range "Battery current range";
CM_ SG_ 1296 I_Batt "Battery Current";
CM_ SG_ 272 ST_REQ "Engine Stert Request    ";
CM_ SG_ 1585 VCU_Calibration_631h_Signal "EMS Calibration Signal";
CM_ SG_ 1584 VCU_Calibration_630h_Signal "EMS Calibration Signal";
CM_ BO_ 1666 "This is the messages of calibration for BCM";
CM_ SG_ 1666 BCM_CAL_RESP "This is only for Immobilizer system between BCM and EMS. ";
CM_ BO_ 1665 "This is the messages of calibration for BCM";
CM_ SG_ 1665 BCM_CAL_REQ "This is only for Immobilizer system between BCM and EMS. ";
CM_ SG_ 1746 TPMS_CAL_RESP "TPMS Calibration Response";
CM_ SG_ 1682 TPMS_CAL_REQ "TPMS Calibration Request";
CM_ SG_ 817 GIER_ROH "raw signal yaw-rate compecsation/filtering";
CM_ SG_ 817 LONG_ACCEL "longitudinal acceleration";
CM_ SG_ 817 PS_MEANVAL "average of pressure sensors";
CM_ SG_ 817 LAT_ACCEL "Lateral acceleration speed (ESP Only)";
CM_ SG_ 522 Checksum_20Ah "Checksum";
CM_ SG_ 522 Counter_20Ah "Message Counter";
CM_ SG_ 522 ACC_Engine_Torque_Value "Indicated torque command for ACC";
CM_ SG_ 522 ACC_Engine_Torque_Request "Request ACC torque command";
CM_ SG_ 522 HSA_DEF_FLG "Hill Start Assist Defective Flag";
CM_ SG_ 522 HSA_CTR_FLAG "Hill Start Assist Control Flag";
CM_ SG_ 561 CheckSum "Check Sum";
CM_ SG_ 561 MsgCount "Message Counter";
CM_ SG_ 561 SAS_CAL "SAS calibration flag";
CM_ SG_ 561 SAS_OK "SAS angle value OK flag";
CM_ SG_ 561 SAS_Speed "Steering Wheel Rotation Speed";
CM_ SG_ 561 SAS_Angle "Steering Wheel Angle ('-' is Left,  '+' is Right)";
CM_ SG_ 2024 DGN_RESP_VCU "diagnosis response";
CM_ SG_ 2016 DGN_REQ_VCU "CAN scan EMS diagnosis request";
CM_ SG_ 261 ECU_Immo "Immobilizer release req/ack";
CM_ SG_ 772 Counter_304h "Message Counter";
CM_ SG_ 772 Checksum_304h "Checksum";
CM_ SG_ 772 Rheo_Stat_Level "Rheo Stat illumi Level (1~20)";
CM_ SG_ 772 Airbag_WL_Fb "Airbag Warning Lamp";
CM_ SG_ 772 IG_S "ignition status";
CM_ SG_ 772 KM16 "odometer reading";
CM_ SG_ 771 Checksum_303h "Checksum";
CM_ SG_ 771 V_ANZ "Vehicle speed as it is displayed in the speedometer";
CM_ SG_ 771 V_MPH "cluster speedometer unit mph instead of km/h";
CM_ SG_ 771 T_Outside "Outside Temperature";
CM_ SG_ 771 Counter_303h "Message Counter";
CM_ SG_ 771 Speed_Combi "vehicle speed by combi";
CM_ SG_ 771 TANK_FS_KOMBI "tank level";
CM_ SG_ 771 T_OutsideInitSts "Outside Temperature Value Initialization Flag";
CM_ SG_ 529 Checksum_211h "Checksum";
CM_ SG_ 529 Counter_211h "Message Counter";
CM_ SG_ 529 SMC_E_S "SMC engine state";
CM_ SG_ 529 VCU_transPmotorparkReq "transmission parking request";
CM_ SG_ 529 ACC_ACT "cruise control activated ";
CM_ SG_ 529 M_FEV "driver's substitute torque demand";
CM_ SG_ 529 M_ESP_E "enable ESP torque request";
CM_ SG_ 529 PW_Virtual_Flag "pedal real, virtual flag value";
CM_ SG_ 529 SPDLIM_Ready "speed limiter ready";
CM_ SG_ 529 CAN_Engine_ACC_failure "Acc Engine fail (ACC disable request)";
CM_ SG_ 529 CAN_Driver_Accel_Override "Driver accel pedal override";
CM_ SG_ 529 SPDLIM_Overspeed "speed limiter : overspeed warning";
CM_ SG_ 529 SPDLIM_Override "speed limiter : override condition(kick down condition)";
CM_ SG_ 529 SPDLIM_ACT "speed limiter activated ";
CM_ SG_ 529 ACC_Ready "cruise control ready";
CM_ SG_ 529 PW_ERR "failure pedal position sensor";
CM_ SG_ 529 PW "pedal value";
CM_ SG_ 816 EST_REF_VELOCITY "estimate reference velocity";
CM_ SG_ 816 Counter_330h "Message Counter";
CM_ SG_ 816 Checksum_330h "Checksum";
CM_ SG_ 816 CPL_TQ_LIMIT "CPL cardan shaft torque limit";
CM_ SG_ 816 RQ_Clutch_OP "CPL fast opening of cardan shaft clutch";
CM_ SG_ 816 EBS_STATUS "EBS Activity status";
CM_ SG_ 768 Counter_300h "Rolling Counter";
CM_ SG_ 768 Checksum_300h "Checksum";
CM_ SG_ 768 MMOTSR_PA "MMOTSR parity bit";
CM_ SG_ 768 MMOTSE_PA "MMOTSE parity bit";
CM_ SG_ 768 BZ300h "message counter";
CM_ SG_ 768 AMR_AKT_ESP "drive torque regulation active";
CM_ SG_ 768 M_ESP "request engine torque";
CM_ SG_ 768 TOGGLE "toggle bit";
CM_ SG_ 768 SFB_PA "driver braking parity";
CM_ SG_ 768 SFB "driver braking";
CM_ SG_ 768 MTGL_ESP "engine torque request toggle bit";
CM_ SG_ 768 MPAR_ESP "engine torque request parity";
CM_ SG_ 768 MMOTSR "required reduction of engine torque ASR";
CM_ SG_ 768 MMOTSE "required increase of engine torque MSR";
CM_ SG_ 768 MMIN_ESP "engine torque request min.mode";
CM_ SG_ 768 MMAX_ESP "engine torque request max.mode";
CM_ SG_ 520 TM_AUS "cruise control mode off";
CM_ SG_ 520 SZS "system status";
CM_ SG_ 520 MBRE_ESP "applied brake torque";
CM_ SG_ 520 DRTGHR "direction of wheel rotation, rear right";
CM_ SG_ 520 DRTGHL "direction of wheel rotation, rear left";
CM_ SG_ 520 DHR "wheel speed, rear right";
CM_ SG_ 520 DHL "wheel speed, rear left";
CM_ SG_ 520 BRE_AKT_ART "ART brake intervention active";
CM_ SG_ 520 ANFN "ESP request:neutral";
CM_ SG_ 512 ESP_OFF_KL "ESP OFF Lamp";
CM_ SG_ 512 ESP_BL "Brake light activation for automatic braking";
CM_ SG_ 512 TM_DL "wheel speed, left for cruise control";
CM_ SG_ 512 ESP_KL "ESP indicator lamp  ";
CM_ SG_ 512 EBD_KL "EBD faulty indicator lamp";
CM_ SG_ 512 DVR "wheel speed, front right";
CM_ SG_ 512 DVL "wheel speed, front left";
CM_ SG_ 512 DRTGVL "direction of wheel rotation, front left";
CM_ SG_ 512 DRTGVR "direction of wheel rotation, front right";
CM_ SG_ 512 DRTGTM "direction of wheel rotation, left for cruise control";
CM_ SG_ 512 BZ200h "message counter";
CM_ SG_ 512 BLS_PA "BLS parity bit";
CM_ SG_ 512 BLS "stop lamp switch";
CM_ SG_ 512 ESS_INFO "Emegency Stop Signal for emergency braking";
CM_ SG_ 512 ABS_KL "ABS faulty indicator lamp";
BA_DEF_ SG_  "CmxSigDefaultRaw" HEX 0 2147483647;
BA_DEF_ SG_  "GW_TimeoutValue" INT 0 65535;
BA_DEF_ SG_  "NmNetworkRequestHoldingTime" INT 0 65535;
BA_DEF_ SG_  "GwSigLatencyTime" INT 0 65535;
BA_DEF_ SG_  "GwSigMissingSourceType" ENUM  "Undef","OldValue","DefaultValue","InitialValue";
BA_DEF_ SG_  "UndefinedValueRangeBegin" INT 0 0;
BA_DEF_ SG_  "SignalCategory" HEX 10 15;
BA_DEF_ SG_  "GenSigEnvVarType" ENUM  "int","float","undef";
BA_DEF_ SG_  "GenSigStartValue" INT 0 0;
BA_DEF_ SG_  "GenSigSendType" ENUM  "Cyclic","OnWrite","OnWriteWithRepetition","OnChange","OnChangeWithRepetition","IfActive","IfActiveWithRepetition","NoSigSendType";
BA_DEF_ BO_  "DiagState" ENUM  "No","Yes";
BA_DEF_ BO_  "DiagRequest" ENUM  "No","Yes";
BA_DEF_ BO_  "DiagResponse" ENUM  "No","Yes";
BA_DEF_ BO_  "GenMsgFastOnStart" INT 0 0;
BA_DEF_ BO_  "TpTxIndex" INT 0 255;
BA_DEF_ BO_  "NmMessage" ENUM  "No","Yes";
BA_DEF_ BO_  "GenMsgILSupport" ENUM  "No","Yes";
BA_DEF_ BO_  "GenMsgNrOfRepetition" INT 0 3;
BA_DEF_ BO_  "GenMsgDelayTime" INT 3 20;
BA_DEF_ BO_  "GenMsgCycleTimeFast" INT 0 500;
BA_DEF_ BO_  "GenMsgSendType" ENUM  "Cyclic","not_used","not_used","not_used","not_used","not_used","not_used","not_used","NoMsgSendType";
BA_DEF_ BO_  "GenMsgCycleTime" INT 0 2000;
BA_DEF_ BU_  "NodeLayerModules" STRING ;
BA_DEF_ BU_  "GenNodSleepTime" INT 1375 1650;
BA_DEF_ BU_  "NmNode" ENUM  "No","Yes";
BA_DEF_ BU_  "NmCAN" INT 1 2;
BA_DEF_ BU_  "ILUsed" ENUM  "No","Yes";
BA_DEF_ BU_  "NmStationAddress" HEX 0 255;
BA_DEF_ BU_  "PCANShutDownTime" INT 0 300;
BA_DEF_  "VersionNumber" INT 0 9999;
BA_DEF_  "VersionWeek" INT 1 53;
BA_DEF_  "VersionYear" INT 0 9999;
BA_DEF_  "VersionMonth" INT 1 12;
BA_DEF_  "VersionDay" INT 1 31;
BA_DEF_  "BusType" STRING ;
BA_DEF_  "GenNWMTalkNM" STRING ;
BA_DEF_  "GenNWMSleepTime" INT 1375 1650;
BA_DEF_  "GenNWMGotoMode_BusSleep" STRING ;
BA_DEF_  "GenNWMGotoMode_Awake" STRING ;
BA_DEF_  "GenNWMApCanWakeUp" STRING ;
BA_DEF_  "GenNWMApCanSleep" STRING ;
BA_DEF_  "GenNWMApCanOn" STRING ;
BA_DEF_  "GenNWMApCanOff" STRING ;
BA_DEF_  "GenNWMApCanNormal" STRING ;
BA_DEF_  "GenNWMApBusSleep" STRING ;
BA_DEF_  "GenEnvVarPrefix" STRING ;
BA_DEF_  "GenEnvVarEndingSnd" STRING ;
BA_DEF_  "GenEnvVarEndingDsp" STRING ;
BA_DEF_  "NmType" STRING ;
BA_DEF_  "NmBaseAddress" HEX 0 2047;
BA_DEF_  "NmMessageCount" INT 0 128;
BA_DEF_  "Manufacturer" STRING ;
BA_DEF_  "Baudrate" INT 50000 500000;
BA_DEF_  "SamplePointMin" INT 55 85;
BA_DEF_  "SamplePointMax" INT 50 85;
BA_DEF_  "SyncJumpWidthMin" INT 1 4;
BA_DEF_  "SyncJumpWidthMax" INT 1 8;
BA_DEF_REL_ BU_SG_REL_  "GenSigTimeoutTime" INT 30 5000;
BA_DEF_DEF_  "CmxSigDefaultRaw" 0;
BA_DEF_DEF_  "GW_TimeoutValue" 0;
BA_DEF_DEF_  "NmNetworkRequestHoldingTime" 0;
BA_DEF_DEF_  "GwSigLatencyTime" 40;
BA_DEF_DEF_  "GwSigMissingSourceType" "Undef";
BA_DEF_DEF_  "UndefinedValueRangeBegin" 0;
BA_DEF_DEF_  "SignalCategory" 10;
BA_DEF_DEF_  "GenSigEnvVarType" "undef";
BA_DEF_DEF_  "GenSigStartValue" 0;
BA_DEF_DEF_  "GenSigSendType" "NoSigSendType";
BA_DEF_DEF_  "DiagState" "No";
BA_DEF_DEF_  "DiagRequest" "No";
BA_DEF_DEF_  "DiagResponse" "No";
BA_DEF_DEF_  "GenMsgFastOnStart" 0;
BA_DEF_DEF_  "TpTxIndex" 0;
BA_DEF_DEF_  "NmMessage" "No";
BA_DEF_DEF_  "GenMsgILSupport" "Yes";
BA_DEF_DEF_  "GenMsgNrOfRepetition" 0;
BA_DEF_DEF_  "GenMsgDelayTime" 20;
BA_DEF_DEF_  "GenMsgCycleTimeFast" 0;
BA_DEF_DEF_  "GenMsgSendType" "NoMsgSendType";
BA_DEF_DEF_  "GenMsgCycleTime" 0;
BA_DEF_DEF_REL_ "GenSigTimeoutTime" 1400;
BA_DEF_DEF_  "NodeLayerModules" "oseknm01.dll";
BA_DEF_DEF_  "GenNodSleepTime" 1500;
BA_DEF_DEF_  "NmNode" "Yes";
BA_DEF_DEF_  "NmCAN" 1;
BA_DEF_DEF_  "ILUsed" "Yes";
BA_DEF_DEF_  "NmStationAddress" 0;
BA_DEF_DEF_  "PCANShutDownTime" 0;
BA_DEF_DEF_  "VersionNumber" 0;
BA_DEF_DEF_  "VersionWeek" 1;
BA_DEF_DEF_  "VersionYear" 2006;
BA_DEF_DEF_  "VersionMonth" 1;
BA_DEF_DEF_  "VersionDay" 1;
BA_DEF_DEF_  "BusType" "CAN";
BA_DEF_DEF_  "GenNWMTalkNM" "TalkNM()";
BA_DEF_DEF_  "GenNWMSleepTime" 1500;
BA_DEF_DEF_  "GenNWMGotoMode_BusSleep" "GotoMode_BusSleep()";
BA_DEF_DEF_  "GenNWMGotoMode_Awake" "GotoMode_Awake()";
BA_DEF_DEF_  "GenNWMApCanWakeUp" "ApplCanWakeUp()";
BA_DEF_DEF_  "GenNWMApCanSleep" "ApplNmCanSleep()";
BA_DEF_DEF_  "GenNWMApCanOn" "ApplCanOnline()";
BA_DEF_DEF_  "GenNWMApCanOff" "ApplCanOffline()";
BA_DEF_DEF_  "GenNWMApCanNormal" "ApplNmCanNormal()";
BA_DEF_DEF_  "GenNWMApBusSleep" "ApplNmCanBusSleep()";
BA_DEF_DEF_  "GenEnvVarPrefix" "Env";
BA_DEF_DEF_  "GenEnvVarEndingSnd" "_";
BA_DEF_DEF_  "GenEnvVarEndingDsp" "Dsp_";
BA_DEF_DEF_  "NmType" "Vector";
BA_DEF_DEF_  "NmBaseAddress" 1024;
BA_DEF_DEF_  "NmMessageCount" 128;
BA_DEF_DEF_  "Manufacturer" "SYMC";
BA_DEF_DEF_  "Baudrate" 100000;
BA_DEF_DEF_  "SamplePointMin" 75;
BA_DEF_DEF_  "SamplePointMax" 82;
BA_DEF_DEF_  "SyncJumpWidthMin" 2;
BA_DEF_DEF_  "SyncJumpWidthMax" 3;
BA_ "VersionNumber" 110;
BA_ "VersionWeek" 19;
BA_ "VersionYear" 2019;
BA_ "VersionMonth" 5;
BA_ "VersionDay" 10;
BA_ "NmType" "";
BA_ "Baudrate" 500000;
BA_ "NmNode" BU_ EHVC 0;
BA_ "NmNode" BU_ VESS 0;
BA_ "NmNode" BU_ SBWS 0;
BA_ "NmNode" BU_ EGP 0;
BA_ "NmNode" BU_ OBC 0;
BA_ "NmNode" BU_ LDC 0;
BA_ "NmNode" BU_ MCU 0;
BA_ "NmNode" BU_ BMS 0;
BA_ "NmStationAddress" BU_ VCU 20;
BA_ "NmStationAddress" BU_ CGW 72;
BA_ "NmNode" BU_ ECALL 0;
BA_ "NmNode" BU_ HVAC 0;
BA_ "NmNode" BU_ ACU 0;
BA_ "NmNode" BU_ SKM 0;
BA_ "PCANShutDownTime" BU_ EBU 300;
BA_ "NmNode" BU_ EBU 0;
BA_ "NmNode" BU_ TESTER 0;
BA_ "NmNode" BU_ BCM 0;
BA_ "GenMsgNrOfRepetition" BO_ 944 1;
BA_ "GenMsgDelayTime" BO_ 944 5;
BA_ "GenMsgCycleTimeFast" BO_ 944 40;
BA_ "GenMsgSendType" BO_ 944 0;
BA_ "GenMsgCycleTime" BO_ 944 200;
BA_ "GenMsgDelayTime" BO_ 1732 5;
BA_ "GenMsgDelayTime" BO_ 1668 5;
BA_ "GenMsgDelayTime" BO_ 807 5;
BA_ "GenMsgSendType" BO_ 807 0;
BA_ "GenMsgCycleTime" BO_ 807 100;
BA_ "GenMsgSendType" BO_ 1393 0;
BA_ "GenMsgCycleTime" BO_ 1393 500;
BA_ "DiagResponse" BO_ 1913 1;
BA_ "GenMsgILSupport" BO_ 1913 0;
BA_ "GenMsgDelayTime" BO_ 1913 5;
BA_ "GenMsgDelayTime" BO_ 941 5;
BA_ "GenMsgSendType" BO_ 941 0;
BA_ "GenMsgCycleTime" BO_ 941 100;
BA_ "GenMsgDelayTime" BO_ 851 5;
BA_ "GenMsgSendType" BO_ 851 0;
BA_ "GenMsgCycleTime" BO_ 851 100;
BA_ "GenMsgDelayTime" BO_ 882 5;
BA_ "GenMsgSendType" BO_ 882 0;
BA_ "GenMsgCycleTime" BO_ 882 100;
BA_ "GenMsgSendType" BO_ 1394 0;
BA_ "GenMsgCycleTime" BO_ 1394 500;
BA_ "DiagRequest" BO_ 1905 1;
BA_ "GenMsgILSupport" BO_ 1905 0;
BA_ "GenMsgDelayTime" BO_ 1905 5;
BA_ "GenMsgDelayTime" BO_ 854 5;
BA_ "GenMsgSendType" BO_ 854 0;
BA_ "GenMsgCycleTime" BO_ 854 100;
BA_ "GenMsgDelayTime" BO_ 492 5;
BA_ "GenMsgSendType" BO_ 492 0;
BA_ "GenMsgCycleTime" BO_ 492 100;
BA_ "DiagRequest" BO_ 1894 1;
BA_ "GenMsgDelayTime" BO_ 1894 5;
BA_ "DiagRequest" BO_ 1893 1;
BA_ "GenMsgDelayTime" BO_ 1893 5;
BA_ "DiagRequest" BO_ 1892 1;
BA_ "GenMsgDelayTime" BO_ 1892 5;
BA_ "DiagRequest" BO_ 1891 1;
BA_ "GenMsgDelayTime" BO_ 1891 5;
BA_ "DiagRequest" BO_ 1890 1;
BA_ "GenMsgDelayTime" BO_ 1890 5;
BA_ "DiagRequest" BO_ 1889 1;
BA_ "GenMsgDelayTime" BO_ 1889 5;
BA_ "DiagRequest" BO_ 1857 1;
BA_ "GenMsgDelayTime" BO_ 1857 5;
BA_ "GenMsgDelayTime" BO_ 491 5;
BA_ "GenMsgSendType" BO_ 491 0;
BA_ "GenMsgCycleTime" BO_ 491 10;
BA_ "GenMsgDelayTime" BO_ 519 5;
BA_ "GenMsgSendType" BO_ 519 0;
BA_ "GenMsgCycleTime" BO_ 519 10;
BA_ "GenMsgSendType" BO_ 853 0;
BA_ "GenMsgCycleTime" BO_ 853 100;
BA_ "GenMsgDelayTime" BO_ 831 5;
BA_ "GenMsgSendType" BO_ 831 0;
BA_ "GenMsgCycleTime" BO_ 831 100;
BA_ "GenMsgDelayTime" BO_ 488 5;
BA_ "GenMsgSendType" BO_ 488 0;
BA_ "GenMsgCycleTime" BO_ 488 20;
BA_ "GenMsgDelayTime" BO_ 487 5;
BA_ "GenMsgSendType" BO_ 487 0;
BA_ "GenMsgCycleTime" BO_ 487 10;
BA_ "GenMsgDelayTime" BO_ 929 5;
BA_ "GenMsgSendType" BO_ 929 0;
BA_ "GenMsgCycleTime" BO_ 929 100;
BA_ "GenMsgDelayTime" BO_ 928 5;
BA_ "GenMsgSendType" BO_ 928 0;
BA_ "GenMsgCycleTime" BO_ 928 100;
BA_ "GenMsgDelayTime" BO_ 803 5;
BA_ "GenMsgSendType" BO_ 803 0;
BA_ "GenMsgCycleTime" BO_ 803 100;
BA_ "GenMsgDelayTime" BO_ 850 5;
BA_ "GenMsgSendType" BO_ 850 0;
BA_ "GenMsgCycleTime" BO_ 850 100;
BA_ "GenMsgDelayTime" BO_ 849 5;
BA_ "GenMsgSendType" BO_ 849 0;
BA_ "GenMsgCycleTime" BO_ 849 100;
BA_ "GenMsgDelayTime" BO_ 830 5;
BA_ "GenMsgSendType" BO_ 830 0;
BA_ "GenMsgCycleTime" BO_ 830 100;
BA_ "GenMsgDelayTime" BO_ 940 5;
BA_ "GenMsgSendType" BO_ 940 0;
BA_ "GenMsgCycleTime" BO_ 940 100;
BA_ "GenMsgDelayTime" BO_ 581 5;
BA_ "GenMsgSendType" BO_ 581 0;
BA_ "GenMsgCycleTime" BO_ 581 20;
BA_ "GenMsgDelayTime" BO_ 467 5;
BA_ "GenMsgSendType" BO_ 467 0;
BA_ "GenMsgCycleTime" BO_ 467 10;
BA_ "GenMsgDelayTime" BO_ 466 5;
BA_ "GenMsgSendType" BO_ 466 0;
BA_ "GenMsgCycleTime" BO_ 466 20;
BA_ "GenMsgDelayTime" BO_ 465 5;
BA_ "GenMsgSendType" BO_ 465 0;
BA_ "GenMsgCycleTime" BO_ 465 100;
BA_ "GenMsgDelayTime" BO_ 584 5;
BA_ "GenMsgSendType" BO_ 584 0;
BA_ "GenMsgCycleTime" BO_ 584 20;
BA_ "GenMsgNrOfRepetition" BO_ 464 1;
BA_ "GenMsgCycleTimeFast" BO_ 464 40;
BA_ "GenMsgNrOfRepetition" BO_ 458 1;
BA_ "GenMsgCycleTimeFast" BO_ 458 40;
BA_ "GenMsgCycleTime" BO_ 458 1000;
BA_ "GenMsgNrOfRepetition" BO_ 450 1;
BA_ "GenMsgCycleTimeFast" BO_ 450 40;
BA_ "GenMsgCycleTime" BO_ 450 1000;
BA_ "DiagResponse" BO_ 1981 1;
BA_ "TpTxIndex" BO_ 1981 106;
BA_ "GenMsgILSupport" BO_ 1981 0;
BA_ "GenMsgDelayTime" BO_ 1981 5;
BA_ "DiagRequest" BO_ 1973 1;
BA_ "TpTxIndex" BO_ 1973 106;
BA_ "GenMsgILSupport" BO_ 1973 0;
BA_ "GenMsgDelayTime" BO_ 1973 5;
BA_ "GenMsgDelayTime" BO_ 1597 5;
BA_ "GenMsgDelayTime" BO_ 304 5;
BA_ "GenMsgSendType" BO_ 304 0;
BA_ "GenMsgCycleTime" BO_ 304 10;
BA_ "GenMsgDelayTime" BO_ 320 5;
BA_ "GenMsgSendType" BO_ 320 0;
BA_ "GenMsgCycleTime" BO_ 320 10;
BA_ "GenMsgSendType" BO_ 1416 0;
BA_ "GenMsgCycleTime" BO_ 1416 200;
BA_ "GenMsgDelayTime" BO_ 1352 5;
BA_ "GenMsgSendType" BO_ 1352 0;
BA_ "GenMsgCycleTime" BO_ 1352 500;
BA_ "DiagResponse" BO_ 1902 1;
BA_ "GenMsgDelayTime" BO_ 1902 5;
BA_ "DiagResponse" BO_ 1901 1;
BA_ "GenMsgDelayTime" BO_ 1901 5;
BA_ "DiagResponse" BO_ 1900 1;
BA_ "GenMsgDelayTime" BO_ 1900 5;
BA_ "DiagResponse" BO_ 1899 1;
BA_ "GenMsgDelayTime" BO_ 1899 5;
BA_ "DiagResponse" BO_ 1898 1;
BA_ "GenMsgDelayTime" BO_ 1898 5;
BA_ "GenMsgDelayTime" BO_ 352 5;
BA_ "GenMsgSendType" BO_ 352 0;
BA_ "GenMsgCycleTime" BO_ 352 20;
BA_ "GenMsgSendType" BO_ 1381 0;
BA_ "GenMsgCycleTime" BO_ 1381 500;
BA_ "GenMsgDelayTime" BO_ 1382 5;
BA_ "GenMsgSendType" BO_ 1382 0;
BA_ "GenMsgCycleTime" BO_ 1382 500;
BA_ "GenMsgDelayTime" BO_ 1587 5;
BA_ "GenMsgDelayTime" BO_ 1588 5;
BA_ "GenMsgDelayTime" BO_ 1586 5;
BA_ "GenMsgNrOfRepetition" BO_ 353 3;
BA_ "GenMsgCycleTimeFast" BO_ 353 40;
BA_ "GenMsgSendType" BO_ 353 0;
BA_ "GenMsgCycleTime" BO_ 353 200;
BA_ "DiagResponse" BO_ 1897 1;
BA_ "GenMsgDelayTime" BO_ 1897 5;
BA_ "DiagResponse" BO_ 1865 1;
BA_ "GenMsgDelayTime" BO_ 1865 5;
BA_ "GenMsgDelayTime" BO_ 601 5;
BA_ "GenMsgSendType" BO_ 601 0;
BA_ "GenMsgCycleTime" BO_ 601 20;
BA_ "GenMsgDelayTime" BO_ 277 5;
BA_ "GenMsgSendType" BO_ 864 0;
BA_ "GenMsgCycleTime" BO_ 864 20;
BA_ "GenMsgSendType" BO_ 832 0;
BA_ "GenMsgCycleTime" BO_ 832 50;
BA_ "GenMsgSendType" BO_ 563 0;
BA_ "GenMsgCycleTime" BO_ 563 20;
BA_ "GenMsgCycleTimeFast" BO_ 1378 100;
BA_ "GenMsgSendType" BO_ 1378 0;
BA_ "GenMsgCycleTime" BO_ 1378 500;
BA_ "GenMsgCycleTimeFast" BO_ 1377 100;
BA_ "GenMsgSendType" BO_ 1377 0;
BA_ "GenMsgCycleTime" BO_ 1377 500;
BA_ "NmMessage" BO_ 1044 1;
BA_ "GenMsgILSupport" BO_ 1044 0;
BA_ "NmMessage" BO_ 1096 1;
BA_ "GenMsgILSupport" BO_ 1096 0;
BA_ "DiagResponse" BO_ 1976 1;
BA_ "GenMsgILSupport" BO_ 1976 0;
BA_ "GenMsgDelayTime" BO_ 1976 5;
BA_ "DiagRequest" BO_ 1968 1;
BA_ "GenMsgILSupport" BO_ 1968 0;
BA_ "GenMsgDelayTime" BO_ 1968 5;
BA_ "DiagResponse" BO_ 1803 1;
BA_ "GenMsgILSupport" BO_ 1803 0;
BA_ "GenMsgDelayTime" BO_ 1803 5;
BA_ "GenMsgDelayTime" BO_ 481 5;
BA_ "GenMsgSendType" BO_ 481 0;
BA_ "GenMsgCycleTime" BO_ 481 10;
BA_ "GenMsgDelayTime" BO_ 937 5;
BA_ "GenMsgSendType" BO_ 937 0;
BA_ "GenMsgCycleTime" BO_ 937 100;
BA_ "GenMsgDelayTime" BO_ 936 5;
BA_ "GenMsgSendType" BO_ 936 0;
BA_ "GenMsgCycleTime" BO_ 936 100;
BA_ "GenMsgFastOnStart" BO_ 336 40;
BA_ "GenMsgNrOfRepetition" BO_ 336 3;
BA_ "GenMsgCycleTimeFast" BO_ 336 40;
BA_ "DiagRequest" BO_ 1795 1;
BA_ "GenMsgILSupport" BO_ 1795 0;
BA_ "GenMsgDelayTime" BO_ 1795 5;
BA_ "GenMsgDelayTime" BO_ 1356 5;
BA_ "GenMsgSendType" BO_ 1356 0;
BA_ "GenMsgCycleTime" BO_ 1356 500;
BA_ "GenMsgDelayTime" BO_ 1303 5;
BA_ "GenMsgSendType" BO_ 1303 0;
BA_ "GenMsgCycleTime" BO_ 1303 500;
BA_ "GenMsgDelayTime" BO_ 1300 5;
BA_ "GenMsgSendType" BO_ 1300 0;
BA_ "GenMsgCycleTime" BO_ 1300 500;
BA_ "GenMsgDelayTime" BO_ 1299 5;
BA_ "GenMsgSendType" BO_ 1299 0;
BA_ "GenMsgCycleTime" BO_ 1299 500;
BA_ "GenMsgDelayTime" BO_ 1345 5;
BA_ "GenMsgSendType" BO_ 1345 0;
BA_ "GenMsgCycleTime" BO_ 1345 500;
BA_ "GenMsgDelayTime" BO_ 821 5;
BA_ "GenMsgSendType" BO_ 821 0;
BA_ "GenMsgCycleTime" BO_ 821 100;
BA_ "GenMsgNrOfRepetition" BO_ 309 1;
BA_ "GenMsgDelayTime" BO_ 309 5;
BA_ "GenMsgDelayTime" BO_ 565 5;
BA_ "GenMsgSendType" BO_ 565 0;
BA_ "GenMsgCycleTime" BO_ 565 100;
BA_ "GenMsgILSupport" BO_ 2012 0;
BA_ "GenMsgDelayTime" BO_ 2012 5;
BA_ "GenMsgILSupport" BO_ 2004 0;
BA_ "GenMsgDelayTime" BO_ 2004 5;
BA_ "GenMsgILSupport" BO_ 2041 0;
BA_ "GenMsgDelayTime" BO_ 2041 5;
BA_ "GenMsgILSupport" BO_ 2033 0;
BA_ "GenMsgDelayTime" BO_ 2033 5;
BA_ "DiagResponse" BO_ 2011 1;
BA_ "GenMsgILSupport" BO_ 2011 0;
BA_ "GenMsgDelayTime" BO_ 2011 5;
BA_ "DiagRequest" BO_ 2003 1;
BA_ "GenMsgILSupport" BO_ 2003 0;
BA_ "GenMsgDelayTime" BO_ 2003 5;
BA_ "GenMsgDelayTime" BO_ 1289 5;
BA_ "GenMsgSendType" BO_ 1289 0;
BA_ "GenMsgCycleTime" BO_ 1289 500;
BA_ "GenMsgSendType" BO_ 1328 0;
BA_ "GenMsgCycleTime" BO_ 1328 1000;
BA_ "GenMsgDelayTime" BO_ 1379 5;
BA_ "GenMsgSendType" BO_ 1379 0;
BA_ "GenMsgCycleTime" BO_ 1379 500;
BA_ "GenMsgDelayTime" BO_ 1380 5;
BA_ "GenMsgSendType" BO_ 1380 0;
BA_ "GenMsgCycleTime" BO_ 1380 500;
BA_ "GenMsgDelayTime" BO_ 1298 5;
BA_ "GenMsgSendType" BO_ 1298 0;
BA_ "GenMsgCycleTime" BO_ 1298 100;
BA_ "GenMsgDelayTime" BO_ 1297 5;
BA_ "GenMsgSendType" BO_ 1297 0;
BA_ "GenMsgCycleTime" BO_ 1297 100;
BA_ "GenMsgDelayTime" BO_ 1296 5;
BA_ "GenMsgSendType" BO_ 1296 0;
BA_ "GenMsgCycleTime" BO_ 1296 100;
BA_ "DiagResponse" BO_ 1992 1;
BA_ "TpTxIndex" BO_ 1992 107;
BA_ "GenMsgILSupport" BO_ 1992 0;
BA_ "GenMsgDelayTime" BO_ 1992 5;
BA_ "DiagRequest" BO_ 1984 1;
BA_ "TpTxIndex" BO_ 1984 107;
BA_ "GenMsgILSupport" BO_ 1984 0;
BA_ "GenMsgDelayTime" BO_ 1984 5;
BA_ "DiagRequest" BO_ 1989 1;
BA_ "TpTxIndex" BO_ 1989 106;
BA_ "GenMsgILSupport" BO_ 1989 0;
BA_ "GenMsgDelayTime" BO_ 1989 5;
BA_ "DiagResponse" BO_ 1997 1;
BA_ "TpTxIndex" BO_ 1997 106;
BA_ "GenMsgILSupport" BO_ 1997 0;
BA_ "GenMsgDelayTime" BO_ 1997 5;
BA_ "GenMsgDelayTime" BO_ 272 5;
BA_ "GenMsgSendType" BO_ 272 0;
BA_ "GenMsgCycleTime" BO_ 272 20;
BA_ "GenMsgDelayTime" BO_ 1585 5;
BA_ "GenMsgDelayTime" BO_ 1584 5;
BA_ "GenMsgDelayTime" BO_ 1666 5;
BA_ "GenMsgDelayTime" BO_ 1665 5;
BA_ "DiagResponse" BO_ 1801 1;
BA_ "TpTxIndex" BO_ 1801 101;
BA_ "GenMsgDelayTime" BO_ 1801 5;
BA_ "DiagRequest" BO_ 1793 1;
BA_ "TpTxIndex" BO_ 1793 101;
BA_ "GenMsgDelayTime" BO_ 1793 5;
BA_ "GenMsgDelayTime" BO_ 1746 5;
BA_ "GenMsgDelayTime" BO_ 1682 5;
BA_ "GenMsgDelayTime" BO_ 817 5;
BA_ "GenMsgSendType" BO_ 817 0;
BA_ "GenMsgCycleTime" BO_ 817 20;
BA_ "GenMsgDelayTime" BO_ 522 5;
BA_ "GenMsgSendType" BO_ 522 0;
BA_ "GenMsgCycleTime" BO_ 522 10;
BA_ "GenMsgDelayTime" BO_ 561 5;
BA_ "GenMsgSendType" BO_ 561 0;
BA_ "GenMsgCycleTime" BO_ 561 20;
BA_ "DiagResponse" BO_ 2024 1;
BA_ "TpTxIndex" BO_ 2024 104;
BA_ "GenMsgILSupport" BO_ 2024 0;
BA_ "GenMsgDelayTime" BO_ 2024 5;
BA_ "DiagRequest" BO_ 2016 1;
BA_ "TpTxIndex" BO_ 2016 104;
BA_ "GenMsgILSupport" BO_ 2016 0;
BA_ "GenMsgDelayTime" BO_ 2016 5;
BA_ "GenMsgDelayTime" BO_ 261 5;
BA_ "GenMsgDelayTime" BO_ 2015 5;
BA_ "DiagState" BO_ 1792 1;
BA_ "GenMsgDelayTime" BO_ 1792 5;
BA_ "GenMsgDelayTime" BO_ 772 5;
BA_ "GenMsgSendType" BO_ 772 0;
BA_ "GenMsgCycleTime" BO_ 772 100;
BA_ "GenMsgDelayTime" BO_ 771 5;
BA_ "GenMsgSendType" BO_ 771 0;
BA_ "GenMsgCycleTime" BO_ 771 20;
BA_ "GenMsgDelayTime" BO_ 529 5;
BA_ "GenMsgSendType" BO_ 529 0;
BA_ "GenMsgCycleTime" BO_ 529 20;
BA_ "GenMsgDelayTime" BO_ 816 5;
BA_ "GenMsgSendType" BO_ 816 0;
BA_ "GenMsgCycleTime" BO_ 816 20;
BA_ "GenMsgDelayTime" BO_ 768 5;
BA_ "GenMsgSendType" BO_ 768 0;
BA_ "GenMsgCycleTime" BO_ 768 10;
BA_ "GenMsgDelayTime" BO_ 520 5;
BA_ "GenMsgSendType" BO_ 520 0;
BA_ "GenMsgCycleTime" BO_ 520 20;
BA_ "GenMsgDelayTime" BO_ 512 5;
BA_ "GenMsgSendType" BO_ 512 0;
BA_ "GenMsgCycleTime" BO_ 512 20;
BA_ "SignalCategory" SG_ 3221225472 IgnitionSts 12;
BA_ "CmxSigDefaultRaw" SG_ 3221225472 SafetyUnlockSetSts 1;
BA_ "GenSigSendType" SG_ 3221225472 SafetyUnlockSetSts 4;
BA_ "GenSigStartValue" SG_ 3221225472 ACC_RequiredAccel 1023;
BA_ "SignalCategory" SG_ 3221225472 ESCSetCmd 12;
BA_ "GenSigSendType" SG_ 3221225472 ESCSetCmd 4;
BA_ "SignalCategory" SG_ 3221225472 DGN_REQ_SAS 12;
BA_ "CmxSigDefaultRaw" SG_ 3221225472 ALT_FB 255;
BA_ "SignalCategory" SG_ 3221225472 ALT_FB 13;
BA_ "CmxSigDefaultRaw" SG_ 3221225472 NTURBINE 65535;
BA_ "SignalCategory" SG_ 3221225472 NTURBINE 13;
BA_ "CmxSigDefaultRaw" SG_ 3221225472 MABS_SW_ANFB 65535;
BA_ "SignalCategory" SG_ 3221225472 MABS_SW_ANFB 13;
BA_ "CmxSigDefaultRaw" SG_ 3221225472 VB 65535;
BA_ "SignalCategory" SG_ 3221225472 VB 13;
BA_ "CmxSigDefaultRaw" SG_ 3221225472 T_MOT 255;
BA_ "SignalCategory" SG_ 3221225472 T_MOT 13;
BA_ "CmxSigDefaultRaw" SG_ 944 HvacDisplayDefoggerSts 3;
BA_ "SignalCategory" SG_ 944 HvacDisplayDefoggerSts 13;
BA_ "CmxSigDefaultRaw" SG_ 944 HvacDisplayDefSts 3;
BA_ "SignalCategory" SG_ 944 HvacDisplayDefSts 13;
BA_ "SignalCategory" SG_ 944 HvacDisplayPopupCmd 13;
BA_ "GenSigSendType" SG_ 944 HvacDisplayPopupCmd 4;
BA_ "CmxSigDefaultRaw" SG_ 944 HvacDisplayIonSts 3;
BA_ "SignalCategory" SG_ 944 HvacDisplayIonSts 13;
BA_ "CmxSigDefaultRaw" SG_ 944 HvacDisplaySyncSts 3;
BA_ "SignalCategory" SG_ 944 HvacDisplaySyncSts 13;
BA_ "CmxSigDefaultRaw" SG_ 944 HvacDisplayRecSts 3;
BA_ "SignalCategory" SG_ 944 HvacDisplayRecSts 13;
BA_ "CmxSigDefaultRaw" SG_ 944 HvacDisplayACSts 3;
BA_ "SignalCategory" SG_ 944 HvacDisplayACSts 13;
BA_ "CmxSigDefaultRaw" SG_ 944 HvacDisplayOffSts 3;
BA_ "SignalCategory" SG_ 944 HvacDisplayOffSts 13;
BA_ "CmxSigDefaultRaw" SG_ 944 HvacDisplayAutoSts 3;
BA_ "SignalCategory" SG_ 944 HvacDisplayAutoSts 13;
BA_ "CmxSigDefaultRaw" SG_ 944 HvacDisplayBlowerStep 15;
BA_ "SignalCategory" SG_ 944 HvacDisplayBlowerStep 12;
BA_ "CmxSigDefaultRaw" SG_ 944 HvacDisplayMode 15;
BA_ "SignalCategory" SG_ 944 HvacDisplayMode 13;
BA_ "CmxSigDefaultRaw" SG_ 944 HvacDisplayTempPs 255;
BA_ "SignalCategory" SG_ 944 HvacDisplayTempPs 13;
BA_ "GenSigStartValue" SG_ 944 HvacDisplayTempPs 1;
BA_ "CmxSigDefaultRaw" SG_ 944 HvacDisplayTempDr 255;
BA_ "SignalCategory" SG_ 944 HvacDisplayTempDr 13;
BA_ "GenSigStartValue" SG_ 944 HvacDisplayTempDr 1;
BA_ "GenSigStartValue" SG_ 807 MCU_PowerConsumption 300;
BA_ "CmxSigDefaultRaw" SG_ 807 HighPowerVoltage 2047;
BA_ "CmxSigDefaultRaw" SG_ 807 HighPowerCurrent 16383;
BA_ "GenSigStartValue" SG_ 807 HighPowerCurrent 8192;
BA_ "SignalCategory" SG_ 1393 TxErrCnt_SBWS_PCAN 13;
BA_ "SignalCategory" SG_ 1393 SupplyVolt_SBWS_PCAN 14;
BA_ "SignalCategory" SG_ 1393 RxErrCnt_SBWS_PCAN 13;
BA_ "SignalCategory" SG_ 1393 MsgAliveCnt_SBWS_PCAN 14;
BA_ "SignalCategory" SG_ 1393 DTCInfo_SBWS_PCAN 13;
BA_ "SignalCategory" SG_ 1393 CMXVersion_SBWS_PCAN 12;
BA_ "SignalCategory" SG_ 1393 BusOffCnt_SBWS_PCAN 14;
BA_ "SignalCategory" SG_ 1913 DGN_SBWS_RESP 12;
BA_ "CmxSigDefaultRaw" SG_ 851 BMS_BHC_Power 65535;
BA_ "CmxSigDefaultRaw" SG_ 851 BMS_InstantPowerConsumption 4000;
BA_ "GenSigStartValue" SG_ 851 BMS_InstantPowerConsumption 4000;
BA_ "CmxSigDefaultRaw" SG_ 882 RainDetected 3;
BA_ "SignalCategory" SG_ 882 RainDetected 13;
BA_ "CmxSigDefaultRaw" SG_ 836 VessSoundSetSts 1;
BA_ "GenSigSendType" SG_ 836 VessSoundSetSts 4;
BA_ "SignalCategory" SG_ 836 VesstWarnCmd 12;
BA_ "GenSigSendType" SG_ 836 VesstWarnCmd 4;
BA_ "CmxSigDefaultRaw" SG_ 836 VessWelcomeOnOffSetSts 1;
BA_ "GenSigSendType" SG_ 836 VessWelcomeOnOffSetSts 4;
BA_ "SignalCategory" SG_ 1394 MsgAliveCnt_VESS_PCAN 14;
BA_ "GenSigStartValue" SG_ 1394 MsgAliveCnt_VESS_PCAN 254;
BA_ "SignalCategory" SG_ 1394 BusOffCnt_VESS_PCAN 14;
BA_ "SignalCategory" SG_ 1394 TxErrCnt_VESS_PCAN 13;
BA_ "SignalCategory" SG_ 1394 RxErrCnt_VESS_PCAN 13;
BA_ "SignalCategory" SG_ 1394 SupplyVolt_VESS_PCAN 14;
BA_ "SignalCategory" SG_ 1394 DTCInfo_VESS_PCAN 13;
BA_ "SignalCategory" SG_ 1394 CMXVersion_VESS_PCAN 12;
BA_ "SignalCategory" SG_ 1905 DGN_SBWS_REQ 12;
BA_ "GenSigStartValue" SG_ 854 HVAC_Sensor_DUCT 400;
BA_ "GenSigStartValue" SG_ 854 HVAC_Sensor_EVA 400;
BA_ "GenSigStartValue" SG_ 854 HVAC_Sensor_AMB 400;
BA_ "GenSigStartValue" SG_ 492 AC_REF_OutHEX_Temp 40;
BA_ "GenSigStartValue" SG_ 492 AC_REF_Low_Temp 40;
BA_ "GenSigStartValue" SG_ 492 AC_REF_High_Temp 40;
BA_ "SignalCategory" SG_ 1894 DGN_REQ_EHVC 12;
BA_ "SignalCategory" SG_ 1893 DGN_REQ_EGP 12;
BA_ "SignalCategory" SG_ 1892 DGN_REQ_OBC 12;
BA_ "SignalCategory" SG_ 1891 DGN_REQ_LDC 12;
BA_ "SignalCategory" SG_ 1890 DGN_REQ_MCU 12;
BA_ "SignalCategory" SG_ 1889 DGN_REQ_BMS 12;
BA_ "SignalCategory" SG_ 1857 DGN_REQ_VESS 12;
BA_ "CmxSigDefaultRaw" SG_ 519 DRIVER_REQ_PRESSURE 65535;
BA_ "CmxSigDefaultRaw" SG_ 519 REGEN_REQ_TQ 8191;
BA_ "GenSigStartValue" SG_ 519 REGEN_REQ_TQ 500;
BA_ "SignalCategory" SG_ 519 Counter_204h 12;
BA_ "GenSigStartValue" SG_ 853 HVAC_SetTemp_STS_R 5;
BA_ "GenSigStartValue" SG_ 853 HVAC_SetTemp_STS_L 5;
BA_ "GenSigStartValue" SG_ 831 Cabin_HTR_Coolant_Temp 40;
BA_ "SignalCategory" SG_ 488 Counter_1E8h 12;
BA_ "SignalCategory" SG_ 488 Checksum_1E8h 12;
BA_ "SignalCategory" SG_ 487 Counter_1E7h 12;
BA_ "SignalCategory" SG_ 487 Checksum_1E7h 12;
BA_ "CmxSigDefaultRaw" SG_ 487 SBWS_STS_Parking_Release_SW 15;
BA_ "CmxSigDefaultRaw" SG_ 487 SBWS_Lever 15;
BA_ "CmxSigDefaultRaw" SG_ 929 LDC_STS_CURR_OUT 65535;
BA_ "CmxSigDefaultRaw" SG_ 929 LDC_STS_CURR_IN 255;
BA_ "CmxSigDefaultRaw" SG_ 929 LDC_STS_VOLT_OUT 255;
BA_ "CmxSigDefaultRaw" SG_ 929 LDC_STS_VOLT_IN 65535;
BA_ "SignalCategory" SG_ 928 Counter_3A0h 12;
BA_ "SignalCategory" SG_ 928 Checksum_3A0h 12;
BA_ "CmxSigDefaultRaw" SG_ 928 LDC_STS_TEMP 255;
BA_ "GenSigStartValue" SG_ 928 LDC_STS_TEMP 40;
BA_ "CmxSigDefaultRaw" SG_ 928 LDC_STS_Power_OUT 255;
BA_ "CmxSigDefaultRaw" SG_ 803 BMS_AuxBattery 120;
BA_ "CmxSigDefaultRaw" SG_ 803 BMS_BHC_STS_WHU_WT_O 100;
BA_ "GenSigStartValue" SG_ 803 BMS_BHC_STS_WHU_WT_O 67;
BA_ "CmxSigDefaultRaw" SG_ 803 BMS_BatteryAvgTemperature 60;
BA_ "GenSigStartValue" SG_ 803 BMS_BatteryAvgTemperature 40;
BA_ "CmxSigDefaultRaw" SG_ 803 BMS_BatteryMaxTemperature 60;
BA_ "GenSigStartValue" SG_ 803 BMS_BatteryMaxTemperature 40;
BA_ "CmxSigDefaultRaw" SG_ 803 BMS_BatteryMinTemperature 60;
BA_ "GenSigStartValue" SG_ 803 BMS_BatteryMinTemperature 40;
BA_ "GenSigStartValue" SG_ 830 eComp_Inverter_Temp 40;
BA_ "SignalCategory" SG_ 940 CruiseTargetKPH 12;
BA_ "SignalCategory" SG_ 940 CruiseTargetMPH 12;
BA_ "SignalCategory" SG_ 940 DrivingMode_VCU 12;
BA_ "CmxSigDefaultRaw" SG_ 940 DrivingModeDisplay 3;
BA_ "SignalCategory" SG_ 940 DrivingModeDisplay 14;
BA_ "SignalCategory" SG_ 581 Counter_245h 12;
BA_ "SignalCategory" SG_ 581 Checksum_245h 12;
BA_ "SignalCategory" SG_ 467 VCU_ChargeConnectionStatus 12;
BA_ "SignalCategory" SG_ 467 Counter_1D3h 12;
BA_ "SignalCategory" SG_ 467 Checksum_1D3h 12;
BA_ "CmxSigDefaultRaw" SG_ 467 CoastRegenTorque 65535;
BA_ "GenSigStartValue" SG_ 467 CoastRegenTorque 32760;
BA_ "SignalCategory" SG_ 466 Counter_1D2h 12;
BA_ "SignalCategory" SG_ 466 Checksum_1D2h 12;
BA_ "SignalCategory" SG_ 466 VCU_REQ_Brake_Light_On 12;
BA_ "CmxSigDefaultRaw" SG_ 466 VCU_CMD_LDC_TARGT_VOLT 255;
BA_ "GW_TimeoutValue" SG_ 466 VCU_CMD_LDC_TARGT_VOLT 13;
BA_ "NmNetworkRequestHoldingTime" SG_ 466 VCU_CMD_LDC_TARGT_VOLT 13;
BA_ "UndefinedValueRangeBegin" SG_ 466 VCU_CMD_LDC_TARGT_VOLT 13;
BA_ "SignalCategory" SG_ 466 VCU_CMD_LDC_TARGT_VOLT 13;
BA_ "CmxSigDefaultRaw" SG_ 466 VCU_STS_REGN_AVAIL_TQ 65535;
BA_ "SignalCategory" SG_ 466 VCU_STS_REGN_AVAIL_TQ 13;
BA_ "SignalCategory" SG_ 465 Checksum_1D1h 12;
BA_ "SignalCategory" SG_ 465 Counter_1D1h 12;
BA_ "CmxSigDefaultRaw" SG_ 465 VCU_CMD_AC_CHARG_TARGT_CURNT 65535;
BA_ "SignalCategory" SG_ 465 VCU_CMD_AC_CHARG_TARGT_CURNT 13;
BA_ "CmxSigDefaultRaw" SG_ 465 VCU_CMD_AC_CHARG_TARGT_VOLT 65535;
BA_ "SignalCategory" SG_ 465 VCU_CMD_AC_CHARG_TARGT_VOLT 13;
BA_ "SignalCategory" SG_ 584 RemoteStartSts 12;
BA_ "CmxSigDefaultRaw" SG_ 464 VoiceHvacTempUpDnCmd 15;
BA_ "SignalCategory" SG_ 464 VoiceHvacTempUpDnCmd 12;
BA_ "GenSigSendType" SG_ 464 VoiceHvacTempUpDnCmd 4;
BA_ "CmxSigDefaultRaw" SG_ 464 VoiceHvacBlowerUpDnCmd 15;
BA_ "SignalCategory" SG_ 464 VoiceHvacBlowerUpDnCmd 12;
BA_ "GenSigSendType" SG_ 464 VoiceHvacBlowerUpDnCmd 4;
BA_ "CmxSigDefaultRaw" SG_ 464 VoiceHvacBlowerSetCmd 15;
BA_ "SignalCategory" SG_ 464 VoiceHvacBlowerSetCmd 12;
BA_ "GenSigSendType" SG_ 464 VoiceHvacBlowerSetCmd 4;
BA_ "CmxSigDefaultRaw" SG_ 464 VoiceHvacTempSetCmd 255;
BA_ "SignalCategory" SG_ 464 VoiceHvacTempSetCmd 13;
BA_ "GenSigSendType" SG_ 464 VoiceHvacTempSetCmd 4;
BA_ "SignalCategory" SG_ 464 VoiceHvacCmd 12;
BA_ "GenSigSendType" SG_ 464 VoiceHvacCmd 4;
BA_ "CmxSigDefaultRaw" SG_ 464 VoiceHvacRecCmd 15;
BA_ "SignalCategory" SG_ 464 VoiceHvacRecCmd 12;
BA_ "GenSigSendType" SG_ 464 VoiceHvacRecCmd 4;
BA_ "CmxSigDefaultRaw" SG_ 458 RemoteHvacCntrlFailReason 15;
BA_ "SignalCategory" SG_ 458 RemoteHvacCntrlFailReason 12;
BA_ "SignalCategory" SG_ 458 RemoteHvacCntrlResp 12;
BA_ "GenSigSendType" SG_ 458 RemoteHvacCntrlResp 2;
BA_ "SignalCategory" SG_ 458 HvacDrTempSetSts 13;
BA_ "GenSigStartValue" SG_ 458 HvacDrTempSetSts 5;
BA_ "SignalCategory" SG_ 458 HvacDefSts 12;
BA_ "SignalCategory" SG_ 450 RemoteHvacDefoggerCmd 12;
BA_ "SignalCategory" SG_ 450 RemoteHvacDefCmd 12;
BA_ "SignalCategory" SG_ 450 RemoteHvacCntrlCmd 12;
BA_ "GenSigSendType" SG_ 450 RemoteHvacCntrlCmd 2;
BA_ "CmxSigDefaultRaw" SG_ 450 RemoteHvacDrTempSet 255;
BA_ "SignalCategory" SG_ 450 RemoteHvacDrTempSet 13;
BA_ "GenSigStartValue" SG_ 450 RemoteHvacDrTempSet 5;
BA_ "SignalCategory" SG_ 1597 TPMS_Debug 12;
BA_ "GenSigSendType" SG_ 1597 TPMS_Debug 1;
BA_ "SignalCategory" SG_ 304 CR_Yrs_Crc1 12;
BA_ "SignalCategory" SG_ 304 CR_Yrs_MsgCnt1 12;
BA_ "CmxSigDefaultRaw" SG_ 304 CR_Yrs_LatAc 32768;
BA_ "SignalCategory" SG_ 304 CR_Yrs_LatAc 13;
BA_ "GenSigStartValue" SG_ 304 CR_Yrs_LatAc 32768;
BA_ "CmxSigDefaultRaw" SG_ 304 CR_Yrs_Yr 32768;
BA_ "SignalCategory" SG_ 304 CR_Yrs_Yr 13;
BA_ "GenSigStartValue" SG_ 304 CR_Yrs_Yr 32768;
BA_ "SignalCategory" SG_ 320 CR_Yrs_MsgCnt2 12;
BA_ "SignalCategory" SG_ 320 CR_Yrs_Crc2 12;
BA_ "SignalCategory" SG_ 320 CR_Yrs_Temp 12;
BA_ "GenSigStartValue" SG_ 320 CR_Yrs_Temp 68;
BA_ "CmxSigDefaultRaw" SG_ 320 CR_Yrs_LongAc 32768;
BA_ "SignalCategory" SG_ 320 CR_Yrs_LongAc 13;
BA_ "GenSigStartValue" SG_ 320 CR_Yrs_LongAc 32768;
BA_ "CmxSigDefaultRaw" SG_ 1416 VC_4WD 3;
BA_ "SignalCategory" SG_ 1416 VC_4WD 12;
BA_ "CmxSigDefaultRaw" SG_ 1416 VC_TPMS 3;
BA_ "SignalCategory" SG_ 1416 VC_TPMS 12;
BA_ "CmxSigDefaultRaw" SG_ 1416 VC_STPM 3;
BA_ "SignalCategory" SG_ 1416 VC_STPM 12;
BA_ "CmxSigDefaultRaw" SG_ 1416 VC_SKM 3;
BA_ "SignalCategory" SG_ 1416 VC_SKM 12;
BA_ "CmxSigDefaultRaw" SG_ 1416 VC_RHD 3;
BA_ "CmxSigDefaultRaw" SG_ 1416 VC_Audio 3;
BA_ "SignalCategory" SG_ 1416 VC_Audio 12;
BA_ "CmxSigDefaultRaw" SG_ 1416 VC_AT 3;
BA_ "SignalCategory" SG_ 1416 VC_AT 12;
BA_ "CmxSigDefaultRaw" SG_ 1416 VC_EPS 3;
BA_ "SignalCategory" SG_ 1416 VC_EPS 12;
BA_ "CmxSigDefaultRaw" SG_ 1416 VC_BS 3;
BA_ "SignalCategory" SG_ 1416 VC_BS 12;
BA_ "SignalCategory" SG_ 1416 Brake_Variant 12;
BA_ "CmxSigDefaultRaw" SG_ 1416 VC_Validity 3;
BA_ "SignalCategory" SG_ 1416 VC_Validity 12;
BA_ "CmxSigDefaultRaw" SG_ 1416 VC_Project 3;
BA_ "SignalCategory" SG_ 1416 VC_Project 12;
BA_ "CmxSigDefaultRaw" SG_ 1416 VC_DOM 3;
BA_ "SignalCategory" SG_ 1416 VC_DOM 12;
BA_ "CmxSigDefaultRaw" SG_ 1416 VC_CCU 3;
BA_ "SignalCategory" SG_ 1416 VC_CCU 12;
BA_ "CmxSigDefaultRaw" SG_ 1416 VC_PTG 3;
BA_ "SignalCategory" SG_ 1416 VC_PTG 12;
BA_ "CmxSigDefaultRaw" SG_ 1416 VC_BSD 3;
BA_ "SignalCategory" SG_ 1416 VC_BSD 12;
BA_ "CmxSigDefaultRaw" SG_ 1416 VC_WPC 3;
BA_ "SignalCategory" SG_ 1416 VC_WPC 12;
BA_ "SignalCategory" SG_ 1352 BusOffCnt_CGW_PCAN 14;
BA_ "SignalCategory" SG_ 1352 CMXVersion_CGW_PCAN 12;
BA_ "SignalCategory" SG_ 1352 DTCInfo_CGW_PCAN 13;
BA_ "SignalCategory" SG_ 1352 MsgAliveCnt_CGW_PCAN 14;
BA_ "SignalCategory" SG_ 1352 RxErrCnt_CGW_PCAN 13;
BA_ "SignalCategory" SG_ 1352 SupplyVolt_CGW_PCAN 14;
BA_ "SignalCategory" SG_ 1352 TxErrCnt_CGW_PCAN 13;
BA_ "SignalCategory" SG_ 1902 DGN_RESP_EHVC 12;
BA_ "SignalCategory" SG_ 1901 DGN_RESP_EGP 12;
BA_ "SignalCategory" SG_ 1900 DGN_RESP_OBC 12;
BA_ "SignalCategory" SG_ 1899 DGN_RESP_LDC 12;
BA_ "SignalCategory" SG_ 1898 DGN_RESP_MCU 12;
BA_ "SignalCategory" SG_ 352 Counter_160h 12;
BA_ "SignalCategory" SG_ 352 Checksum_160h 12;
BA_ "SignalCategory" SG_ 352 DrivingModeSW 14;
BA_ "SignalCategory" SG_ 352 StrgHeatSW 14;
BA_ "SignalCategory" SG_ 352 PaddleDownSW 14;
BA_ "SignalCategory" SG_ 352 PaddleUpSW 14;
BA_ "SignalCategory" SG_ 352 ACC_DistanceSW 14;
BA_ "SignalCategory" SG_ 352 ACC_Decel_SET_SW 14;
BA_ "SignalCategory" SG_ 352 ACC_Accel_RES_SW 14;
BA_ "SignalCategory" SG_ 352 SpeedLimitSW 14;
BA_ "SignalCategory" SG_ 352 ACC_SW 14;
BA_ "SignalCategory" SG_ 1381 TxErrCnt_EGP_PCAN 13;
BA_ "SignalCategory" SG_ 1381 SupplyVolt_EGP_PCAN 14;
BA_ "SignalCategory" SG_ 1381 RxErrCnt_EGP_PCAN 13;
BA_ "SignalCategory" SG_ 1381 MsgAliveCnt_EGP_PCAN 14;
BA_ "SignalCategory" SG_ 1381 DTCInfo_EGP_PCAN 13;
BA_ "SignalCategory" SG_ 1381 CMXVersion_EGP_PCAN 12;
BA_ "SignalCategory" SG_ 1381 BusOffCnt_EGP_PCAN 14;
BA_ "SignalCategory" SG_ 1382 TxErrCnt_EHVC_PCAN 13;
BA_ "SignalCategory" SG_ 1382 SupplyVolt_EHVC_PCAN 14;
BA_ "SignalCategory" SG_ 1382 RxErrCnt_EHVC_PCAN 13;
BA_ "SignalCategory" SG_ 1382 MsgAliveCnt_EHVC_PCAN 14;
BA_ "SignalCategory" SG_ 1382 DTCInfo_EHVC_PCAN 13;
BA_ "SignalCategory" SG_ 1382 CMXVersion_EHVC_PCAN 12;
BA_ "SignalCategory" SG_ 1382 BusOffCnt_EHVC_PCAN 14;
BA_ "CmxSigDefaultRaw" SG_ 353 STPMStartCmd 255;
BA_ "GwSigLatencyTime" SG_ 353 STPMStartCmd 0;
BA_ "SignalCategory" SG_ 353 STPMStartCmd 13;
BA_ "GenSigSendType" SG_ 353 STPMStartCmd 4;
BA_ "SignalCategory" SG_ 353 STPMHvacCmd 12;
BA_ "GenSigSendType" SG_ 353 STPMHvacCmd 4;
BA_ "SignalCategory" SG_ 353 STPMLightOnOffCmd 12;
BA_ "GenSigSendType" SG_ 353 STPMLightOnOffCmd 4;
BA_ "SignalCategory" SG_ 353 STPMDoorLockUnlockCmd 12;
BA_ "GenSigSendType" SG_ 353 STPMDoorLockUnlockCmd 4;
BA_ "SignalCategory" SG_ 353 STPMTailgateOpenCloseCmd 12;
BA_ "GenSigSendType" SG_ 353 STPMTailgateOpenCloseCmd 4;
BA_ "GenSigSendType" SG_ 353 BatteryCheckReqCmd 4;
BA_ "GenSigSendType" SG_ 353 STPMFobAuthentiCmd 4;
BA_ "SignalCategory" SG_ 1897 DGN_RESP_BMS 12;
BA_ "SignalCategory" SG_ 1865 DGN_RESP_VESS 12;
BA_ "SignalCategory" SG_ 601 NICC_Opt 13;
BA_ "SignalCategory" SG_ 601 NICC_SysState 12;
BA_ "SignalCategory" SG_ 601 Counter_259h 12;
BA_ "SignalCategory" SG_ 601 ACC_Disp_Information 12;
BA_ "SignalCategory" SG_ 601 ACC_DrvSel_Distance 12;
BA_ "SignalCategory" SG_ 601 ACC_DrvSel_Speed 12;
BA_ "SignalCategory" SG_ 601 ACC_WarningLamp 12;
BA_ "SignalCategory" SG_ 601 ACC_DriveMode 12;
BA_ "SignalCategory" SG_ 601 ACC_Mode 12;
BA_ "SignalCategory" SG_ 277 SKM_Immo 12;
BA_ "GenSigSendType" SG_ 277 SKM_Immo 1;
BA_ "SignalCategory" SG_ 864 Counter_360h 12;
BA_ "SignalCategory" SG_ 864 ESP_CtrMode 12;
BA_ "CmxSigDefaultRaw" SG_ 864 STR_TQR_REQ 2048;
BA_ "SignalCategory" SG_ 864 STR_TQR_REQ 12;
BA_ "GenSigStartValue" SG_ 864 STR_TQR_REQ 2048;
BA_ "SignalCategory" SG_ 864 ESC_mode 12;
BA_ "SignalCategory" SG_ 864 AVH_DRIVER_WARNING 12;
BA_ "SignalCategory" SG_ 864 AVH_LAMP_INFO 12;
BA_ "SignalCategory" SG_ 864 AVH_CTL_STATUS 12;
BA_ "SignalCategory" SG_ 864 HDC_WL 12;
BA_ "SignalCategory" SG_ 864 HDC_FL 12;
BA_ "SignalCategory" SG_ 832 Counter_340h 12;
BA_ "SignalCategory" SG_ 832 EPB_Fail_Info 12;
BA_ "SignalCategory" SG_ 832 EPB_Status 12;
BA_ "SignalCategory" SG_ 832 EPB_Switch 12;
BA_ "SignalCategory" SG_ 832 EPB_Display 12;
BA_ "SignalCategory" SG_ 832 EPB_Alarm 12;
BA_ "SignalCategory" SG_ 832 EPB_Fail_Lamp 12;
BA_ "SignalCategory" SG_ 832 EPB_Info_Lamp 12;
BA_ "SignalCategory" SG_ 1378 RxErrCnt_MCU_PCAN 13;
BA_ "SignalCategory" SG_ 1378 CMXVersion_MCU_PCAN 12;
BA_ "SignalCategory" SG_ 1377 RxErrCnt_BMS_PCAN 13;
BA_ "CmxSigDefaultRaw" SG_ 1377 MsgAliveCnt_BMS_PCAN 254;
BA_ "SignalCategory" SG_ 1377 CMXVersion_BMS_PCAN 12;
BA_ "SignalCategory" SG_ 1044 NM_CommandCode_VCU 12;
BA_ "SignalCategory" SG_ 1976 DGN_RESP_ECALL 12;
BA_ "SignalCategory" SG_ 1968 DGN_REQ_ECALL 12;
BA_ "CmxSigDefaultRaw" SG_ 481 MotorTorqueEstimated_RS1 65535;
BA_ "GenSigStartValue" SG_ 481 MotorTorqueEstimated_RS1 32760;
BA_ "CmxSigDefaultRaw" SG_ 481 MotorTorqueEstimated 65535;
BA_ "GenSigStartValue" SG_ 481 MotorTorqueEstimated 32768;
BA_ "CmxSigDefaultRaw" SG_ 481 MotorSpeed 65535;
BA_ "GenSigStartValue" SG_ 481 MotorSpeed 32767;
BA_ "SignalCategory" SG_ 481 Counter_1E1h 12;
BA_ "CmxSigDefaultRaw" SG_ 937 OBC_DC_Output_I 65535;
BA_ "CmxSigDefaultRaw" SG_ 937 OBC_DC_Output_V 65535;
BA_ "CmxSigDefaultRaw" SG_ 937 OBC_AC_I_rms 65535;
BA_ "CmxSigDefaultRaw" SG_ 937 OBC_AC_V_rms 65535;
BA_ "CmxSigDefaultRaw" SG_ 936 OBC_STS_TEMP 255;
BA_ "GenSigStartValue" SG_ 936 OBC_STS_TEMP 40;
BA_ "SignalCategory" SG_ 336 VessWelcomeOnOffSetCmd 12;
BA_ "GenSigSendType" SG_ 336 VessWelcomeOnOffSetCmd 4;
BA_ "SignalCategory" SG_ 336 LongTermParkSetCmd 12;
BA_ "GenSigSendType" SG_ 336 LongTermParkSetCmd 4;
BA_ "SignalCategory" SG_ 336 SafetyUnlockSetCmd 12;
BA_ "GenSigSendType" SG_ 336 SafetyUnlockSetCmd 4;
BA_ "SignalCategory" SG_ 336 TSRSetCmd 13;
BA_ "GenSigSendType" SG_ 336 TSRSetCmd 4;
BA_ "SignalCategory" SG_ 336 SDWSetCmd 12;
BA_ "GenSigSendType" SG_ 336 SDWSetCmd 4;
BA_ "SignalCategory" SG_ 336 DDWSetCmd 12;
BA_ "GenSigSendType" SG_ 336 DDWSetCmd 4;
BA_ "SignalCategory" SG_ 336 ACC_DriveMode_SetCmd 12;
BA_ "GenSigSendType" SG_ 336 ACC_DriveMode_SetCmd 4;
BA_ "SignalCategory" SG_ 336 ACCwSteerSetCmd 12;
BA_ "GenSigSendType" SG_ 336 ACCwSteerSetCmd 4;
BA_ "SignalCategory" SG_ 336 LKASSetCmd 13;
BA_ "GenSigSendType" SG_ 336 LKASSetCmd 4;
BA_ "SignalCategory" SG_ 336 ComeHomeLampSetCmd 12;
BA_ "GenSigSendType" SG_ 336 ComeHomeLampSetCmd 4;
BA_ "SignalCategory" SG_ 336 PTGSmartSetCmd 12;
BA_ "GenSigSendType" SG_ 336 PTGSmartSetCmd 4;
BA_ "SignalCategory" SG_ 336 DoorUnlockSetCmd 12;
BA_ "GenSigSendType" SG_ 336 DoorUnlockSetCmd 4;
BA_ "SignalCategory" SG_ 336 DoorLockSetCmd 12;
BA_ "GenSigSendType" SG_ 336 DoorLockSetCmd 4;
BA_ "GenSigSendType" SG_ 336 FactoryModeSetCmd 4;
BA_ "SignalCategory" SG_ 336 LeaveHomeLampSetCmd 12;
BA_ "GenSigSendType" SG_ 336 LeaveHomeLampSetCmd 4;
BA_ "SignalCategory" SG_ 336 DoorLockSpeedSetCmd 12;
BA_ "GenSigSendType" SG_ 336 DoorLockSpeedSetCmd 4;
BA_ "SignalCategory" SG_ 336 AutoLockSetCmd 12;
BA_ "GenSigSendType" SG_ 336 AutoLockSetCmd 4;
BA_ "SignalCategory" SG_ 336 AutoApproachSetCmd 12;
BA_ "GenSigSendType" SG_ 336 AutoApproachSetCmd 4;
BA_ "SignalCategory" SG_ 336 ApproachLampSetCmd 12;
BA_ "GenSigSendType" SG_ 336 ApproachLampSetCmd 4;
BA_ "SignalCategory" SG_ 336 AlarmBuzzSetCmd 12;
BA_ "GenSigSendType" SG_ 336 AlarmBuzzSetCmd 4;
BA_ "GenSigSendType" SG_ 336 WPCSetCmd 4;
BA_ "SignalCategory" SG_ 336 PTGModeSetCmd 13;
BA_ "GenSigSendType" SG_ 336 PTGModeSetCmd 4;
BA_ "SignalCategory" SG_ 336 FCWSetCmd 13;
BA_ "GenSigSendType" SG_ 336 FCWSetCmd 4;
BA_ "SignalCategory" SG_ 336 AEBSetCmd 13;
BA_ "GenSigSendType" SG_ 336 AEBSetCmd 4;
BA_ "SignalCategory" SG_ 336 VessSoundSetCmd 12;
BA_ "GenSigSendType" SG_ 336 VessSoundSetCmd 4;
BA_ "SignalCategory" SG_ 336 FVSASetCmd 13;
BA_ "GenSigSendType" SG_ 336 FVSASetCmd 4;
BA_ "SignalCategory" SG_ 1356 TxErrCnt_SKM_PCAN 13;
BA_ "SignalCategory" SG_ 1356 SupplyVolt_SKM_PCAN 14;
BA_ "SignalCategory" SG_ 1356 RxErrCnt_SKM_PCAN 13;
BA_ "SignalCategory" SG_ 1356 MsgAliveCnt_SKM_PCAN 14;
BA_ "SignalCategory" SG_ 1356 DTCInfo_SKM_PCAN 13;
BA_ "SignalCategory" SG_ 1356 CMXVersion_SKM_PCAN 12;
BA_ "SignalCategory" SG_ 1356 BusOffCnt_SKM_PCAN 14;
BA_ "SignalCategory" SG_ 1303 TxErrCnt_HVAC_PCAN 13;
BA_ "SignalCategory" SG_ 1303 SupplyVolt_HVAC_PCAN 14;
BA_ "SignalCategory" SG_ 1303 RxErrCnt_HVAC_PCAN 13;
BA_ "SignalCategory" SG_ 1303 MsgAliveCnt_HVAC_PCAN 14;
BA_ "SignalCategory" SG_ 1303 DTCInfo_HVAC_PCAN 13;
BA_ "SignalCategory" SG_ 1303 CMXVersion_HVAC_PCAN 12;
BA_ "SignalCategory" SG_ 1303 BusOffCnt_HVAC_PCAN 14;
BA_ "SignalCategory" SG_ 1300 TxErrCnt_VCU_PCAN 13;
BA_ "SignalCategory" SG_ 1300 SupplyVolt_VCU_PCAN 14;
BA_ "SignalCategory" SG_ 1300 RxErrCnt_VCU_PCAN 13;
BA_ "SignalCategory" SG_ 1300 MsgAliveCnt_VCU_PCAN 14;
BA_ "GenSigStartValue" SG_ 1300 MsgAliveCnt_VCU_PCAN 254;
BA_ "SignalCategory" SG_ 1300 DTCInfo_VCU_PCAN 13;
BA_ "SignalCategory" SG_ 1300 CMXVersion_VCU_PCAN 12;
BA_ "SignalCategory" SG_ 1300 BusOffCnt_VCU_PCAN 14;
BA_ "SignalCategory" SG_ 1299 TxErrCnt_ABS_PCAN 13;
BA_ "SignalCategory" SG_ 1299 SupplyVolt_ABS_PCAN 14;
BA_ "SignalCategory" SG_ 1299 RxErrCnt_ABS_PCAN 13;
BA_ "SignalCategory" SG_ 1299 MsgAliveCnt_ABS_PCAN 14;
BA_ "SignalCategory" SG_ 1299 DTCInfo_ABS_PCAN 13;
BA_ "SignalCategory" SG_ 1299 CMXVersion_ABS_PCAN 12;
BA_ "SignalCategory" SG_ 1299 BusOffCnt_ABS_PCAN 14;
BA_ "SignalCategory" SG_ 1299 Brake_Variant 12;
BA_ "SignalCategory" SG_ 1345 SupplyVolt_BCM_PCAN 14;
BA_ "SignalCategory" SG_ 1345 RxErrCnt_BCM_PCAN 13;
BA_ "SignalCategory" SG_ 1345 MsgAliveCnt_BCM_PCAN 14;
BA_ "SignalCategory" SG_ 1345 DTCInfo_BCM_PCAN 13;
BA_ "SignalCategory" SG_ 1345 CMXVersion_BCM_PCAN 12;
BA_ "SignalCategory" SG_ 1345 BusOffCnt_BCM_PCAN 14;
BA_ "SignalCategory" SG_ 1345 TxErrCnt_BCM_PCAN 13;
BA_ "SignalCategory" SG_ 821 PAB_On 12;
BA_ "GenSigStartValue" SG_ 821 PAB_On 1;
BA_ "SignalCategory" SG_ 821 PAB_Off 12;
BA_ "GenSigStartValue" SG_ 821 PAB_Off 1;
BA_ "CmxSigDefaultRaw" SG_ 821 Airbag_WL 1;
BA_ "SignalCategory" SG_ 821 Airbag_WL 12;
BA_ "GenSigStartValue" SG_ 821 Airbag_WL 1;
BA_ "SignalCategory" SG_ 309 Counter_135h 12;
BA_ "SignalCategory" SG_ 309 Checksum_135h 12;
BA_ "GenSigSendType" SG_ 309 ACU_Crashout 1;
BA_ "CmxSigDefaultRaw" SG_ 565 RearDefoggerSwSts 3;
BA_ "SignalCategory" SG_ 565 RearDefoggerSwSts 14;
BA_ "GenSigStartValue" SG_ 565 Incar_Temp 60;
BA_ "GenSigStartValue" SG_ 565 HVAC_Target_Discharge_Temp_L 400;
BA_ "GenSigStartValue" SG_ 565 HVAC_Target_Discharge_Temp_R 400;
BA_ "SignalCategory" SG_ 2012 DGN_ACU_Pmode_Response 12;
BA_ "SignalCategory" SG_ 2004 DGN_ACU_Pmode_Reqeuest 12;
BA_ "SignalCategory" SG_ 2041 DGN_ACU_Scrap_Response 12;
BA_ "SignalCategory" SG_ 2033 DGN_ACU_Scrap_Request 12;
BA_ "SignalCategory" SG_ 2011 DGN_RESP_ACU 12;
BA_ "SignalCategory" SG_ 2003 DGN_REQ_ACU 12;
BA_ "SignalCategory" SG_ 1289 TxErrCnt_ACU_PCAN 13;
BA_ "SignalCategory" SG_ 1289 SupplyVolt_ACU_PCAN 14;
BA_ "SignalCategory" SG_ 1289 RxErrCnt_ACU_PCAN 13;
BA_ "SignalCategory" SG_ 1289 MsgAliveCnt_ACU_PCAN 14;
BA_ "SignalCategory" SG_ 1289 DTCInfo_ACU_PCAN 13;
BA_ "SignalCategory" SG_ 1289 CMXVersion_ACU_PCAN 12;
BA_ "SignalCategory" SG_ 1289 BusOffCnt_ACU_PCAN 14;
BA_ "SignalCategory" SG_ 1328 TMPIR 12;
BA_ "SignalCategory" SG_ 1328 TMPI_S 12;
BA_ "SignalCategory" SG_ 1328 TAS_F 12;
BA_ "SignalCategory" SG_ 1328 TAS_R 12;
BA_ "SignalCategory" SG_ 1328 TP_RR 13;
BA_ "SignalCategory" SG_ 1328 TP_RL 13;
BA_ "SignalCategory" SG_ 1328 TP_FR 13;
BA_ "SignalCategory" SG_ 1328 TP_FL 13;
BA_ "SignalCategory" SG_ 1328 TPS_RL 12;
BA_ "SignalCategory" SG_ 1328 TPS_RR 12;
BA_ "SignalCategory" SG_ 1328 TPS_FL 12;
BA_ "SignalCategory" SG_ 1328 TPS_FR 12;
BA_ "CmxSigDefaultRaw" SG_ 1379 BusOffCnt_LDC_PCAN 254;
BA_ "SignalCategory" SG_ 1379 BusOffCnt_LDC_PCAN 14;
BA_ "SignalCategory" SG_ 1379 TxErrCnt_LDC_PCAN 13;
BA_ "CmxSigDefaultRaw" SG_ 1379 SupplyVoltage_LDC_PCAN 254;
BA_ "SignalCategory" SG_ 1379 SupplyVoltage_LDC_PCAN 14;
BA_ "SignalCategory" SG_ 1379 RxErrCnt_LDC_PCAN 13;
BA_ "CmxSigDefaultRaw" SG_ 1379 MsgAliveCnt_LDC_PCAN 254;
BA_ "SignalCategory" SG_ 1379 MsgAliveCnt_LDC_PCAN 14;
BA_ "SignalCategory" SG_ 1379 DTCInfo_LDC_PCAN 13;
BA_ "CmxSigDefaultRaw" SG_ 1379 CMXVersion_LDC_PCAN 336;
BA_ "SignalCategory" SG_ 1379 CMXVersion_LDC_PCAN 12;
BA_ "SignalCategory" SG_ 1380 BusOffCnt_OBC_PCAN 14;
BA_ "SignalCategory" SG_ 1380 CMXVersion_OBC_PCAN 12;
BA_ "SignalCategory" SG_ 1380 DTCInfo_OBC_PCAN 13;
BA_ "SignalCategory" SG_ 1380 MsgAliveCnt_OBC_PCAN 14;
BA_ "SignalCategory" SG_ 1380 RxErrCnt_OBC_PCAN 13;
BA_ "SignalCategory" SG_ 1380 SupplyVolt_OBC_PCAN 14;
BA_ "SignalCategory" SG_ 1380 TxErrCnt_OBC_PCAN 13;
BA_ "CmxSigDefaultRaw" SG_ 1298 OCV 4095;
BA_ "SignalCategory" SG_ 1298 OCV 13;
BA_ "CmxSigDefaultRaw" SG_ 1298 Norminal_Capacity 255;
BA_ "CmxSigDefaultRaw" SG_ 1298 FSOH 3;
BA_ "SignalCategory" SG_ 1298 FSOH 14;
BA_ "CmxSigDefaultRaw" SG_ 1298 FSOC 3;
BA_ "SignalCategory" SG_ 1298 FSOC 14;
BA_ "CmxSigDefaultRaw" SG_ 1297 RearDefoggerINDCmd 3;
BA_ "SignalCategory" SG_ 1297 RearDefoggerINDCmd 14;
BA_ "SignalCategory" SG_ 1297 FrtSeatBeltWarnCmd 12;
BA_ "CmxSigDefaultRaw" SG_ 1297 RearLHSeatBeltSts 2;
BA_ "CmxSigDefaultRaw" SG_ 1297 RearCntSeatBeltSts 2;
BA_ "CmxSigDefaultRaw" SG_ 1297 RearRHSeatBeltSts 2;
BA_ "CmxSigDefaultRaw" SG_ 1297 PsgnrSeatBeltSts 2;
BA_ "SignalCategory" SG_ 1297 DrivDoorAjarSts4P 11;
BA_ "CmxSigDefaultRaw" SG_ 1297 DRLSts 3;
BA_ "SignalCategory" SG_ 1297 DRLSts 14;
BA_ "CmxSigDefaultRaw" SG_ 1297 RearDefoggerActSts 3;
BA_ "SignalCategory" SG_ 1297 RearDefoggerActSts 14;
BA_ "CmxSigDefaultRaw" SG_ 1297 HeadLightOnOff4P 3;
BA_ "SignalCategory" SG_ 1297 HeadLightOnOff4P 14;
BA_ "CmxSigDefaultRaw" SG_ 1297 FrontWiperMotorSts4P 3;
BA_ "SignalCategory" SG_ 1297 FrontWiperMotorSts4P 14;
BA_ "CmxSigDefaultRaw" SG_ 1297 HoodAjarSts4p 2;
BA_ "SignalCategory" SG_ 1297 HoodAjarSts4p 11;
BA_ "GenSigStartValue" SG_ 1297 HoodAjarSts4p 2;
BA_ "CmxSigDefaultRaw" SG_ 1297 DrivSeatBeltSts 2;
BA_ "CmxSigDefaultRaw" SG_ 1296 SOH 255;
BA_ "SignalCategory" SG_ 1296 SOH 13;
BA_ "CmxSigDefaultRaw" SG_ 1296 U_Batt 16383;
BA_ "SignalCategory" SG_ 1296 U_Batt 13;
BA_ "GenSigStartValue" SG_ 1296 U_Batt 12000;
BA_ "CmxSigDefaultRaw" SG_ 1296 T_Batt 511;
BA_ "SignalCategory" SG_ 1296 T_Batt 13;
BA_ "GenSigStartValue" SG_ 1296 T_Batt 80;
BA_ "CmxSigDefaultRaw" SG_ 1296 SOC 255;
BA_ "SignalCategory" SG_ 1296 SOC 13;
BA_ "CmxSigDefaultRaw" SG_ 1296 BS_Invalid 3;
BA_ "SignalCategory" SG_ 1296 BS_Invalid 14;
BA_ "SignalCategory" SG_ 1296 I_range 12;
BA_ "CmxSigDefaultRaw" SG_ 1296 I_Batt 65535;
BA_ "SignalCategory" SG_ 1296 I_Batt 13;
BA_ "GenSigStartValue" SG_ 1296 I_Batt 65535;
BA_ "SignalCategory" SG_ 1992 DGN_RESP_ABS 12;
BA_ "SignalCategory" SG_ 1984 DGN_REQ_ABS 12;
BA_ "SignalCategory" SG_ 272 SKM110_Byte7 12;
BA_ "SignalCategory" SG_ 272 SKM110_Byte6 12;
BA_ "SignalCategory" SG_ 272 SKM110_Byte5_2 12;
BA_ "SignalCategory" SG_ 272 SKM110_Byte5_1 12;
BA_ "SignalCategory" SG_ 272 SKM110_Byte4 12;
BA_ "SignalCategory" SG_ 272 SKM110_Byte3 12;
BA_ "SignalCategory" SG_ 272 SKM110_Byte2 12;
BA_ "SignalCategory" SG_ 272 SKM110_Byte0 12;
BA_ "CmxSigDefaultRaw" SG_ 272 ModeByte 255;
BA_ "SignalCategory" SG_ 272 ModeByte 12;
BA_ "GenSigStartValue" SG_ 272 ModeByte 255;
BA_ "SignalCategory" SG_ 1746 TPMS_CAL_RESP 12;
BA_ "GenSigSendType" SG_ 1746 TPMS_CAL_RESP 1;
BA_ "SignalCategory" SG_ 1682 TPMS_CAL_REQ 12;
BA_ "CmxSigDefaultRaw" SG_ 817 GIER_ROH 65535;
BA_ "SignalCategory" SG_ 817 GIER_ROH 13;
BA_ "CmxSigDefaultRaw" SG_ 817 LONG_ACCEL 255;
BA_ "SignalCategory" SG_ 817 LONG_ACCEL 13;
BA_ "GenSigStartValue" SG_ 817 LONG_ACCEL 127;
BA_ "CmxSigDefaultRaw" SG_ 817 PS_MEANVAL 65535;
BA_ "SignalCategory" SG_ 817 PS_MEANVAL 13;
BA_ "CmxSigDefaultRaw" SG_ 817 LAT_ACCEL 2047;
BA_ "SignalCategory" SG_ 817 LAT_ACCEL 13;
BA_ "GenSigStartValue" SG_ 817 LAT_ACCEL 1023;
BA_ "SignalCategory" SG_ 522 ACC_Engine_Torque_Value 12;
BA_ "GenSigStartValue" SG_ 522 ACC_Engine_Torque_Value 1667;
BA_ "SignalCategory" SG_ 561 SAS_Speed 13;
BA_ "CmxSigDefaultRaw" SG_ 561 SAS_Angle 65535;
BA_ "SignalCategory" SG_ 561 SAS_Angle 13;
BA_ "SignalCategory" SG_ 772 Counter_304h 12;
BA_ "SignalCategory" SG_ 772 Checksum_304h 12;
BA_ "SignalCategory" SG_ 772 Rheo_Stat_Level 12;
BA_ "SignalCategory" SG_ 772 Airbag_WL_Fb 12;
BA_ "CmxSigDefaultRaw" SG_ 772 KM16 65535;
BA_ "CmxSigDefaultRaw" SG_ 772 OM_High 15;
BA_ "SignalCategory" SG_ 771 Checksum_303h 12;
BA_ "SignalCategory" SG_ 771 V_ANZ 13;
BA_ "CmxSigDefaultRaw" SG_ 771 T_Outside 255;
BA_ "SignalCategory" SG_ 771 T_Outside 13;
BA_ "GenSigStartValue" SG_ 771 T_Outside 80;
BA_ "SignalCategory" SG_ 771 Counter_303h 12;
BA_ "CmxSigDefaultRaw" SG_ 771 Speed_Combi 1023;
BA_ "SignalCategory" SG_ 771 Speed_Combi 13;
BA_ "CmxSigDefaultRaw" SG_ 771 TANK_FS_KOMBI 255;
BA_ "SignalCategory" SG_ 529 Checksum_211h 12;
BA_ "SignalCategory" SG_ 529 Counter_211h 12;
BA_ "CmxSigDefaultRaw" SG_ 529 SMC_E_S 7;
BA_ "CmxSigDefaultRaw" SG_ 529 M_FEV 8191;
BA_ "SignalCategory" SG_ 529 M_FEV 13;
BA_ "CmxSigDefaultRaw" SG_ 529 PW 255;
BA_ "SignalCategory" SG_ 529 PW 13;
BA_ "CmxSigDefaultRaw" SG_ 816 EST_REF_VELOCITY 65535;
BA_ "SignalCategory" SG_ 816 EST_REF_VELOCITY 13;
BA_ "SignalCategory" SG_ 816 Counter_330h 12;
BA_ "CmxSigDefaultRaw" SG_ 816 CPL_TQ_LIMIT 64255;
BA_ "SignalCategory" SG_ 816 RQ_Clutch_OP 13;
BA_ "SignalCategory" SG_ 768 Counter_300h 12;
BA_ "CmxSigDefaultRaw" SG_ 768 M_ESP 8191;
BA_ "SignalCategory" SG_ 768 M_ESP 13;
BA_ "CmxSigDefaultRaw" SG_ 768 SFB 3;
BA_ "CmxSigDefaultRaw" SG_ 768 MPAR_ESP 1;
BA_ "CmxSigDefaultRaw" SG_ 768 MMOTSR 255;
BA_ "CmxSigDefaultRaw" SG_ 520 SZS 1;
BA_ "CmxSigDefaultRaw" SG_ 520 MBRE_ESP 4095;
BA_ "SignalCategory" SG_ 520 MBRE_ESP 13;
BA_ "CmxSigDefaultRaw" SG_ 520 DRTGHR 3;
BA_ "CmxSigDefaultRaw" SG_ 520 DRTGHL 3;
BA_ "CmxSigDefaultRaw" SG_ 520 DHR 16383;
BA_ "SignalCategory" SG_ 520 DHR 13;
BA_ "CmxSigDefaultRaw" SG_ 520 DHL 16383;
BA_ "SignalCategory" SG_ 520 DHL 13;
BA_ "CmxSigDefaultRaw" SG_ 520 ANFN 2;
BA_ "CmxSigDefaultRaw" SG_ 512 TM_DL 16383;
BA_ "SignalCategory" SG_ 512 TM_DL 13;
BA_ "CmxSigDefaultRaw" SG_ 512 DVR 16383;
BA_ "SignalCategory" SG_ 512 DVR 13;
BA_ "CmxSigDefaultRaw" SG_ 512 DVL 16383;
BA_ "SignalCategory" SG_ 512 DVL 13;
BA_ "CmxSigDefaultRaw" SG_ 512 DRTGVL 3;
BA_ "CmxSigDefaultRaw" SG_ 512 DRTGVR 3;
BA_ "CmxSigDefaultRaw" SG_ 512 DRTGTM 3;
BA_ "CmxSigDefaultRaw" SG_ 512 BLS 3;
VAL_ 3221225472 IgnitionSts 1 "ON" 0 "OFF" ;
VAL_ 3221225472 SafetyUnlockSetSts 1 "ON" 0 "OFF" ;
VAL_ 3221225472 ESCSetCmd 5 "Sand mode (reserved)" 4 "Mud mode (reserved)" 3 "Snow mode (reserved)" 2 "Off-road mode" 1 "Normal mode" 0 "Default" ;
VAL_ 3221225472 ACC_StopReq 1 "Stop request" 0 "No request" ;
VAL_ 3221225472 ALT_FB 255 "Invalid value" ;
VAL_ 3221225472 TCU_ISGStat_ready 1 "ready" 0 "not_ready" ;
VAL_ 3221225472 NTURBINE 65535 "Invalid" ;
VAL_ 3221225472 MABS_SW_ANFB 65535 "Invalid" ;
VAL_ 3221225472 VB 65535 "Invalid" ;
VAL_ 3221225472 T_MOT 255 "Invalid value" ;
VAL_ 944 HvacDisplayDefoggerSts 3 "Invalid" 1 "On" 0 "Off" ;
VAL_ 944 HvacDisplayDefSts 3 "Invalid" 1 "On" 0 "Off" ;
VAL_ 944 HvacDisplayPopupCmd 1 "Activation" 0 "No_Activation" ;
VAL_ 944 HvacDisplayIonSts 3 "Invalid" 1 "On" 0 "Off" ;
VAL_ 944 HvacDisplaySyncSts 3 "Invalid" 1 "On" 0 "Off" ;
VAL_ 944 HvacDisplayRecSts 3 "Invalid" 1 "Rec" 0 "Fresh" ;
VAL_ 944 HvacDisplayACSts 3 "Invalid" 1 "On" 0 "Off" ;
VAL_ 944 HvacDisplayOffSts 3 "Invalid" 2 "All Display Off" 1 "Indicator On" 0 "Indicator Off" ;
VAL_ 944 HvacDisplayAutoSts 3 "Invalid" 1 "On" 0 "Off" ;
VAL_ 944 HvacDisplayBlowerStep 15 "Invalid" 8 "8Step(Max)" 7 "7Step" 6 "6Step" 5 "5Step" 4 "4Step" 3 "3Step" 2 "2Step" 1 "1Step(Low)" 0 "Off" ;
VAL_ 944 HvacDisplayMode 15 "Invalid" 13 "Auto Def" 12 "Auto Fdef" 11 "Auto Foot" 10 "Auto Bi" 9 "Auto Vent" 8 "Auto Off" 5 "Def" 4 "Fdef" 3 "Foot" 2 "Bi" 1 "Vent" 0 "Off" ;
VAL_ 944 HvacDisplayTempPs 255 "Invalid value" ;
VAL_ 944 HvacDisplayTempDr 255 "Invalid value" ;
VAL_ 807 MCU_PowerConsumption 1023 "Invalid value" ;
VAL_ 807 MCU_Service_WRN_IND 1 "ON" 0 "OFF" ;
VAL_ 1393 TxErrCnt_SBWS_PCAN 255 "Invalid value" ;
VAL_ 1393 SupplyVolt_SBWS_PCAN 255 "Invalid" 254 "Init" ;
VAL_ 1393 RxErrCnt_SBWS_PCAN 255 "Invalid value" ;
VAL_ 1393 MsgAliveCnt_SBWS_PCAN 255 "Invalid" 254 "Init" ;
VAL_ 1393 DTCInfo_SBWS_PCAN 3 "Invalid_Value" 2 "DTCRecordingUnitDefect" 1 "DTC_Available" 0 "No_DTC_recorded" ;
VAL_ 1393 BusOffCnt_SBWS_PCAN 255 "Invalid" 254 "Init" ;
VAL_ 941 VCU_STS_ESTM_DRV_Range_CLIMT_OFF 4095 "Invalid value" ;
VAL_ 941 VCU_Shift_CTRL_STS_WRN_MSG 6 "Check Gear shift control system" 5 "Charging Door open" 4 "Unplug vehicle to start" 3 "Park Malfunction" 2 "Neutral engaged" 1 "Park engaged" 0 "Off" ;
VAL_ 941 VCU_Shift_COND_Unmatch_WRN_MSG 4 "Press brake pedal with P release switch" 3 "Shift to P after stopping" 2 "Press brake Pedal to change gear" 1 "Shifting Condition not met(Speed/RPM)" 0 "Off" ;
VAL_ 941 VCU_Charging_Sts_WRN_MSG 4 "Charging System Fault" 3 "Charging Cable Inlet Fault" 2 "DC Charging System Fault" 1 "AC Charging System Fault" 0 "Off" ;
VAL_ 941 VCU_LV_SYS_WRN_MSG 2 "Check the LV System" 1 "Aux. Battery Saver Activated" 0 "Off" ;
VAL_ 941 VCU_HV_PWR_LMT_WRN_MSG 3 "Power Limited" 2 "Charge Immediately" 1 "Traction Battery Low" 0 "Off" ;
VAL_ 941 VCU_Total_CHARG_PWR 4095 "Invalid value" ;
VAL_ 941 VCU_HV_DISP_SOC 255 "Invalid value" ;
VAL_ 941 VCU_EV_Power_Down_WRN_IND 1 "ON" 0 "OFF" ;
VAL_ 941 VCU_HV_Low_SOC_WRN_IND 1 "ON" 0 "OFF" ;
VAL_ 941 VCU_LV_System_WRN_IND 1 "ON" 0 "OFF" ;
VAL_ 851 BMS_BHC_Power 65535 "Invalid" ;
VAL_ 851 BMS_InstantPowerConsumption 65535 "Invalid" ;
VAL_ 882 GoodbyeSoundCmd 3 "Invalid" 1 "Activation" 0 "No_Activation" ;
VAL_ 882 WelcomeSoundCmd 3 "Invalid" 1 "Activation" 0 "No_Activation" ;
VAL_ 882 HazardSw 1 "ON" 0 "OFF" ;
VAL_ 882 HeadLampHighSts 1 "ON" 0 "OFF" ;
VAL_ 882 RainDetected 3 "Invalid" 1 "Detected" 0 "No" ;
VAL_ 836 VessSoundSetSts 3 "Invalid" 2 "Sound2" 1 "Sound1" 0 "NotUsed" ;
VAL_ 836 VesstWarnCmd 1 "ON" 0 "OFF" ;
VAL_ 836 VessWelcomeOnOffSetSts 3 "Invalid" 2 "On" 1 "Off" 0 "NotUsed" ;
VAL_ 1394 MsgAliveCnt_VESS_PCAN 255 "Invalid" 254 "Init" ;
VAL_ 1394 BusOffCnt_VESS_PCAN 255 "Invalid" 254 "Init" ;
VAL_ 1394 TxErrCnt_VESS_PCAN 255 "Invalid value" ;
VAL_ 1394 RxErrCnt_VESS_PCAN 255 "Invalid value" ;
VAL_ 1394 SupplyVolt_VESS_PCAN 255 "Invalid" 254 "Init" ;
VAL_ 1394 DTCInfo_VESS_PCAN 3 "Invalid_Value" 2 "DTCRecordingUnitDefect" 1 "DTC_Available" 0 "No_DTC_recorded" ;
VAL_ 854 HVAC_Sensor_DUCT 65535 "Invalid" ;
VAL_ 854 HVAC_Sensor_EVA 65535 "Invalid" ;
VAL_ 854 HVAC_Sensor_AMB 65535 "Invalid" ;
VAL_ 854 HVAC_Sensor_ADS 255 "Invalid value" ;
VAL_ 519 REGEN_EXIT_MONITORING 5 "RBC Fail" 4 "ABS/ESC Act" 3 "quick turn" 2 "high decel or quick brake" 1 "wheel slip" 0 "No_Activation" ;
VAL_ 519 DRIVER_REQ_PRESSURE 65535 "Invalid" ;
VAL_ 519 PTS_SNS_FAIL 1 "fail" 0 "no fail" ;
VAL_ 519 PTS_CAL_STS 1 "Yes" 0 "No" ;
VAL_ 519 REQ_COAST_REGEN_EXIT 1 "ExitCoastRegen1_Ramp1_ReturnLev1" 0 "NoActivation" ;
VAL_ 519 REGEN_REQ_TQ 8191 "Invalid value" ;
VAL_ 519 REGEN_ENABLE_STS 1 "Enable" 0 "Inhitition" ;
VAL_ 519 RBC_KL 1 "ON" 0 "OFF" ;
VAL_ 519 BBC_KL 1 "ON" 0 "OFF" ;
VAL_ 519 RBC_DEF 1 "Defective" 0 "Normal" ;
VAL_ 519 BBC_DEF 2 "Defective" 1 "Degraded" 0 "Normal" ;
VAL_ 853 HVAC_MODE_DEF_STS 3 "Def Button" 2 "ADS" 1 "Start" 0 "Off" ;
VAL_ 853 HVAC_Error_2 1 "Error" 0 "NoError" ;
VAL_ 853 HVAC_Error_1 1 "Error" 0 "NoError" ;
VAL_ 853 HVAC_Error_BLR 1 "Error" 0 "NoError" ;
VAL_ 853 HVAC_Error_TEMP 1 "Error" 0 "NoError" ;
VAL_ 853 HVAC_SetTemp_STS_R 255 "Invalid value" ;
VAL_ 853 HVAC_SetTemp_STS_L 255 "Invalid value" ;
VAL_ 853 HVAC_Blower_STS 15 "Invalid" 8 "8Step(Max)" 7 "7Step" 6 "6Step" 5 "5Step" 4 "4Step" 3 "3Step" 2 "2Step" 1 "1Step(Low)" 0 "Off" ;
VAL_ 853 HVAC_Rec_STS 2 "Partial" 15 "Invalid" 1 "Rec" 0 "Fresh" ;
VAL_ 853 HVAC_Mode_STS 15 "Invalid" 5 "Def" 4 "FDef" 3 "Foot" 2 "Bi" 1 "Vent" 0 "Off" ;
VAL_ 853 HVAC_DEF_STS 1 "ON" 0 "OFF" ;
VAL_ 853 HVAC_HEX_ICING_STS 1 "ON" 0 "OFF" ;
VAL_ 853 HVAC_Heating_STS 1 "ON" 0 "OFF" ;
VAL_ 853 HVAC_Cooling_STS 1 "ON" 0 "OFF" ;
VAL_ 831 Error2 1 "Error" 0 "NoError" ;
VAL_ 831 Error1 1 "Error" 0 "NoError" ;
VAL_ 831 Component_Error 1 "Error" 0 "NoError" ;
VAL_ 831 Mode_Error 1 "Error" 0 "NoError" ;
VAL_ 831 Mode_Req 15 "Invalid" 5 "Def" 4 "FDef" 3 "Foot" 2 "Bi" 1 "Vent" 0 "Off" ;
VAL_ 831 Rec_Req 2 "Partial" 15 "Invalid" 1 "Rec" 0 "Fresh" ;
VAL_ 831 Blower_Step_Req 15 "Invalid" 8 "8Step(Max)" 7 "7Step" 6 "6Step" 5 "5Step" 4 "4Step" 3 "3Step" 2 "2Step" 1 "1Step(Low)" 0 "Off" ;
VAL_ 831 DATC_STS_CHILLER 1 "Activation" 0 "No_Activation" ;
VAL_ 831 EHVC_OP_Mode_Req 15 "Mode15" 14 "Mode14" 13 "Mode13" 12 "Mode12" 11 "Mode11" 10 "Mode10" 9 "Mode9" 8 "Mode8" 7 "Mode7" 6 "Mode6" 5 "Mode5" 4 "Mode4" 3 "Mode3" 2 "Mode2" 1 "Mode1" 0 "NoActivation" ;
VAL_ 488 Pmotor_Error_Level 15 "Invalid" 5 "Lv5" 4 "Lv4" 3 "Lv3" 2 "Lv2" 1 "Lv1" 0 "Lv0" ;
VAL_ 488 Pmotor_Position_Status 3 "Invalid" 2 "In Between" 1 "N" 0 "P" ;
VAL_ 488 Pmotor_Position_Failure 1 "Fault" 0 "NoFault" ;
VAL_ 488 EGP_OperationMode 4 "Error" 3 "Ready" 1 "Standby" 0 "Sleep" ;
VAL_ 488 Shifting_In_Progress 1 "Shifting" 0 "Not Shifting" ;
VAL_ 488 EGP_Service_WRN_IND 1 "ON" 0 "OFF" ;
VAL_ 487 SBW_ShutDown_Timer 1 "ON" 0 "OFF" ;
VAL_ 487 SBW_STS 1 "Service_Limphome" 0 "Normal" ;
VAL_ 487 SBWS_STS_Parking_Release_SW 3 "Invalid" 2 "Stuck" 1 "On" 0 "Off" ;
VAL_ 487 SBWS_Lever 15 "Invalid" 4 "L/M" 3 "D" 2 "N" 1 "R" 0 "P" ;
VAL_ 487 SBW_WRN_MSG 15 "Invalid" 8 "ShiftLockSwitchCheck" 7 "ParkingReleaseSwitchCheck" 6 "ParingSwitchCheck" 5 "WhenNotUsingShiftLockSW" 4 "WhenNotUsingTheBrake" 3 "WhenConditionIsNotP" 2 "CanNotChangeGear" 1 "Service" 0 "Off" ;
VAL_ 928 LDC_Service_WRN_IND 1 "ON" 0 "OFF" ;
VAL_ 928 LDC_Out_Emergency 1 "ON" 0 "OFF" ;
VAL_ 928 LDC_Out_Mode 2 "CP" 1 "CC" 0 "CV" ;
VAL_ 928 LDC_STS_MODE 3 "Derating" 2 "Failure" 1 "Fault" 0 "Normal" ;
VAL_ 928 LDC_STS_Ready 2 "invalid" 1 "ready" 0 "not ready" ;
VAL_ 803 BMS_BHC_STS_ERR 2 "Heater Internal Error" 1 "HV Heater Relay Coil Error" 0 "no_error" ;
VAL_ 803 BMS_CoolingPumpFeedbackStatus 7 "Normal working" 6 "RPM Mismatch" 5 "Over current" 4 "Over temp" 3 "STALL" 2 "Dry run signal" 1 "PWM Wire open" 0 "Not working" ;
VAL_ 803 BMS_BHC_STS_OW_TS 1 "abnormality" 0 "Normal state" ;
VAL_ 803 BMS_ChargingStop 1 "Request" 0 "NoRequest" ;
VAL_ 803 BMS_CoolingRequest 1 "Request" 0 "NoRequest" ;
VAL_ 850 BMS_BAT_STS_MSG 1 "ON" 0 "OFF" ;
VAL_ 850 HV_BAT_Over_Temp_MSG 1 "ON" 0 "OFF" ;
VAL_ 850 HV_BAT_Low_Temp_Power_Limit_MSG 1 "ON" 0 "OFF" ;
VAL_ 850 BMS_BatteryPackSOH 1023 "Invalid value" ;
VAL_ 850 BMS_BatteryPackSOE 1023 "Invalid value" ;
VAL_ 850 BMS_BatteryPackRSOC 1023 "Invalid value" ;
VAL_ 830 eComp_Communication_Fault 1 "Fault" 0 "NoFault" ;
VAL_ 830 eComp_Thermistor_Fault 1 "Fault" 0 "NoFault" ;
VAL_ 830 eComp_Internal_Error_Fault 1 "Fault" 0 "NoFault" ;
VAL_ 830 eComp_Missed_Restart_Fault 1 "Fault" 0 "NoFault" ;
VAL_ 830 eComp_Over_Temperature 1 "Fault" 0 "NoFault" ;
VAL_ 830 eComp_Over_Load 1 "Fault" 0 "NoFault" ;
VAL_ 830 eComp_High_Voltage_Fault 1 "Fault" 0 "NoFault" ;
VAL_ 830 eComp_Low_Voltage_Fault 1 "Fault" 0 "NoFault" ;
VAL_ 830 eComp_Line_Open_Fault 1 "Fault" 0 "NoFault" ;
VAL_ 830 eComp_HW_Fault 1 "Fault" 0 "NoFault" ;
VAL_ 940 VCU_HV_ACT_IND 3 "Invalid" 1 "On" 0 "Off" ;
VAL_ 940 VCU_IGN4_STS 1 "ON" 0 "OFF" ;
VAL_ 940 VCU_IGN3_STS 1 "ON" 0 "OFF" ;
VAL_ 940 Charging_Sts_IND 7 "Invalid" 5 "ChargingFailure(RedFlash)" 4 "ChargingComplete(Green)" 2 "Connection_NoCharging_ScheduledChargSet(Blue)" 1 "Connection_NoCharging(Yellow)" 0 "NoConnection_NoCharging(Off)" 3 "DuringCharging(GreenFlash)" ;
VAL_ 940 VCU_Service_WRN_IND 1 "ON" 0 "OFF" ;
VAL_ 940 ECO_Guide_Level_IND 31 "Invalid" 16 "Power Level 10" 15 "Power Level 9" 14 "Power Level 8" 13 "Power Level 7" 12 "Power Level 6" 11 "Power Level 5" 10 "Power Level 4" 9 "Power Level 3" 7 "Power Level 2" 6 "Power Level 1" 5 "Charging Level 5" 4 "Charging Level 4" 3 "Charging Level 3" 2 "Charging Level 2" 1 "Charging Level 1" 0 "0 Level" ;
VAL_ 940 ECO_Energy_Flow_IND 2 "Regenerative Braking" 1 "Motoring" 0 "Stop" ;
VAL_ 940 VCU_Cert_Status 1 "Activation" 0 "No_Activation" ;
VAL_ 940 Charging_DR_STS 3 "Invalid" 2 "Init" 1 "Open" 0 "Close" ;
VAL_ 940 DrivingMode_VCU 7 "Invalid" 3 "Eco+" 2 "Sports" 1 "Normal" 0 "Eco" ;
VAL_ 940 DrivingModeDisplay 1 "Display" 0 "NoDisplay" ;
VAL_ 581 DrivingPosition 7 "Invalid" 4 "L" 3 "D" 2 "N" 1 "R" 0 "P" ;
VAL_ 581 VCU_Ready 2 "Emergency(Blinking)" 1 "Ready" 0 "Not Ready" ;
VAL_ 581 Immo_light 2 "Flashing" 1 "On" 0 "Off" ;
VAL_ 467 VCU_CMD_CHAR_PD 2 "Open (Switch Pushed)" 1 "Detected" 0 "Not Detected" ;
VAL_ 467 VCU_CMD_CHAR_CP 6 "Stage F(-12V)" 5 "Stage E(0V)" 4 "Stage D(3V)" 3 "Stage C(6V)" 2 "Stage B2(9V)" 1 "Stage B1(9V)" 0 "Stage A(0V)" ;
VAL_ 467 VCU_STS_Paddle_LV 15 "Invalid" 3 "3 Level" 2 "2 Level" 1 "1 Level" 0 "O Level" ;
VAL_ 467 VCU_STS_CHARG_PLG_AT_Lock_SW 3 "Invalid" 2 "Init" 1 "Lock" 0 "Auto" ;
VAL_ 467 VCU_STS_CHARG_RLS_SW 3 "Invalid" 2 "Init" 1 "On" 0 "Off" ;
VAL_ 467 VCU_STS_VEH_Mode 7 "Invalid" 4 "12V Battery Auto Charging Mode" 3 "Quick(DC) Charging Mode" 2 "Scheduled Charging Mode" 1 "Normal(AC) Charging Mode" 0 "Standby" ;
VAL_ 467 VCU_ChargeConnectionStatus 15 "Invalid" 2 "DC Plug Connected" 1 "AC Plug Connected" 0 "Disconnected" ;
VAL_ 467 VCU_CMD_AC_CHARG_ST_REQ 2 "HaltCharging" 1 "StartCharging" 0 "StopCharging" ;
VAL_ 466 VCU_EPBoperatingReq 1 "Request" 0 "NoRequest" ;
VAL_ 466 VCU_REQ_Brake_Light_On 1 "ON" 0 "OFF" ;
VAL_ 466 VCU_REQ_LMT_CABN_Heater_PWR 1 "Activation" 0 "No_Activation" ;
VAL_ 466 VCU_REQ_LMT_ACOMP_PWR 1 "Activation" 0 "No_Activation" ;
VAL_ 466 VCU_REQ_LMT_Blower_Step 1 "Activation" 0 "No_Activation" ;
VAL_ 466 VCU_REQ_EN_CABN_Heater 1 "enable" 0 "disable" ;
VAL_ 466 VCU_REQ_EN_ACOMP 1 "enable" 0 "disable" ;
VAL_ 466 VCU_CMD_EN_LDC 1 "enable" 0 "disable" ;
VAL_ 466 VCU_STS_REGN_AVAIL_TQ 65535 "Invalid" ;
VAL_ 466 VCU_STS_REGN_AVAIL_STS_EPT 1 "Enable" 0 "Inhitition" ;
VAL_ 465 VCU_CMD_EN_OBC 1 "enable" 0 "disable" ;
VAL_ 465 VCU_CMD_AC2_CHARG_CRT_SET 2 "Maximum" 1 "Minimum" 0 "Medium" ;
VAL_ 465 VCU_CMD_AC1_CHARG_CRT_SET 2 "Maximum" 1 "Minimum" 0 "Medium" ;
VAL_ 465 AC_Charging_Ready 2 "Charging Finish" 1 "Ready" 0 "NotReady" ;
VAL_ 584 RemoteStartSts 3 "Invalid" 1 "RemoteRunningSts" 0 "NormalState" ;
VAL_ 464 VoiceHvacTempUpDnCmd 2 "DnStep" 1 "UpStep" 0 "NoActivation" ;
VAL_ 464 VoiceHvacBlowerUpDnCmd 2 "DnStep" 1 "UpStep" 0 "NoActivation" ;
VAL_ 464 VoiceHvacBlowerSetCmd 15 "NoAct_Invalid" 8 "8Step(Max)" 7 "7Step" 6 "6Step" 5 "5Step" 4 "4Step" 3 "3Step" 2 "2Step" 1 "1Step(Low)" 0 "Off" ;
VAL_ 464 VoiceHvacTempSetCmd 255 "Invalid value" ;
VAL_ 464 VoiceHvacCmd 6 "Defrost_On" 5 "Defrost_Off" 4 "HVAC_On_with_AC_ON" 3 "HVAC_On_with_AC_OFF" 2 "HVAC_On_with_AUTO" 1 "HVAC_OFF" 0 "NoActivation" ;
VAL_ 464 VoiceHvacRecCmd 2 "RecircleAir" 1 "FreshAir" 0 "NoActivation" ;
VAL_ 458 RemoteHvacCntrlFailReason 15 "NoFail" 14 "OtherReason" 3 "EngineStop" 2 "NormalRunningState" 1 "HvacAlreadyOff" 0 "HvacAlreayOn" ;
VAL_ 458 RemoteHvacCntrlResp 3 "HVAC_OFF_Fail" 2 "HVAC_OFF_Success" 1 "HVAC_ON_Fail" 0 "HVAN_ON_Success" ;
VAL_ 458 HvacDrTempSetSts 255 "Invalid value" ;
VAL_ 458 HvacDefSts 1 "ON" 0 "OFF" ;
VAL_ 450 RemoteHvacDefoggerCmd 1 "ON" 0 "OFF" ;
VAL_ 450 RemoteHvacDefCmd 1 "ON" 0 "OFF" ;
VAL_ 450 RemoteHvacCntrlCmd 2 "HvacOff" 1 "HvacOn" 0 "NoActivation" ;
VAL_ 450 RemoteHvacDrTempSet 255 "Invalid value" ;
VAL_ 304 CF_Yrs_MCUStat_BusOff 1 "Yes" 0 "No" ;
VAL_ 304 CF_Yrs_MCUStat_OV 1 "Yes" 0 "No" ;
VAL_ 304 CF_Yrs_MCUStat_UV 1 "Yes" 0 "No" ;
VAL_ 304 CF_Yrs_MCUStat_Fail 1 "fail" 0 "no fail" ;
VAL_ 304 CF_Yrs_LatAc_Init 1 "Yes" 0 "No" ;
VAL_ 304 CF_Yrs_LatAc_Fail 1 "fail" 0 "no fail" ;
VAL_ 304 CF_Yrs_Yr_Init 1 "Yes" 0 "No" ;
VAL_ 304 CF_Yrs_Yr_Fail 1 "fail" 0 "no fail" ;
VAL_ 304 CR_Yrs_LatAc 65535 "Invalid" ;
VAL_ 304 CR_Yrs_Yr 65535 "Invalid" ;
VAL_ 320 CF_Yrs_Type 1 "Yaw, Lateral, Longitudinal" 0 "Yaw, Lateral" ;
VAL_ 320 YRS_Temp_Stat 1 "Out -40 to 85" 0 "In -40 to 85" ;
VAL_ 320 CF_ISC_ResetStat 1 "ISC_ResetMode" 0 "NormalMode" ;
VAL_ 320 CR_Yrs_LongAc_Init 1 "Yes" 0 "No" ;
VAL_ 320 CR_Yrs_LongAc_Fail 1 "fail" 0 "no fail" ;
VAL_ 320 CR_Yrs_LongAc 65535 "Invalid" ;
VAL_ 1416 VC_4WD 3 "Default" 2 "Yes" 0 "No" ;
VAL_ 1416 VC_TPMS 3 "Default" 2 "Yes" 0 "No" ;
VAL_ 1416 VC_STPM 3 "Default" 2 "Yes" 0 "No" ;
VAL_ 1416 VC_SKM 3 "Default" 2 "Yes" 0 "No" ;
VAL_ 1416 VC_RHD 3 "Default(Virgin)" 1 "Right Hand Drive" 0 "Left Hand Drive" ;
VAL_ 1416 VC_Audio 3 "Default" 2 "Yes" 0 "No" ;
VAL_ 1416 VC_AT 3 "Default" 2 "Yes" 0 "No" ;
VAL_ 1416 VC_EPS 3 "Default" 2 "Yes" 0 "No" ;
VAL_ 1416 VC_BS 3 "Default" 2 "Yes" 0 "No" ;
VAL_ 1416 Brake_Variant 5 "ESP+EPB+AEB+ACC" 4 "ESP+EPB+AEB" 3 "ESP+AEB" 2 "ESP+EPB" 1 "ESP" 0 "ABS" ;
VAL_ 1416 VC_Validity 3 "Default" 2 "Yes" 0 "No" ;
VAL_ 1416 VC_Project 22 "E100" ;
VAL_ 1416 VC_DOM 2 "EU export vehicle" 1 "general export vehicle" 0 "domestic vehicle" ;
VAL_ 1416 VC_CCU 3 "Default" 2 "Yes" 0 "No" ;
VAL_ 1416 VC_PTG 3 "Default" 2 "Yes" 0 "No" ;
VAL_ 1416 VC_BSD 3 "Default" 2 "Yes" 0 "No" ;
VAL_ 1416 VC_WPC 3 "Default" 2 "Yes" 0 "No" ;
VAL_ 1352 BusOffCnt_CGW_PCAN 255 "Invalid" 254 "Init" ;
VAL_ 1352 DTCInfo_CGW_PCAN 3 "Invalid_Value" 2 "DTCRecordingUnitDefect" 1 "DTC_Available" 0 "No_DTC_recorded" ;
VAL_ 1352 MsgAliveCnt_CGW_PCAN 255 "Invalid" 254 "Init" ;
VAL_ 1352 RxErrCnt_CGW_PCAN 255 "Invalid value" ;
VAL_ 1352 SupplyVolt_CGW_PCAN 255 "Invalid" 254 "Init" ;
VAL_ 1352 TxErrCnt_CGW_PCAN 255 "Invalid value" ;
VAL_ 352 DrivingModeSW 3 "Invalid" 2 "Init" 1 "On" 0 "Off" ;
VAL_ 352 StrgHeatSW 3 "Invalid" 2 "Init" 1 "On" 0 "Off" ;
VAL_ 352 PaddleDownSW 3 "Invalid" 2 "Init" 1 "On" 0 "Off" ;
VAL_ 352 PaddleUpSW 3 "Invalid" 2 "Init" 1 "On" 0 "Off" ;
VAL_ 352 ACC_DistanceSW 3 "Invalid" 2 "Init" 1 "Pressed" 0 "NotPressed" ;
VAL_ 352 ACC_Decel_SET_SW 3 "Invalid" 2 "Init" 1 "Pressed" 0 "NotPressed" ;
VAL_ 352 ACC_Accel_RES_SW 3 "Invalid" 2 "Init" 1 "Pressed" 0 "NotPressed" ;
VAL_ 352 SpeedLimitSW 3 "Invalid" 2 "Init" 1 "Pressed" 0 "NotPressed" ;
VAL_ 352 ACC_SW 3 "Invalid" 2 "Init" 1 "Pressed" 0 "NotPressed" ;
VAL_ 1381 TxErrCnt_EGP_PCAN 255 "Invalid value" ;
VAL_ 1381 SupplyVolt_EGP_PCAN 255 "Invalid" 254 "Init" ;
VAL_ 1381 RxErrCnt_EGP_PCAN 255 "Invalid value" ;
VAL_ 1381 MsgAliveCnt_EGP_PCAN 255 "Invalid" 254 "Init" ;
VAL_ 1381 DTCInfo_EGP_PCAN 3 "Invalid_Value" 2 "DTCRecordingUnitDefect" 1 "DTC_Available" 0 "No_DTC_recorded" ;
VAL_ 1381 BusOffCnt_EGP_PCAN 255 "Invalid" 254 "Init" ;
VAL_ 1382 TxErrCnt_EHVC_PCAN 255 "Invalid value" ;
VAL_ 1382 SupplyVolt_EHVC_PCAN 255 "Invalid" 254 "Init" ;
VAL_ 1382 RxErrCnt_EHVC_PCAN 255 "Invalid value" ;
VAL_ 1382 MsgAliveCnt_EHVC_PCAN 255 "Invalid" 254 "Init" ;
VAL_ 1382 DTCInfo_EHVC_PCAN 3 "Invalid_Value" 2 "DTCRecordingUnitDefect" 1 "DTC_Available" 0 "No_DTC_recorded" ;
VAL_ 1382 BusOffCnt_EHVC_PCAN 255 "Invalid" 254 "Init" ;
VAL_ 353 STPMStartCmd 145 "EngineStopCmd" 95 "EngineStartCmd" 0 "NoActivation" ;
VAL_ 353 STPMHvacCmd 3 "Full_Aircon" 2 "Full_Heater" 1 "Off" 0 "NoActivation" ;
VAL_ 353 STPMLightOnOffCmd 1 "Activation" 0 "No_Activation" ;
VAL_ 353 STPMDoorLockUnlockCmd 1 "Activation" 0 "No_Activation" ;
VAL_ 353 STPMTailgateOpenCloseCmd 1 "Activation" 0 "No_Activation" ;
VAL_ 353 BatteryCheckReqCmd 1 "Activation" 0 "No_Activation" ;
VAL_ 353 STPMFobAuthentiCmd 1 "Activation" 0 "No_Activation" ;
VAL_ 601 NICC_Opt 3 "Invalid" 2 "On" 1 "Off" 0 "NoOption" ;
VAL_ 601 NICC_SysState 3 "Failure" 2 "Active" 1 "Ready" 0 "Off" ;
VAL_ 601 ACC_Target_Validity 1 "Valid target vehicle" 0 "No target vehicle" ;
VAL_ 601 ACC_Disp_Information 7 "Display 'Takeover Request'" 6 "Display 'Disable to engage ACC'" 5 "Display 'ACC disengaged'" 4 "Display 'Available to resume acceleration control'" 3 "Display 'Object disappeared'" 2 "Reserved" 1 "Display 'ACC Mode'" 0 "Default" ;
VAL_ 601 ACC_DrvSel_Distance 5 "Level#5" 4 "Level#4" 3 "Level#3" 2 "Level#2" 1 "Level#1" 0 "No time gap set" ;
VAL_ 601 ACC_WarningLamp 3 "ACC Service Required" 2 "System temporairy unavailable" 1 "Performance degredation" 0 "Normal state" ;
VAL_ 601 ACC_DriveMode 3 "Dynamic" 2 "Normal" 1 "Comfort" 0 "Default" ;
VAL_ 601 ACC_Mode 3 "Shutoff" 2 "Override" 1 "Engaged" 0 "Off" ;
VAL_ 601 ACC_SystemState 1 "ON" 0 "OFF" ;
VAL_ 864 ESP_CtrMode 3 "Particular_Mode" 2 "Output_Torque_Overlay_Mode" 1 "Sensor_Value_Overlay_Mode" 0 "Reserve" ;
VAL_ 864 DST_DEF 1 "Defective" 0 "Not_Defective" ;
VAL_ 864 ESC_mode 5 "Sand mode (reserved)" 4 "Mud mode (reserved)" 3 "Snow mode (reserved)" 2 "Off-road mode" 1 "Normal mode" 0 "Default" ;
VAL_ 864 AVH_DRIVER_WARNING 3 "AVH cannot be activated. Close Door, Seatbelt, Hood, Trunk" 2 "Press Brake Pedal to Release AVH" 1 "AVH to be deactivated Press Brake Pedal" 0 "No_Warning" ;
VAL_ 864 AVH_LAMP_INFO 3 "AVH Ready (lamp is on as white)" 2 "AVH Active (lamp is on as green)" 1 "AVH Failure (lamp is on as yellow)" 0 "AVH Off" ;
VAL_ 864 AVH_CTL_STATUS 2 "AVH_being_released" 1 "AVH_Active" 0 "No_Apply" ;
VAL_ 864 HDC_WL 3 "not defined" 2 "blinking" 1 "turn on" 0 "turn off" ;
VAL_ 864 HDC_FL 3 "not defined" 2 "blinking" 1 "turn on" 0 "turn off" ;
VAL_ 832 EPB_RBLRQ 1 "Activation" 0 "No_Activation" ;
VAL_ 832 EPB_Fail_Info 5 "EPB Permanently Not Available" 4 "EPB Temporarily Not Available" 3 "EPB Diagnostic" 2 "EPB Initialization State" 1 "EPB No failure" ;
VAL_ 832 EPB_Status 7 "Applying in progress by switch" 6 "Releasing in progress by switch" 5 "Dynamic braking via EPB" 4 "Releasing in progress without switch" 3 "Applying in progress without switch" 2 "Applied" 1 "Released" 0 "Unknown" ;
VAL_ 832 EPB_Switch 3 "Failure" 2 "Release" 1 "Apply" 0 "Neutral" ;
VAL_ 832 EPB_Display 5 "Push_brake_pedal_to_release_EPB" 4 "Apply_brake_immediately" 3 "EPB applies by ESC request" 2 "Driver tries to DAR but safety condition is not satisfied" 1 "EPB is in maintenance mode" 0 "Off" ;
VAL_ 832 EPB_Alarm 2 "Uncomfortable tone" 1 "Comfortable tone (Sound once)" 0 "Off" ;
VAL_ 832 EPB_Fail_Lamp 2 "Flashing" 1 "On" 0 "Off" ;
VAL_ 832 EPB_Info_Lamp 2 "Flashing" 1 "On" 0 "Off" ;
VAL_ 563 WHL_PULSE_RL 255 "Invalid value" ;
VAL_ 563 WHL_PULSE_RR 255 "Invalid value" ;
VAL_ 563 WHL_PULSE_FR 255 "Invalid value" ;
VAL_ 563 WHL_PULSE_FL 255 "Invalid value" ;
VAL_ 1378 TxErrCnt_MCU_PCAN 255 "Invalid value" ;
VAL_ 1378 SupplyVolt_MCU_PCAN 255 "Invalid" 254 "Init" ;
VAL_ 1378 RxErrCnt_MCU_PCAN 255 "Invalid value" ;
VAL_ 1378 MsgAliveCnt_MCU_PCAN 255 "Invalid" 254 "Init" ;
VAL_ 1378 DTCInfo_MCU_PCAN 3 "Invalid_Value" 2 "DTCRecordingUnitDefect" 1 "DTC_Available" 0 "No_DTC_recorded" ;
VAL_ 1378 BusOffCnt_MCU_PCAN 255 "Invalid" 254 "Init" ;
VAL_ 1377 TxErrCnt_BMS_PCAN 255 "Invalid value" ;
VAL_ 1377 SupplyVolt_BMS_PCAN 255 "Invalid" 254 "Init" ;
VAL_ 1377 RxErrCnt_BMS_PCAN 255 "Invalid value" ;
VAL_ 1377 MsgAliveCnt_BMS_PCAN 255 "Invalid" 254 "Init" ;
VAL_ 1377 DTCInfo_BMS_PCAN 3 "Invalid_Value" 2 "DTCRecordingUnitDefect" 1 "DTC_Available" 0 "No_DTC_recorded" ;
VAL_ 1377 BusOffCnt_BMS_PCAN 255 "Invalid" 254 "Init" ;
VAL_ 1044 NM_ChargeConnectionStatus_VCU 1 "Request" 0 "Release" ;
VAL_ 1044 NM_IgnitionSts_VCU 1 "Request" 0 "Release" ;
VAL_ 1044 NM_VCU_HV_ACT_IND_VCU 1 "Request" 0 "Release" ;
VAL_ 1044 NM_WakeupReason_VCU 3 "BatteryAttachment" 2 "LocalWakeup" 1 "RemoteWakeup" 0 "UnknownReason" ;
VAL_ 1044 NM_SleepFlag_VCU 3 "SleepACK" 1 "NwRelease" 0 "NwRequest" ;
VAL_ 1044 NM_FormerState_VCU 5 "LocalMode10min" 4 "LocalMode1min" 3 "LocalMode10sec" 2 "LocalModeAfterNetwork" 1 "PowerSavingMode" 0 "NoInformation" ;
VAL_ 1044 NM_CommandCode_VCU 4 "Limphome" 2 "Ring" 1 "Alive" ;
VAL_ 1096 NM_VehicleTheftSts_BCM 1 "Request" 0 "Release" ;
VAL_ 1096 NM_TailgateOutsideSwSts_BCM 1 "Request" 0 "Release" ;
VAL_ 1096 NM_TailgateAjarSts_BCM 1 "Request" 0 "Release" ;
VAL_ 1096 NM_HoodAjarSts_BCM 1 "Request" 0 "Release" ;
VAL_ 1096 NM_DoorLockUnSts_BCM 1 "Request" 0 "Release" ;
VAL_ 1096 NM_DoorAjarSts_BCM 1 "Request" 0 "Release" ;
VAL_ 1096 NM_WelcomeGoodbyeSoundCmd_BCM 1 "Request" 0 "Release" ;
VAL_ 1096 NM_IgnitionSts_CGW 1 "Request" 0 "Release" ;
VAL_ 1096 NM_BatteryCheckReqCmd_STPM 1 "Request" 0 "Release" ;
VAL_ 1096 NM_WakeupReason_CGW 3 "BatteryAttachment" 2 "LocalWakeup" 1 "RemoteWakeup" 0 "UnknownReason" ;
VAL_ 1096 NM_SleepFlag_CGW 3 "SleepACK" 1 "NwRelease" 0 "NwRequest" ;
VAL_ 1096 NM_FormerState_CGW 5 "LocalMode10min" 4 "LocalMode1min" 3 "LocalMode10sec" 2 "LocalModeAfterNetwork" 1 "PowerSavingMode" 0 "NoInformation" ;
VAL_ 1096 NM_CommandCode_CGW 4 "Limphome" 2 "Ring" 1 "Alive" ;
VAL_ 936 OBC_STS_CHECK_GROUP 8 "Temporary Stop Group" 7 "System Variable Group #2" 6 "System Variable Group #1" 5 "Warnnig Group #4" 4 "Warnnig Group #3" 3 "Warnnig Group #2" 2 "Warnnig Group #1" 1 "Fault Group" 0 "Default" ;
VAL_ 936 OBC_STS_PC_State 5 "CV Mode" 4 "CC(In) Mode" 3 "CC(Out) Mode" 2 "CP Mode" 1 "Hot Standby Mode" 0 "Idle Mode" ;
VAL_ 936 OBC_STS_SC_State 6 "Charge Finish Mode" 5 "Fault Mode" 4 "Charge Mode" 3 "Precharge Mode" 2 "Handshake Mode" 1 "Init Check Mode" 0 "Main Power Off Mode" ;
VAL_ 936 OBC_STS_Precharge_Step 5 "Precharging done(Init Done)" 4 "PFC stage enable step(Hot Stb)" 3 "Main Relay On step" 2 "Internal link check Step" 1 "HV Check Step" 0 "Idle Step" ;
VAL_ 936 OBC_STS_PWR_LIM_2 1 "Yes" 0 "No" ;
VAL_ 936 OBC_STS_PWR_LIM_1 1 "Yes" 0 "No" ;
VAL_ 936 OBC_STS_FLT 1 "Yes" 0 "No" ;
VAL_ 936 OBC_STS_WRN 1 "Yes" 0 "No" ;
VAL_ 936 OBC_STS_Temporary_Stop 1 "Yes" 0 "No" ;
VAL_ 936 OBC_STS_AC_DETECT 1 "Yes" 0 "No" ;
VAL_ 936 OBC_CMD_Chg_Finished 1 "Yes" 0 "No" ;
VAL_ 936 OBC_STS_CONTRAB 1 "Yes" 0 "No" ;
VAL_ 936 OBC_STS_Ready 1 "ready" 0 "not_ready" ;
VAL_ 336 VessWelcomeOnOffSetCmd 2 "On" 1 "Off" 0 "NoActivation" ;
VAL_ 336 LongTermParkSetCmd 2 "On" 1 "Off" 0 "NoActivation" ;
VAL_ 336 SafetyUnlockSetCmd 2 "On" 1 "Off" 0 "NoActivation" ;
VAL_ 336 TSRSetCmd 3 "Invalid" 2 "On" 1 "Off" 0 "Default" ;
VAL_ 336 SDWSetCmd 3 "Invalid" 2 "On" 1 "Off" 0 "Default" ;
VAL_ 336 DDWSetCmd 3 "Invalid" 2 "On" 1 "Off" 0 "Default" ;
VAL_ 336 ACC_DriveMode_SetCmd 3 "Dynamic" 2 "Normal" 1 "Comfort" 0 "Default" ;
VAL_ 336 ACCwSteerSetCmd 3 "Invalid" 2 "On" 1 "Off" 0 "Default" ;
VAL_ 336 LKASSetCmd 2 "LKAS(RKA)" 1 "LDWS" 0 "Default" ;
VAL_ 336 ComeHomeLampSetCmd 4 "30sec" 3 "20sec" 2 "10sec" 1 "Off" 0 "NoActivation" ;
VAL_ 336 PTGSmartSetCmd 2 "Enable" 1 "Disable" 0 "NoActivation" ;
VAL_ 336 DoorUnlockSetCmd 3 "Parking" 2 "KeyOff" 1 "Off" 0 "NoActivation" ;
VAL_ 336 DoorLockSetCmd 3 "ExceptParking" 2 "Driving" 1 "Off" 0 "NoActivation" ;
VAL_ 336 FactoryModeSetCmd 1 "Activation" 0 "No_Activation" ;
VAL_ 336 LeaveHomeLampSetCmd 4 "30sec" 3 "20sec" 2 "10sec" 1 "Off" 0 "NoActivation" ;
VAL_ 336 DoorLockSpeedSetCmd 5 "50kph" 4 "40kph" 3 "30kph" 2 "20kph" 1 "10kph" 0 "NoActivation" ;
VAL_ 336 AutoLockSetCmd 2 "On" 1 "Off" 0 "NoActivation" ;
VAL_ 336 AutoApproachSetCmd 2 "On" 1 "Off" 0 "NoActivation" ;
VAL_ 336 ApproachLampSetCmd 2 "On" 1 "Off" 0 "NoActivation" ;
VAL_ 336 AlarmBuzzSetCmd 2 "On" 1 "Off" 0 "NoActivation" ;
VAL_ 336 WPCSetCmd 2 "On" 1 "Off" 0 "NoActivation" ;
VAL_ 336 PTGModeSetCmd 3 "Invalid" 2 "ManualMode" 1 "PowerMode" 0 "Default" ;
VAL_ 336 FCWSetCmd 4 "Early" 7 "Invalid" 3 "Normal" 2 "Late" 1 "Disable" 0 "Default" ;
VAL_ 336 AEBSetCmd 3 "Invalid" 2 "On" 1 "Off" 0 "Default" ;
VAL_ 336 VessSoundSetCmd 2 "Sound2" 1 "Sound1" 0 "NoActivation" ;
VAL_ 336 FVSASetCmd 3 "Invalid" 2 "On" 1 "Off" 0 "Default" ;
VAL_ 1356 TxErrCnt_SKM_PCAN 255 "Invalid value" ;
VAL_ 1356 SupplyVolt_SKM_PCAN 255 "Invalid" 254 "Init" ;
VAL_ 1356 RxErrCnt_SKM_PCAN 255 "Invalid value" ;
VAL_ 1356 MsgAliveCnt_SKM_PCAN 255 "Invalid" 254 "Init" ;
VAL_ 1356 DTCInfo_SKM_PCAN 3 "Invalid_Value" 2 "DTCRecordingUnitDefect" 1 "DTC_Available" 0 "No_DTC_recorded" ;
VAL_ 1356 BusOffCnt_SKM_PCAN 255 "Invalid" 254 "Init" ;
VAL_ 1303 TxErrCnt_HVAC_PCAN 255 "Invalid value" ;
VAL_ 1303 SupplyVolt_HVAC_PCAN 255 "Invalid" 254 "Init" ;
VAL_ 1303 RxErrCnt_HVAC_PCAN 255 "Invalid value" ;
VAL_ 1303 MsgAliveCnt_HVAC_PCAN 255 "Invalid" 254 "Init" ;
VAL_ 1303 DTCInfo_HVAC_PCAN 3 "Invalid_Value" 2 "DTCRecordingUnitDefect" 1 "DTC_Available" 0 "No_DTC_recorded" ;
VAL_ 1303 BusOffCnt_HVAC_PCAN 255 "Invalid" 254 "Init" ;
VAL_ 1300 TxErrCnt_VCU_PCAN 255 "Invalid value" ;
VAL_ 1300 SupplyVolt_VCU_PCAN 255 "Invalid" 254 "Init" ;
VAL_ 1300 RxErrCnt_VCU_PCAN 255 "Invalid value" ;
VAL_ 1300 MsgAliveCnt_VCU_PCAN 255 "Invalid" 254 "Init" ;
VAL_ 1300 DTCInfo_VCU_PCAN 3 "Invalid_Value" 2 "DTCRecordingUnitDefect" 1 "DTC_Available" 0 "No_DTC_recorded" ;
VAL_ 1300 BusOffCnt_VCU_PCAN 255 "Invalid" 254 "Init" ;
VAL_ 1299 TxErrCnt_ABS_PCAN 255 "Invalid value" ;
VAL_ 1299 SupplyVolt_ABS_PCAN 255 "Invalid" 254 "Init" ;
VAL_ 1299 RxErrCnt_ABS_PCAN 255 "Invalid value" ;
VAL_ 1299 MsgAliveCnt_ABS_PCAN 255 "Invalid" 254 "Init" ;
VAL_ 1299 DTCInfo_ABS_PCAN 3 "Invalid_Value" 2 "DTCRecordingUnitDefect" 1 "DTC_Available" 0 "No_DTC_recorded" ;
VAL_ 1299 BusOffCnt_ABS_PCAN 255 "Invalid" 254 "Init" ;
VAL_ 1299 Brake_Variant 5 "ESP+EPB+AEB+ACC" 4 "ESP+EPB+AEB" 3 "ESP+AEB" 2 "ESP+EPB" 1 "ESP" 0 "ABS" ;
VAL_ 1345 SupplyVolt_BCM_PCAN 255 "Invalid" 254 "Init" ;
VAL_ 1345 RxErrCnt_BCM_PCAN 255 "Invalid value" ;
VAL_ 1345 MsgAliveCnt_BCM_PCAN 255 "Invalid" 254 "Init" ;
VAL_ 1345 DTCInfo_BCM_PCAN 3 "Invalid_Value" 2 "DTCRecordingUnitDefect" 1 "DTC_Available" 0 "No_DTC_recorded" ;
VAL_ 1345 BusOffCnt_BCM_PCAN 255 "Invalid" 254 "Init" ;
VAL_ 1345 TxErrCnt_BCM_PCAN 255 "Invalid value" ;
VAL_ 821 PAB_On 1 "ON" 0 "OFF" ;
VAL_ 821 PAB_Off 1 "ON" 0 "OFF" ;
VAL_ 821 Airbag_WL 3 "Invalid" 2 "Flashing" 1 "ON" 0 "OFF" ;
VAL_ 309 ACU_Crashout 1 "Activation" 0 "No_Activation" ;
VAL_ 565 RearDefoggerSwSts 1 "Activation" 0 "No_Activation" ;
VAL_ 565 HP_Req 3 "None Heatpump" 1 "Heatpump On" 0 "Heatpump Off" ;
VAL_ 565 HVAC_Option 2 "DATC" 1 "MTC" ;
VAL_ 565 Incar_Temp 255 "Invalid value" ;
VAL_ 565 HVAC_Mode_Status 2 "DEF" 1 "MAX" 0 "otherwise" ;
VAL_ 565 HvacMaxModeSts 3 "Invalid" 2 "Other_Mode" 1 "Full_Aircon_Mode" 0 "Full_Heater_Mode" ;
VAL_ 565 AC_Req 1 "ON" 0 "OFF" ;
VAL_ 565 HVAC_Target_Discharge_Temp_L 65535 "Invalid" ;
VAL_ 565 HVAC_Target_Discharge_Temp_R 65535 "Invalid" ;
VAL_ 565 HVAC_TEMP_Status 2 "Hi_Temp" 1 "Lo_Temp" 0 "Otherwise" ;
VAL_ 565 FAN_Status 1 "Activation" 0 "No_Activation" ;
VAL_ 1289 TxErrCnt_ACU_PCAN 255 "Invalid value" ;
VAL_ 1289 SupplyVolt_ACU_PCAN 255 "Invalid" 254 "Init" ;
VAL_ 1289 RxErrCnt_ACU_PCAN 255 "Invalid value" ;
VAL_ 1289 MsgAliveCnt_ACU_PCAN 255 "Invalid" 254 "Init" ;
VAL_ 1289 DTCInfo_ACU_PCAN 3 "Invalid_Value" 2 "DTCRecordingUnitDefect" 1 "DTC_Available" 0 "No_DTC_recorded" ;
VAL_ 1289 BusOffCnt_ACU_PCAN 255 "Invalid" 254 "Init" ;
VAL_ 1328 TMPIR 3 "Alert_Level_3" 0 "No_Indication" ;
VAL_ 1328 TMPI_S 11 "TPM_Warning_Flash" 10 "TPM_Warning_In_Learn_Mode" 9 "Normal_Operation_OFF" ;
VAL_ 1328 TAS_F 2 "Tire_Pressure_Imbalanced" 1 "Tire_Pressure_Balanced" 0 "Unknown" ;
VAL_ 1328 TAS_R 2 "Tire_Pressure_Imbalanced" 1 "Tire_Pressure_Balanced" 0 "Unknown" ;
VAL_ 1328 TP_RR 255 "Invalid value" ;
VAL_ 1328 TP_RL 255 "Invalid value" ;
VAL_ 1328 TP_FR 255 "Invalid value" ;
VAL_ 1328 TP_FL 255 "Invalid value" ;
VAL_ 1328 TPV_RL 1 "Invalid" 0 "Valid" ;
VAL_ 1328 TPV_RR 1 "Invalid" 0 "Valid" ;
VAL_ 1328 TPV_FL 1 "Invalid" 0 "Valid" ;
VAL_ 1328 TPV_FR 1 "Invalid" 0 "Valid" ;
VAL_ 1328 TPS_RL 7 "Invalid" 5 "High_Pressure" 4 "Puncture" 3 "Low_Warning" 2 "Low_Service_Now(Alarm)" 1 "Nominal" 0 "Unknown" ;
VAL_ 1328 TPS_RR 7 "Invalid" 5 "High_Pressure" 4 "Puncture" 3 "Low_Warning" 2 "Low_Service_Now(Alarm)" 1 "Nominal" 0 "Unknown" ;
VAL_ 1328 TPS_FL 7 "Invalid" 5 "High_Pressure" 4 "Puncture" 3 "Low_Warning" 2 "Low_Service_Now(Alarm)" 1 "Nominal" 0 "Unknown" ;
VAL_ 1328 TPS_FR 7 "Invalid" 5 "High_Pressure" 4 "Puncture" 3 "Low_Warning" 2 "Low_Service_Now(Alarm)" 1 "Nominal" 0 "Unknown" ;
VAL_ 1379 BusOffCnt_LDC_PCAN 255 "Invalid" 254 "Init" ;
VAL_ 1379 TxErrCnt_LDC_PCAN 255 "Invalid value" ;
VAL_ 1379 SupplyVoltage_LDC_PCAN 255 "Invalid" 254 "Init" ;
VAL_ 1379 RxErrCnt_LDC_PCAN 255 "Invalid value" ;
VAL_ 1379 MsgAliveCnt_LDC_PCAN 255 "Invalid" 254 "Init" ;
VAL_ 1379 DTCInfo_LDC_PCAN 3 "Invalid_Value" 2 "DTCRecordingUnitDefect" 1 "DTC_Available" 0 "No_DTC_recorded" ;
VAL_ 1380 BusOffCnt_OBC_PCAN 255 "Invalid" 254 "Init" ;
VAL_ 1380 DTCInfo_OBC_PCAN 3 "Invalid_Value" 2 "DTCRecordingUnitDefect" 1 "DTC_Available" 0 "No_DTC_recorded" ;
VAL_ 1380 MsgAliveCnt_OBC_PCAN 255 "Invalid" 254 "Init" ;
VAL_ 1380 RxErrCnt_OBC_PCAN 255 "Invalid value" ;
VAL_ 1380 SupplyVolt_OBC_PCAN 255 "Invalid" 254 "Init" ;
VAL_ 1380 TxErrCnt_OBC_PCAN 255 "Invalid value" ;
VAL_ 1298 OCV 4095 "Invalid value" ;
VAL_ 1298 Norminal_Capacity 255 "Invalid value" ;
VAL_ 1298 FSOH 3 "Invalid" 2 "Init" 1 "Error" 0 "NoError" ;
VAL_ 1298 FSOC 3 "Invalid" 2 "Init" 1 "Error" 0 "NoError" ;
VAL_ 1297 InteriorTailLampCmd 1 "Activation" 0 "No_Activation" ;
VAL_ 1297 RearDefoggerINDCmd 3 "Invalid" 2 "Init" 1 "On" 0 "Off" ;
VAL_ 1297 BrakeLampFailSts 1 "fail" 0 "no fail" ;
VAL_ 1297 FrtSeatBeltINDCmd 1 "Activation" 0 "No_Activation" ;
VAL_ 1297 RearSeatBeltWarnCmd 1 "Activation" 0 "No_Activation" ;
VAL_ 1297 FrtSeatBeltWarnCmd 2 "SBR_Activation" 1 "SBW_Activation" 0 "NoActivation" ;
VAL_ 1297 TailgateUnlatchSts 1 "Activation" 0 "No_Activation" ;
VAL_ 1297 RearDoorLockUnSts 1 "Unlock" 0 "Lock" ;
VAL_ 1297 AutoPanelDimCmd_P 1 "Activation" 0 "No_Activation" ;
VAL_ 1297 PsngrDoorLockUnSts 1 "Unlock" 0 "Lock" ;
VAL_ 1297 RearLHSeatBeltSts 2 "Unfasten, SBR on" 3 "Invalid" 1 "Fasten, SBR off" 0 "Unfasten, SBR off" ;
VAL_ 1297 RearCntSeatBeltSts 2 "Unfasten, SBR on" 3 "Invalid" 1 "Fasten, SBR off" 0 "Unfasten, SBR off" ;
VAL_ 1297 RearRHSeatBeltSts 2 "Unfasten, SBR on" 3 "Invalid" 1 "Fasten, SBR off" 0 "Unfasten, SBR off" ;
VAL_ 1297 PsgnrSeatBeltSts 3 "Invalid" 1 "Fasten" 0 "Unfasten" ;
VAL_ 1297 DrivDoorAjarSts4P 3 "Invalid" 2 "Init" 1 "Open" 0 "Close" ;
VAL_ 1297 DRLSts 3 "Invalid" 2 "Init" 1 "On" 0 "Off" ;
VAL_ 1297 RearDefoggerActSts 3 "Invalid" 2 "Init" 1 "On" 0 "Off" ;
VAL_ 1297 HeadLightOnOff4P 3 "Invalid" 2 "Init" 1 "On" 0 "Off" ;
VAL_ 1297 FrontWiperMotorSts4P 3 "Invalid" 2 "High" 1 "Low" 0 "Off" ;
VAL_ 1297 DrivDoorLockUnSts 1 "Unlock" 0 "Lock" ;
VAL_ 1297 HoodAjarSts4p 3 "Invalid" 2 "Init" 1 "Open" 0 "Close" ;
VAL_ 1297 DrivSeatBeltSts 3 "Invalid" 1 "Fasten" 0 "Unfasten" ;
VAL_ 1296 SOH 255 "Invalid value" ;
VAL_ 1296 U_Batt 16383 "Invalid" ;
VAL_ 1296 T_Batt 511 "Invalid" ;
VAL_ 1296 SOC 255 "Invalid value" ;
VAL_ 1296 BS_Invalid 3 "Invalid" 2 "Init" 1 "Error" 0 "NoError" ;
VAL_ 1296 I_range 2 "LIN_range_3" 1 "LIN_range_2" 0 "LIN_range_1" 3 "Invalid" ;
VAL_ 1296 I_Batt 65535 "Invalid" ;
VAL_ 272 ModeByte 255 "DefaultValue" ;
VAL_ 272 ST_REQ 3 "ST_REQ2" 1 "ST_REQ1" 0 "No_activation" ;
VAL_ 817 GIER_ROH 65535 "Invalid" ;
VAL_ 817 LONG_ACCEL 255 "Invalid value" ;
VAL_ 817 PS_MEANVAL 65535 "Invalid" ;
VAL_ 817 LAT_ACCEL 2047 "Invalid value" ;
VAL_ 522 ACC_Engine_Torque_Request 1 "Enable SCC torque request" 0 "No request" ;
VAL_ 522 HSA_DEF_FLG 1 "Defective" 0 "Not_Defective" ;
VAL_ 522 HSA_CTR_FLAG 1 "Activation" 0 "No_Activation" ;
VAL_ 561 SAS_CAL 1 "Calibrated" 0 "Not Calibrated" ;
VAL_ 561 SAS_OK 1 "OK" 0 "Not OK" ;
VAL_ 561 SAS_Speed 255 "Invalid value" ;
VAL_ 561 SAS_Angle 65535 "Invalid" ;
VAL_ 772 Rheo_Stat_Level 0 "NoActivation" ;
VAL_ 772 Airbag_WL_Fb 7 "Lamp circuitry failure" 3 "ACU_msg_error" 2 "Flashing" 1 "ON" 0 "OFF" ;
VAL_ 772 IG_S 1 "ignition on" 0 "ignition off" ;
VAL_ 772 KM16 65535 "Invalid" ;
VAL_ 772 Eng_Lamp_status 1 "symbol fault" 0 "symbol not fault" ;
VAL_ 772 OM_High 15 "Invalid" ;
VAL_ 771 V_ANZ 4095 "Invalid value" ;
VAL_ 771 V_MPH 1 "MPH" 0 "KPH" ;
VAL_ 771 T_Outside 255 "Invalid value" ;
VAL_ 771 Speed_Combi 1023 "Invalid value" ;
VAL_ 771 TANK_FS_KOMBI 255 "Invalid value" ;
VAL_ 771 T_OutsideInitSts 1 "OK" 0 "NotOK" ;
VAL_ 529 SMC_E_S 7 "signal not valid" 3 "charging" 2 "running" 1 "soft start" 0 "stopped" ;
VAL_ 529 VCU_transPmotorparkReq 3 "Invalid" 2 "Park Request" 1 "Unpark Request" 0 "NoRequest" ;
VAL_ 529 ACC_ACT 1 "Activation" 0 "No_Activation" ;
VAL_ 529 M_FEV 8191 "Invalid value" ;
VAL_ 529 PW_Virtual_Flag 3 "Invalid" 2 "Virtual" 1 "Actual" 0 "NoPedal" ;
VAL_ 529 SPDLIM_Ready 1 "ready" 0 "not_ready" ;
VAL_ 529 CAN_Engine_ACC_failure 1 "Activation" 0 "No_Activation" ;
VAL_ 529 CAN_Driver_Accel_Override 1 "Activation" 0 "No_Activation" ;
VAL_ 529 SPDLIM_Overspeed 1 "Activation" 0 "No_Activation" ;
VAL_ 529 SPDLIM_Override 1 "Activation" 0 "No_Activation" ;
VAL_ 529 SPDLIM_ACT 1 "Activation" 0 "No_Activation" ;
VAL_ 529 ACC_Ready 1 "ready" 0 "not_ready" ;
VAL_ 529 PW_ERR 1 "Error" 0 "NoError" ;
VAL_ 529 PW 255 "Invalid value" ;
VAL_ 816 EST_REF_VELOCITY 65535 "Invalid" ;
VAL_ 816 CPL_TQ_LIMIT 64255 "64255Nm" 0 "0" ;
VAL_ 816 RQ_Clutch_OP 3 "error" 2 "torque limit " 1 "clutch off" 0 "passive " ;
VAL_ 816 EBS_STATUS 3 "TCSactiveflag(TCScontrol=active)" 2 "ESPactiveflag(ESPcontro=active)" 1 "ABSactiveflag(ABScontrol=active)" 0 "normal mode" ;
VAL_ 768 M_ESP 8191 "Invalid value" ;
VAL_ 768 SFB 3 "signal not available" 2 "not defined_03" 1 "not defined_02" 0 "not defined_01" ;
VAL_ 768 MMOTSR 255 "Invalid value" ;
VAL_ 520 TM_AUS 1 "auto cruise off rerquest" 0 "normal" ;
VAL_ 520 SZS 3 "emission test mode" 2 "not defined" 1 "normal operation" 0 "disable ESP function or diag. mode" ;
VAL_ 520 MBRE_ESP 4095 "Invalid value" ;
VAL_ 520 DRTGHR 3 "DHR signal = invalid" 2 "not defined_02" 1 "not defined_01" 0 "DHR signal = valid" ;
VAL_ 520 DRTGHL 3 "DHL signal = invalid" 2 "not defined_02" 1 "not defined_01" 0 "DHL signal = valid" ;
VAL_ 520 DHR 16383 "Invalid" ;
VAL_ 520 DHL 16383 "Invalid" ;
VAL_ 520 ANFN 3 "not defined_03" 2 "no request" 1 "not defined_02" 0 "not defined_01" ;
VAL_ 512 ESP_OFF_KL 1 "ON" 0 "OFF" ;
VAL_ 512 ESP_BL 1 "Activation" 0 "No_Activation" ;
VAL_ 512 TM_DL 16383 "Invalid" ;
VAL_ 512 ESP_KL 3 "ESP Warning Lamp Flashing_Active" 1 "ESP Warning Lamp On_System fault" 0 "ESP Lamp off" ;
VAL_ 512 EBD_KL 1 "EBD W/L ON" 0 "EBD W/L OFF" ;
VAL_ 512 DVR 16383 "Invalid" ;
VAL_ 512 DVL 16383 "Invalid" ;
VAL_ 512 DRTGVL 3 "DVL signal = invalid" 2 "not defined_02" 1 "not defined_01" 0 "DVL signal = valid" ;
VAL_ 512 DRTGVR 3 "DVR signal = invalid" 2 "not defined_02" 1 "not defined_01" 0 "DVR signal = valid" ;
VAL_ 512 DRTGTM 3 "TM_DL signal = invalid" 2 "not defined_02" 1 "not defined_01" 0 "TM_DL signal = valid" ;
VAL_ 512 BLS 3 "signal not valid" 2 "not defined" 1 "brake operated" 0 "brake not operated" ;
VAL_ 512 ESS_INFO 1 "Activation" 0 "No_Activation" ;
VAL_ 512 ABS_KL 1 "ABS W/L ON" 0 "ABS W/L OFF" ;
